VERSION "HNNBNNNYNNNNNNNNNNNNNNNNNNNNNNNNNNNNNNNNNN/4/%%%/4/'%**4NNN///"

NS_ :

BS_:

BU_: BAP_Tester BedienDisp_mi BedienDisp_vo_mi CDI ConMod_CD DashCAM Gateway_Max ICC_IO_Node LSH OCU RDK_RS3 Sound_MIB_ab_Gen3 STH ZR_MIB_EINSTIEG_ab_Gen3 ZR_MIB_OPTION_ab_Gen3 ZR_MIB_TOP_ab_Gen3

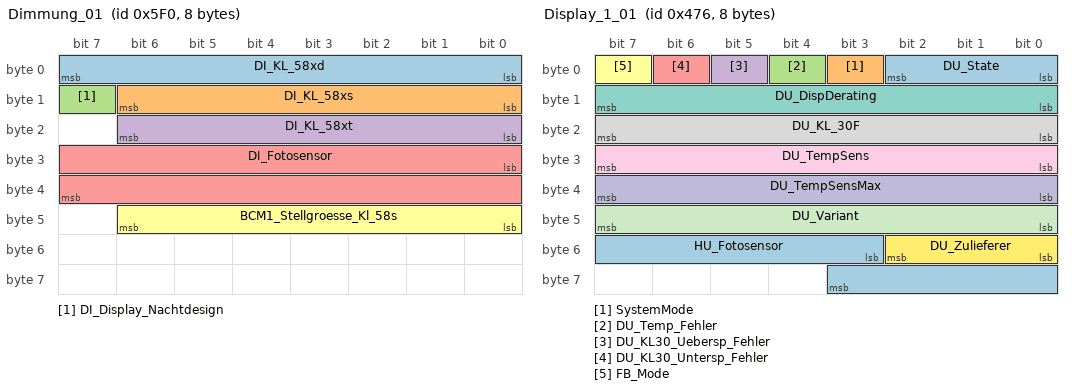
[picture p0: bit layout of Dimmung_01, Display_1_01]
BO_ 1520 Dimmung_01: 8 Gateway_Max
 SG_ DI_KL_58xd : 0|8@1+ (1,0) [0|253] ""  BedienDisp_mi,BedienDisp_vo_mi,CDI,ICC_IO_Node,OCU,ZR_MIB_EINSTIEG_ab_Gen3,ZR_MIB_OPTION_ab_Gen3,ZR_MIB_TOP_ab_Gen3
 SG_ DI_KL_58xs : 8|7@1+ (1,0) [0|100] "Unit_PerCent"  BedienDisp_vo_mi,CDI,ICC_IO_Node,OCU,ZR_MIB_EINSTIEG_ab_Gen3,ZR_MIB_OPTION_ab_Gen3,ZR_MIB_TOP_ab_Gen3
 SG_ DI_Display_Nachtdesign : 15|1@1+ (1.0,0.0) [0.0|1] ""  BedienDisp_vo_mi,CDI,ICC_IO_Node,ZR_MIB_EINSTIEG_ab_Gen3,ZR_MIB_OPTION_ab_Gen3,ZR_MIB_TOP_ab_Gen3
 SG_ DI_KL_58xt : 16|7@1+ (1,0) [0|100] "Unit_PerCent"  BedienDisp_mi,BedienDisp_vo_mi,CDI,ICC_IO_Node,OCU,ZR_MIB_EINSTIEG_ab_Gen3,ZR_MIB_OPTION_ab_Gen3,ZR_MIB_TOP_ab_Gen3
 SG_ DI_Fotosensor : 24|16@1+ (1,0) [0|65535] ""  ICC_IO_Node,OCU,ZR_MIB_EINSTIEG_ab_Gen3,ZR_MIB_OPTION_ab_Gen3,ZR_MIB_TOP_ab_Gen3
 SG_ BCM1_Stellgroesse_Kl_58s : 40|7@1+ (1,0) [0|100] ""  ICC_IO_Node,ZR_MIB_EINSTIEG_ab_Gen3,ZR_MIB_OPTION_ab_Gen3,ZR_MIB_TOP_ab_Gen3

BO_ 1142 Display_1_01: 8 ICC_IO_Node
 SG_ DU_State : 0|3@1+ (1.0,0.0) [0.0|7] ""  Gateway_Max
 SG_ SystemMode : 3|1@1+ (1.0,0.0) [0.0|1] ""  Vector__XXX
 SG_ DU_Temp_Fehler : 4|1@1+ (1.0,0.0) [0.0|1] ""  Gateway_Max
 SG_ DU_KL30_Uebersp_Fehler : 5|1@1+ (1.0,0.0) [0.0|1] ""  Gateway_Max
 SG_ DU_KL30_Untersp_Fehler : 6|1@1+ (1.0,0.0) [0.0|1] ""  Gateway_Max
 SG_ FB_Mode : 7|1@1+ (1.0,0.0) [0.0|1] ""  Vector__XXX
 SG_ DU_DispDerating : 8|8@1+ (1,0) [0|100] "Unit_PerCent"  Gateway_Max
 SG_ DU_KL_30F : 16|8@1+ (0.1,0) [0.0|25.3] "Unit_Volt"  Vector__XXX
 SG_ DU_TempSens : 24|8@1+ (1,-55) [-55|127] "Unit_DegreCelsi"  Gateway_Max
 SG_ DU_TempSensMax : 32|8@1+ (1,-55) [-55|127] "Unit_DegreCelsi"  Vector__XXX
 SG_ DU_Variant : 40|8@1+ (1,0) [0|253] ""  Vector__XXX
 SG_ DU_Zulieferer : 48|3@1+ (1,0) [0|7] ""  Vector__XXX
 SG_ HU_Fotosensor : 51|9@1+ (0.25,0) [0.00|100.00] "Unit_PerCent"  Vector__XXX

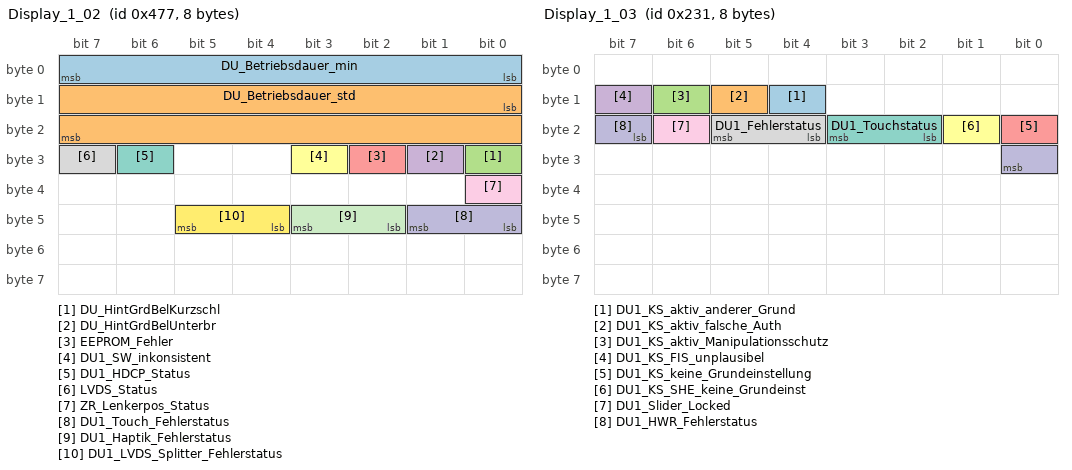
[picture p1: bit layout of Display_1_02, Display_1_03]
BO_ 1143 Display_1_02: 8 ICC_IO_Node
 SG_ DU_Betriebsdauer_min : 0|8@1+ (1,0) [0|59] "Unit_Minut"  Vector__XXX
 SG_ DU_Betriebsdauer_std : 8|16@1+ (1,0) [0|65533] "Unit_Hours"  Vector__XXX
 SG_ DU_HintGrdBelKurzschl : 24|1@1+ (1.0,0.0) [0.0|1] ""  Gateway_Max
 SG_ DU_HintGrdBelUnterbr : 25|1@1+ (1.0,0.0) [0.0|1] ""  Gateway_Max
 SG_ EEPROM_Fehler : 26|1@1+ (1.0,0.0) [0.0|1] ""  Vector__XXX
 SG_ DU1_SW_inkonsistent : 27|1@1+ (1.0,0.0) [0.0|1] ""  Gateway_Max
 SG_ DU1_HDCP_Status : 30|1@1+ (1.0,0.0) [0.0|1] ""  Vector__XXX
 SG_ LVDS_Status : 31|1@1+ (1.0,0.0) [0.0|1] ""  Gateway_Max
 SG_ ZR_Lenkerpos_Status : 32|1@1+ (1.0,0.0) [0.0|1] ""  Vector__XXX
 SG_ DU1_Touch_Fehlerstatus : 40|2@1+ (1.0,0.0) [0.0|3] ""  Gateway_Max
 SG_ DU1_Haptik_Fehlerstatus : 42|2@1+ (1.0,0.0) [0.0|3] ""  Gateway_Max
 SG_ DU1_LVDS_Splitter_Fehlerstatus : 44|2@1+ (1.0,0.0) [0.0|3] ""  Vector__XXX

BO_ 561 Display_1_03: 8 ICC_IO_Node
 SG_ DU1_KS_aktiv_anderer_Grund : 12|1@1+ (1.0,0.0) [0.0|1] ""  Vector__XXX
 SG_ DU1_KS_aktiv_falsche_Auth : 13|1@1+ (1.0,0.0) [0.0|1] ""  Vector__XXX
 SG_ DU1_KS_aktiv_Manipulationsschutz : 14|1@1+ (1.0,0.0) [0.0|1] ""  Vector__XXX
 SG_ DU1_KS_FIS_unplausibel : 15|1@1+ (1.0,0.0) [0.0|1] ""  Vector__XXX
 SG_ DU1_KS_keine_Grundeinstellung : 16|1@1+ (1.0,0.0) [0.0|1] ""  Vector__XXX
 SG_ DU1_KS_SHE_keine_Grundeinst : 17|1@1+ (1.0,0.0) [0.0|1] ""  Vector__XXX
 SG_ DU1_Touchstatus : 18|2@1+ (1.0,0.0) [0.0|3] ""  Vector__XXX
 SG_ DU1_Fehlerstatus : 20|2@1+ (1.0,0.0) [0.0|3] ""  Gateway_Max
 SG_ DU1_Slider_Locked : 22|1@1+ (1.0,0.0) [0.0|1] ""  Vector__XXX
 SG_ DU1_HWR_Fehlerstatus : 23|2@1+ (1.0,0.0) [0.0|3] ""  Vector__XXX

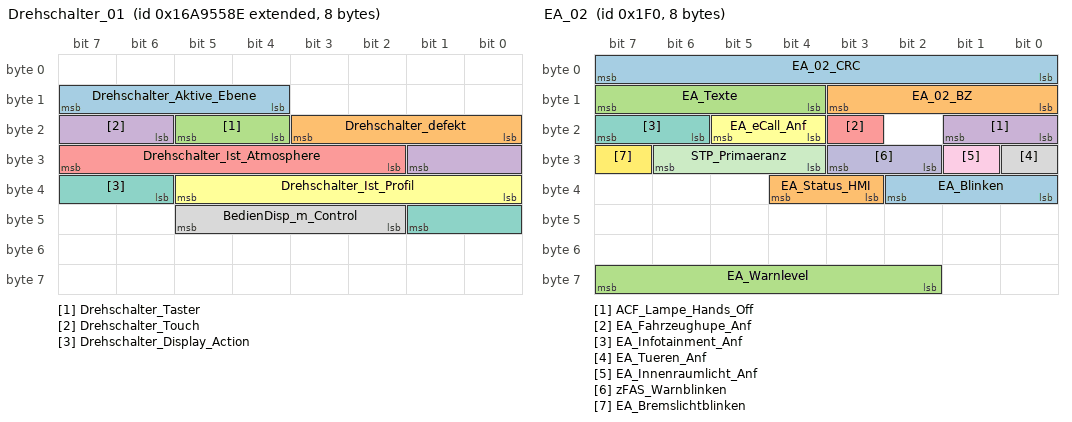
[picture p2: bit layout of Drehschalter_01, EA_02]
BO_ 2527679886 Drehschalter_01: 8 BedienDisp_mi
 SG_ Drehschalter_Aktive_Ebene : 12|4@1+ (1.0,0.0) [0.0|15] ""  Gateway_Max,ZR_MIB_OPTION_ab_Gen3
 SG_ Drehschalter_defekt : 16|4@1+ (1.0,0.0) [0.0|15] ""  Gateway_Max,ZR_MIB_OPTION_ab_Gen3
 SG_ Drehschalter_Taster : 20|2@1+ (1.0,0.0) [0.0|3] ""  Gateway_Max,ZR_MIB_OPTION_ab_Gen3
 SG_ Drehschalter_Touch : 22|4@1+ (1.0,0.0) [0.0|15] ""  Gateway_Max,ZR_MIB_OPTION_ab_Gen3
 SG_ Drehschalter_Ist_Atmosphere : 26|6@1+ (1.0,0.0) [0.0|63] ""  Gateway_Max,ZR_MIB_OPTION_ab_Gen3
 SG_ Drehschalter_Ist_Profil : 32|6@1+ (1.0,0.0) [0.0|63] ""  Gateway_Max
 SG_ Drehschalter_Display_Action : 38|4@1+ (1.0,0.0) [0.0|15] ""  Gateway_Max,ZR_MIB_OPTION_ab_Gen3
 SG_ BedienDisp_m_Control : 42|4@1+ (1.0,0.0) [0.0|15] ""  Gateway_Max,ZR_MIB_OPTION_ab_Gen3

BO_ 496 EA_02: 8 Gateway_Max
 SG_ EA_02_CRC : 0|8@1+ (1,0) [0|255] ""  Vector__XXX
 SG_ EA_02_BZ : 8|4@1+ (1,0) [0|15] ""  Vector__XXX
 SG_ EA_Texte : 12|4@1+ (1.0,0.0) [0.0|15] ""  Vector__XXX
 SG_ ACF_Lampe_Hands_Off : 16|2@1+ (1.0,0.0) [0.0|3] ""  Vector__XXX
 SG_ EA_Fahrzeughupe_Anf : 19|1@1+ (1.0,0.0) [0.0|1] ""  Vector__XXX
 SG_ EA_eCall_Anf : 20|2@1+ (1.0,0.0) [0.0|3] ""  ConMod_CD
 SG_ EA_Infotainment_Anf : 22|2@1+ (1.0,0.0) [0.0|3] ""  Vector__XXX
 SG_ EA_Tueren_Anf : 24|1@1+ (1.0,0.0) [0.0|1] ""  Vector__XXX
 SG_ EA_Innenraumlicht_Anf : 25|1@1+ (1.0,0.0) [0.0|1] ""  Vector__XXX
 SG_ zFAS_Warnblinken : 26|2@1+ (1.0,0.0) [0.0|3] ""  Vector__XXX
 SG_ STP_Primaeranz : 28|3@1+ (1.0,0.0) [0.0|7] ""  Vector__XXX
 SG_ EA_Bremslichtblinken : 31|1@1+ (1.0,0.0) [0.0|1] ""  Vector__XXX
 SG_ EA_Blinken : 32|3@1+ (1.0,0.0) [0.0|7] ""  Vector__XXX
 SG_ EA_Status_HMI : 35|2@1+ (1.0,0.0) [0.0|3] ""  Vector__XXX
 SG_ EA_Warnlevel : 58|6@1+ (1.0,0.0) [0.0|63] ""  Vector__XXX

BO_ 2583717656 eCall_AuthTime_Req: 8 ConMod_CD
 SG_ eCall_AuthTime_Req_Data : 0|64@1+ (1.0,0.0) [0.0|18446744073709551615] ""  Gateway_Max

BO_ 2583848728 eCall_AuthTime_Resp: 8 Gateway_Max
 SG_ eCall_AuthTime_Resp_Data : 0|64@1+ (1.0,0.0) [0.0|18446744073709551615] ""  ConMod_CD,OCU

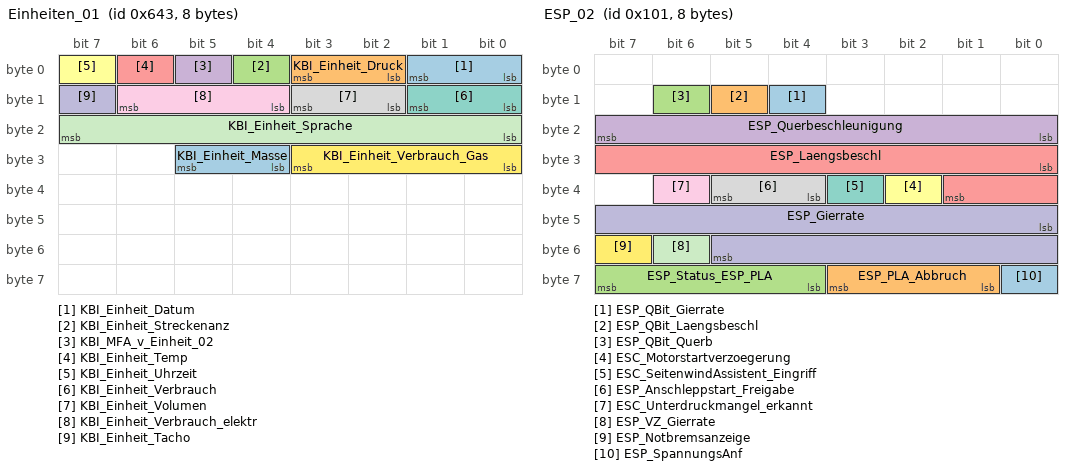
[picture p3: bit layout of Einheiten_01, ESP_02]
BO_ 1603 Einheiten_01: 8 Gateway_Max
 SG_ KBI_Einheit_Datum : 0|2@1+ (1.0,0.0) [0.0|3] ""  ZR_MIB_TOP_ab_Gen3
 SG_ KBI_Einheit_Druck : 2|2@1+ (1.0,0.0) [0.0|3] ""  RDK_RS3,ZR_MIB_TOP_ab_Gen3
 SG_ KBI_Einheit_Streckenanz : 4|1@1+ (1.0,0.0) [0.0|1] ""  ZR_MIB_TOP_ab_Gen3
 SG_ KBI_MFA_v_Einheit_02 : 5|1@1+ (1.0,0.0) [0.0|1] ""  ZR_MIB_TOP_ab_Gen3
 SG_ KBI_Einheit_Temp : 6|1@1+ (1.0,0.0) [0.0|1] ""  RDK_RS3,ZR_MIB_TOP_ab_Gen3
 SG_ KBI_Einheit_Uhrzeit : 7|1@1+ (1.0,0.0) [0.0|1] ""  ZR_MIB_TOP_ab_Gen3
 SG_ KBI_Einheit_Verbrauch : 8|2@1+ (1.0,0.0) [0.0|3] ""  OCU,ZR_MIB_TOP_ab_Gen3
 SG_ KBI_Einheit_Volumen : 10|2@1+ (1.0,0.0) [0.0|3] ""  ZR_MIB_TOP_ab_Gen3
 SG_ KBI_Einheit_Verbrauch_elektr : 12|3@1+ (1.0,0.0) [0.0|7] ""  Vector__XXX
 SG_ KBI_Einheit_Tacho : 15|1@1+ (1.0,0.0) [0.0|1] ""  Vector__XXX
 SG_ KBI_Einheit_Sprache : 16|8@1+ (1,0) [0|255] ""  BedienDisp_mi,BedienDisp_vo_mi,ConMod_CD,OCU,ZR_MIB_EINSTIEG_ab_Gen3,ZR_MIB_TOP_ab_Gen3
 SG_ KBI_Einheit_Verbrauch_Gas : 24|4@1+ (1.0,0.0) [0.0|15] ""  Vector__XXX
 SG_ KBI_Einheit_Masse : 28|2@1+ (1.0,0.0) [0.0|3] ""  ZR_MIB_TOP_ab_Gen3

BO_ 257 ESP_02: 8 Gateway_Max
 SG_ ESP_QBit_Gierrate : 12|1@1+ (1.0,0.0) [0.0|1] ""  OCU,ZR_MIB_EINSTIEG_ab_Gen3,ZR_MIB_OPTION_ab_Gen3,ZR_MIB_TOP_ab_Gen3
 SG_ ESP_QBit_Laengsbeschl : 13|1@1+ (1.0,0.0) [0.0|1] ""  DashCAM,OCU,ZR_MIB_EINSTIEG_ab_Gen3,ZR_MIB_OPTION_ab_Gen3,ZR_MIB_TOP_ab_Gen3
 SG_ ESP_QBit_Querb : 14|1@1+ (1.0,0.0) [0.0|1] ""  DashCAM,OCU,ZR_MIB_EINSTIEG_ab_Gen3,ZR_MIB_OPTION_ab_Gen3,ZR_MIB_TOP_ab_Gen3
 SG_ ESP_Querbeschleunigung : 16|8@1+ (0.01,-1.27) [-1.27|1.27] "Unit_ForceOfGravi"  OCU,ZR_MIB_EINSTIEG_ab_Gen3,ZR_MIB_OPTION_ab_Gen3,ZR_MIB_TOP_ab_Gen3
 SG_ ESP_Laengsbeschl : 24|10@1+ (0.03125,-16) [-16.00000|15.90625] "Unit_MeterPerSeconSquar"  DashCAM,OCU,ZR_MIB_EINSTIEG_ab_Gen3,ZR_MIB_OPTION_ab_Gen3,ZR_MIB_TOP_ab_Gen3
 SG_ ESC_Motorstartverzoegerung : 34|1@1+ (1.0,0.0) [0.0|1] ""  ZR_MIB_EINSTIEG_ab_Gen3
 SG_ ESC_SeitenwindAssistent_Eingriff : 35|1@1+ (1.0,0.0) [0.0|1] ""  Vector__XXX
 SG_ ESP_Anschleppstart_Freigabe : 36|2@1+ (1.0,0.0) [0.0|3] ""  ZR_MIB_EINSTIEG_ab_Gen3
 SG_ ESC_Unterdruckmangel_erkannt : 38|1@1+ (1.0,0.0) [0.0|1] ""  Vector__XXX
 SG_ ESP_Gierrate : 40|14@1+ (0.01,0) [0.00|163.82] "Unit_DegreOfArcPerSecon"  OCU,ZR_MIB_EINSTIEG_ab_Gen3,ZR_MIB_OPTION_ab_Gen3,ZR_MIB_TOP_ab_Gen3
 SG_ ESP_VZ_Gierrate : 54|1@1+ (1.0,0.0) [0.0|1] ""  OCU,ZR_MIB_EINSTIEG_ab_Gen3,ZR_MIB_OPTION_ab_Gen3,ZR_MIB_TOP_ab_Gen3
 SG_ ESP_Notbremsanzeige : 55|1@1+ (1.0,0.0) [0.0|1] ""  OCU,ZR_MIB_EINSTIEG_ab_Gen3
 SG_ ESP_SpannungsAnf : 56|1@1+ (1.0,0.0) [0.0|1] ""  Vector__XXX
 SG_ ESP_PLA_Abbruch : 57|3@1+ (1.0,0.0) [0.0|7] ""  Vector__XXX
 SG_ ESP_Status_ESP_PLA : 60|4@1+ (1.0,0.0) [0.0|15] ""  Vector__XXX

BO_ 262 ESP_05: 8 Gateway_Max
 SG_ ESP_QBit_Bremsdruck : 12|1@1+ (1.0,0.0) [0.0|1] ""  DashCAM,OCU
 SG_ ESP_QBit_Fahrer_bremst : 13|1@1+ (1.0,0.0) [0.0|1] ""  DashCAM,OCU
 SG_ ESP_Schwelle_Unterdruck : 14|2@1+ (1.0,0.0) [0.0|3] ""  Vector__XXX
 SG_ ESP_Bremsdruck : 16|10@1+ (0.3,-30) [-30.0|276.6] "Unit_Bar"  DashCAM,OCU,ZR_MIB_EINSTIEG_ab_Gen3,ZR_MIB_OPTION_ab_Gen3,ZR_MIB_TOP_ab_Gen3
 SG_ ESP_Fahrer_bremst : 26|1@1+ (1.0,0.0) [0.0|1] ""  DashCAM,OCU
 SG_ ESP_Verz_TSK_aktiv : 27|1@1+ (1.0,0.0) [0.0|1] ""  Vector__XXX
 SG_ ESP_Lenkeingriff_ADS : 28|1@1+ (1.0,0.0) [0.0|1] ""  Vector__XXX
 SG_ ESP_Konsistenz_TSK : 29|1@1+ (1.0,0.0) [0.0|1] ""  Vector__XXX
 SG_ ESP_Bremsruck_AWV2 : 30|1@1+ (1.0,0.0) [0.0|1] ""  Vector__XXX
 SG_ ESP_Konsistenz_AWV2 : 31|1@1+ (1.0,0.0) [0.0|1] ""  Vector__XXX
 SG_ ECD_Fehler : 32|1@1+ (1.0,0.0) [0.0|1] ""  Vector__XXX
 SG_ ECD_nicht_verfuegbar : 33|1@1+ (1.0,0.0) [0.0|1] ""  Vector__XXX
 SG_ ESP_Status_Bremsentemp : 34|1@1+ (1.0,0.0) [0.0|1] ""  OCU
 SG_ ESP_Autohold_Standby : 35|1@1+ (1.0,0.0) [0.0|1] ""  Vector__XXX
 SG_ ESP_HDC_Standby : 36|1@1+ (1.0,0.0) [0.0|1] ""  OCU,ZR_MIB_OPTION_ab_Gen3
 SG_ ESP_HBA_aktiv : 37|1@1+ (1.0,0.0) [0.0|1] ""  Vector__XXX
 SG_ ESP_Prefill_ausgeloest : 38|1@1+ (1.0,0.0) [0.0|1] ""  Vector__XXX
 SG_ ESP_Rueckwaertsfahrt_erkannt : 39|1@1+ (1.0,0.0) [0.0|1] ""  Vector__XXX
 SG_ ESP_Status_Anfahrhilfe : 40|1@1+ (1.0,0.0) [0.0|1] ""  Vector__XXX
 SG_ ESP_HDC_aktiv : 41|1@1+ (1.0,0.0) [0.0|1] ""  ZR_MIB_OPTION_ab_Gen3
 SG_ ESP_StartStopp_Info : 42|2@1+ (1.0,0.0) [0.0|3] ""  Vector__XXX
 SG_ ESP_Eingr_HL : 44|1@1+ (1.0,0.0) [0.0|1] ""  Vector__XXX
 SG_ ESP_Eingr_HR : 45|1@1+ (1.0,0.0) [0.0|1] ""  Vector__XXX
 SG_ ESP_Eingr_VL : 46|1@1+ (1.0,0.0) [0.0|1] ""  Vector__XXX
 SG_ ESP_Eingr_VR : 47|1@1+ (1.0,0.0) [0.0|1] ""  Vector__XXX
 SG_ ESP_BKV_Unterdruck : 48|8@1+ (4,0) [4|1012] "Unit_MilliBar"  Vector__XXX
 SG_ ESP_Autohold_aktiv : 56|1@1+ (1.0,0.0) [0.0|1] ""  Vector__XXX
 SG_ ESP_FStatus_Anfahrhilfe : 57|1@1+ (1.0,0.0) [0.0|1] ""  Vector__XXX
 SG_ ESP_Verz_EPB_aktiv : 58|1@1+ (1.0,0.0) [0.0|1] ""  Vector__XXX
 SG_ ECD_Bremslicht : 59|1@1+ (1.0,0.0) [0.0|1] ""  OCU
 SG_ ESP_Verzoeg_EPB_verf : 60|1@1+ (1.0,0.0) [0.0|1] ""  Vector__XXX
 SG_ ESP_Status_Bremsdruck : 61|1@1+ (1.0,0.0) [0.0|1] ""  OCU
 SG_ ESP_Anforderung_EPB : 62|2@1+ (1.0,0.0) [0.0|3] ""  Vector__XXX

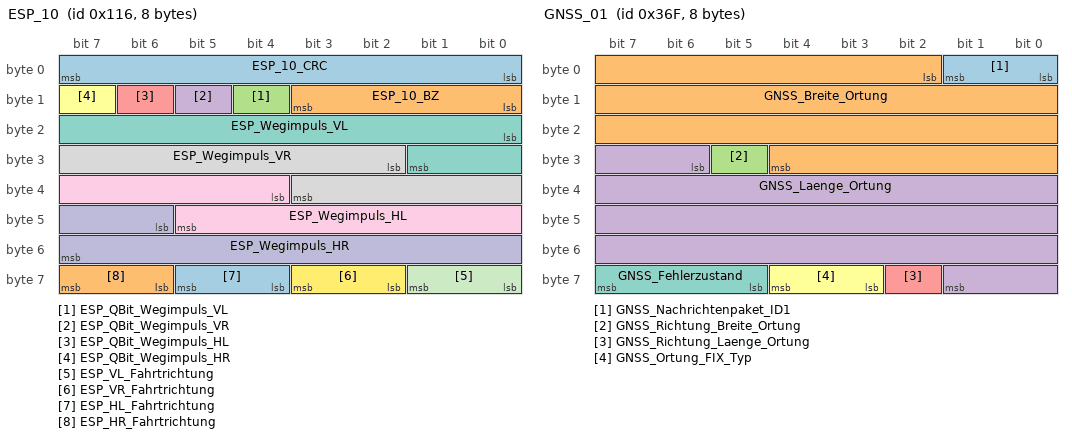
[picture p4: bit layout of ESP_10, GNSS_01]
BO_ 278 ESP_10: 8 Gateway_Max
 SG_ ESP_10_CRC : 0|8@1+ (1,0) [0|255] ""  Vector__XXX
 SG_ ESP_10_BZ : 8|4@1+ (1,0) [0|15] ""  ZR_MIB_EINSTIEG_ab_Gen3,ZR_MIB_OPTION_ab_Gen3
 SG_ ESP_QBit_Wegimpuls_VL : 12|1@1+ (1.0,0.0) [0.0|1] ""  OCU,ZR_MIB_EINSTIEG_ab_Gen3,ZR_MIB_OPTION_ab_Gen3,ZR_MIB_TOP_ab_Gen3
 SG_ ESP_QBit_Wegimpuls_VR : 13|1@1+ (1.0,0.0) [0.0|1] ""  OCU,ZR_MIB_EINSTIEG_ab_Gen3,ZR_MIB_OPTION_ab_Gen3,ZR_MIB_TOP_ab_Gen3
 SG_ ESP_QBit_Wegimpuls_HL : 14|1@1+ (1.0,0.0) [0.0|1] ""  OCU,ZR_MIB_EINSTIEG_ab_Gen3,ZR_MIB_OPTION_ab_Gen3,ZR_MIB_TOP_ab_Gen3
 SG_ ESP_QBit_Wegimpuls_HR : 15|1@1+ (1.0,0.0) [0.0|1] ""  OCU,ZR_MIB_EINSTIEG_ab_Gen3,ZR_MIB_OPTION_ab_Gen3,ZR_MIB_TOP_ab_Gen3
 SG_ ESP_Wegimpuls_VL : 16|10@1+ (1,0) [0|1000] ""  OCU,ZR_MIB_EINSTIEG_ab_Gen3,ZR_MIB_OPTION_ab_Gen3,ZR_MIB_TOP_ab_Gen3
 SG_ ESP_Wegimpuls_VR : 26|10@1+ (1,0) [0|1000] ""  OCU,ZR_MIB_EINSTIEG_ab_Gen3,ZR_MIB_OPTION_ab_Gen3,ZR_MIB_TOP_ab_Gen3
 SG_ ESP_Wegimpuls_HL : 36|10@1+ (1,0) [0|1000] ""  OCU,ZR_MIB_EINSTIEG_ab_Gen3,ZR_MIB_OPTION_ab_Gen3,ZR_MIB_TOP_ab_Gen3
 SG_ ESP_Wegimpuls_HR : 46|10@1+ (1,0) [0|1000] ""  OCU,ZR_MIB_EINSTIEG_ab_Gen3,ZR_MIB_OPTION_ab_Gen3,ZR_MIB_TOP_ab_Gen3
 SG_ ESP_VL_Fahrtrichtung : 56|2@1+ (1.0,0.0) [0.0|3] ""  OCU,ZR_MIB_EINSTIEG_ab_Gen3,ZR_MIB_OPTION_ab_Gen3,ZR_MIB_TOP_ab_Gen3
 SG_ ESP_VR_Fahrtrichtung : 58|2@1+ (1.0,0.0) [0.0|3] ""  OCU,ZR_MIB_EINSTIEG_ab_Gen3,ZR_MIB_OPTION_ab_Gen3,ZR_MIB_TOP_ab_Gen3
 SG_ ESP_HL_Fahrtrichtung : 60|2@1+ (1.0,0.0) [0.0|3] ""  OCU,ZR_MIB_EINSTIEG_ab_Gen3,ZR_MIB_OPTION_ab_Gen3,ZR_MIB_TOP_ab_Gen3
 SG_ ESP_HR_Fahrtrichtung : 62|2@1+ (1.0,0.0) [0.0|3] ""  OCU,RDK_RS3,ZR_MIB_EINSTIEG_ab_Gen3,ZR_MIB_OPTION_ab_Gen3,ZR_MIB_TOP_ab_Gen3

BO_ 1629 ESP_20: 8 Gateway_Max
 SG_ ESP_20_CRC : 0|8@1+ (1,0) [0|255] ""  Vector__XXX
 SG_ ESP_20_BZ : 8|4@1+ (1,0) [0|15] ""  Vector__XXX
 SG_ BR_Systemart : 12|2@1+ (1.0,0.0) [0.0|3] ""  ZR_MIB_EINSTIEG_ab_Gen3
 SG_ ESP_SpannungsAnf_02 : 14|2@1+ (1.0,0.0) [0.0|3] ""  Vector__XXX
 SG_ ESP_Zaehnezahl : 16|8@1+ (1,0) [0|255] ""  OCU,ZR_MIB_EINSTIEG_ab_Gen3,ZR_MIB_OPTION_ab_Gen3,ZR_MIB_TOP_ab_Gen3
 SG_ ESP_Charisma_FahrPr : 24|4@1+ (1.0,0.0) [0.0|15] ""  OCU
 SG_ ESP_Charisma_Status : 28|2@1+ (1.0,0.0) [0.0|3] ""  Vector__XXX
 SG_ ESP_Wiederstart_Anz_01 : 30|1@1+ (1.0,0.0) [0.0|1] ""  Vector__XXX
 SG_ ESP_Wiederstart_Anz_02 : 31|1@1+ (1.0,0.0) [0.0|1] ""  Vector__XXX
 SG_ ESP_Wiederstart_Anz_03 : 32|1@1+ (1.0,0.0) [0.0|1] ""  Vector__XXX
 SG_ ESP_Wiederstart_Anz_04 : 33|1@1+ (1.0,0.0) [0.0|1] ""  Vector__XXX
 SG_ ESP_Stoppverbot_Anz_01 : 34|1@1+ (1.0,0.0) [0.0|1] ""  Vector__XXX
 SG_ ESP_Stoppverbot_Anz_02 : 35|1@1+ (1.0,0.0) [0.0|1] ""  Vector__XXX
 SG_ ESP_Stoppverbot_Anz_03 : 36|1@1+ (1.0,0.0) [0.0|1] ""  Vector__XXX
 SG_ ESP_Stoppverbot_Anz_04 : 37|1@1+ (1.0,0.0) [0.0|1] ""  Vector__XXX
 SG_ ESP_Stoppverbot_Anz_05 : 38|1@1+ (1.0,0.0) [0.0|1] ""  Vector__XXX
 SG_ ESP_Stoppverbot_Anz_06 : 39|1@1+ (1.0,0.0) [0.0|1] ""  Vector__XXX
 SG_ ESP_Stoppverbot_Anz_07 : 40|1@1+ (1.0,0.0) [0.0|1] ""  Vector__XXX
 SG_ ESP_Stoppverbot_Anz_Std : 41|1@1+ (1.0,0.0) [0.0|1] ""  Vector__XXX
 SG_ ESP_Dachrelingsensor : 42|2@1+ (1.0,0.0) [0.0|3] ""  Vector__XXX
 SG_ ESP_Stoppverbot_Anz_08 : 44|1@1+ (1.0,0.0) [0.0|1] ""  Vector__XXX
 SG_ HDC_Charisma_FahrPr : 45|4@1+ (1.0,0.0) [0.0|15] ""  Vector__XXX
 SG_ HDC_Charisma_Status : 49|2@1+ (1.0,0.0) [0.0|3] ""  Vector__XXX
 SG_ BR_QBit_Reifenumfang : 51|1@1+ (1.0,0.0) [0.0|1] ""  OCU,ZR_MIB_EINSTIEG_ab_Gen3,ZR_MIB_TOP_ab_Gen3
 SG_ BR_Reifenumfang : 52|12@1+ (1,0) [0|4095] "Unit_MilliMeter"  OCU,ZR_MIB_EINSTIEG_ab_Gen3,ZR_MIB_TOP_ab_Gen3

BO_ 253 ESP_21: 8 Gateway_Max
 SG_ ESP_21_CRC : 0|8@1+ (1,0) [0|255] ""  LSH,STH
 SG_ ESP_21_BZ : 8|4@1+ (1,0) [0|15] ""  LSH,STH
 SG_ BR_Eingriffsmoment : 12|10@1+ (1,-509) [-509|509] ""  OCU
 SG_ ESP_PLA_Bremseingriff : 22|1@1+ (1.0,0.0) [0.0|1] ""  Vector__XXX
 SG_ ESP_Diagnose : 23|1@1+ (1.0,0.0) [0.0|1] ""  Vector__XXX
 SG_ ESC_Reku_Freigabe : 24|1@1+ (1.0,0.0) [0.0|1] ""  OCU
 SG_ ESC_v_Signal_Qualifier_High_Low : 25|3@1+ (1.0,0.0) [0.0|7] ""  OCU
 SG_ ESP_Vorsteuerung : 28|1@1+ (1.0,0.0) [0.0|1] ""  Vector__XXX
 SG_ ESP_AWV3_Brems_aktiv : 29|1@1+ (1.0,0.0) [0.0|1] ""  Vector__XXX
 SG_ OBD_Schlechtweg : 30|1@1+ (1.0,0.0) [0.0|1] ""  Vector__XXX
 SG_ OBD_QBit_Schlechtweg : 31|1@1+ (1.0,0.0) [0.0|1] ""  Vector__XXX
 SG_ ESP_v_Signal : 32|16@1+ (0.01,0) [0.00|655.32] "Unit_KiloMeterPerHour"  BedienDisp_mi,BedienDisp_vo_mi,ICC_IO_Node,LSH,OCU,RDK_RS3,STH,ZR_MIB_EINSTIEG_ab_Gen3,ZR_MIB_OPTION_ab_Gen3,ZR_MIB_TOP_ab_Gen3
 SG_ ASR_Tastung_passiv : 48|1@1+ (1.0,0.0) [0.0|1] ""  OCU
 SG_ ESP_Tastung_passiv : 49|1@1+ (1.0,0.0) [0.0|1] ""  OCU
 SG_ ESP_Systemstatus : 50|1@1+ (1.0,0.0) [0.0|1] ""  OCU
 SG_ ASR_Schalteingriff : 51|2@1+ (1.0,0.0) [0.0|3] ""  Vector__XXX
 SG_ ESP_Haltebestaetigung : 53|1@1+ (1.0,0.0) [0.0|1] ""  Vector__XXX
 SG_ ESP_MKB_Abbruch_Geschw : 54|1@1+ (1.0,0.0) [0.0|1] ""  OCU
 SG_ ESP_QBit_v_Signal : 55|1@1+ (1.0,0.0) [0.0|1] ""  ICC_IO_Node,LSH,OCU,RDK_RS3,STH,ZR_MIB_EINSTIEG_ab_Gen3,ZR_MIB_OPTION_ab_Gen3
 SG_ ABS_Bremsung : 56|1@1+ (1.0,0.0) [0.0|1] ""  OCU
 SG_ ASR_Anf : 57|1@1+ (1.0,0.0) [0.0|1] ""  OCU
 SG_ MSR_Anf : 58|1@1+ (1.0,0.0) [0.0|1] ""  Vector__XXX
 SG_ EBV_Eingriff : 59|1@1+ (1.0,0.0) [0.0|1] ""  OCU
 SG_ EDS_Eingriff : 60|1@1+ (1.0,0.0) [0.0|1] ""  OCU
 SG_ ESP_Eingriff : 61|1@1+ (1.0,0.0) [0.0|1] ""  DashCAM,OCU,ZR_MIB_EINSTIEG_ab_Gen3,ZR_MIB_OPTION_ab_Gen3
 SG_ ESP_ASP : 62|1@1+ (1.0,0.0) [0.0|1] ""  Vector__XXX
 SG_ ESP_Anhaltevorgang_ACC_aktiv : 63|1@1+ (1.0,0.0) [0.0|1] ""  Vector__XXX

BO_ 795 ESP_24: 8 Gateway_Max
 SG_ ESP_24_CRC : 0|8@1+ (1,0) [0|255] ""  OCU
 SG_ ESP_24_BZ : 8|4@1+ (1,0) [0|15] ""  OCU
 SG_ ESP_Lampe : 12|1@1+ (1.0,0.0) [0.0|1] ""  ZR_MIB_EINSTIEG_ab_Gen3,ZR_MIB_TOP_ab_Gen3
 SG_ ABS_Lampe : 13|1@1+ (1.0,0.0) [0.0|1] ""  OCU
 SG_ BK_Lampe_02 : 14|2@1+ (1.0,0.0) [0.0|3] ""  Vector__XXX
 SG_ TC_Lampe : 16|1@1+ (1.0,0.0) [0.0|1] ""  Vector__XXX
 SG_ ESP_m_Raddrehz : 17|15@1+ (0.002,0) [0.000|65.278] "Unit_Hertz"  OCU,ZR_MIB_EINSTIEG_ab_Gen3
 SG_ ESP_Textanzeigen_03 : 32|5@1+ (1.0,0.0) [0.0|31] ""  OCU,ZR_MIB_EINSTIEG_ab_Gen3
 SG_ ESP_Meldungen : 37|3@1+ (1.0,0.0) [0.0|7] ""  Vector__XXX
 SG_ ESP_Wegimp_VA : 40|11@1+ (1,0) [0|2047] ""  OCU,ZR_MIB_EINSTIEG_ab_Gen3,ZR_MIB_OPTION_ab_Gen3,ZR_MIB_TOP_ab_Gen3
 SG_ ESP_Fehlerstatus_Wegimp : 51|1@1+ (1.0,0.0) [0.0|1] ""  OCU,ZR_MIB_EINSTIEG_ab_Gen3,ZR_MIB_OPTION_ab_Gen3,ZR_MIB_TOP_ab_Gen3
 SG_ ESP_Wegimp_Ueberlauf : 52|1@1+ (1.0,0.0) [0.0|1] ""  OCU,ZR_MIB_EINSTIEG_ab_Gen3,ZR_MIB_OPTION_ab_Gen3,ZR_MIB_TOP_ab_Gen3
 SG_ ESP_QBit_Wegimp_VA : 53|1@1+ (1.0,0.0) [0.0|1] ""  OCU,ZR_MIB_EINSTIEG_ab_Gen3,ZR_MIB_OPTION_ab_Gen3,ZR_MIB_TOP_ab_Gen3
 SG_ ESP_HDC_FktLampe : 54|1@1+ (1.0,0.0) [0.0|1] ""  Vector__XXX
 SG_ ESP_Off_Lampe : 55|1@1+ (1.0,0.0) [0.0|1] ""  Vector__XXX
 SG_ ESP_HDC_Regelgeschw : 56|7@1+ (0.32,0) [0.32|39.68] "Unit_KiloMeterPerHour"  ZR_MIB_TOP_ab_Gen3
 SG_ ESP_BKV_Warnung : 63|1@1+ (1.0,0.0) [0.0|1] ""  Vector__XXX

BO_ 2589283617 ESP_30: 8 Gateway_Max
 SG_ ESP_30_CRC : 0|8@1+ (1,0) [0|255] ""  Vector__XXX
 SG_ ESP_30_BZ : 8|4@1+ (1,0) [0|15] ""  Vector__XXX
 SG_ EDS_Charisma_FahrPr : 12|4@1+ (1.0,0.0) [0.0|15] ""  Vector__XXX
 SG_ EDS_Charisma_Status : 16|2@1+ (1.0,0.0) [0.0|3] ""  Vector__XXX
 SG_ HHC_Charisma_Status : 18|2@1+ (1.0,0.0) [0.0|3] ""  Vector__XXX
 SG_ HHC_Charisma_FahrPr : 20|4@1+ (1.0,0.0) [0.0|15] ""  Vector__XXX
 SG_ RLE_Anzeigen : 24|3@1+ (1.0,0.0) [0.0|7] ""  Vector__XXX
 SG_ ESC_Lernfreigabe_Abrollumfang : 27|1@1+ (1.0,0.0) [0.0|1] ""  Vector__XXX
 SG_ ESC_Texte_eBKV_Betaetigung : 28|4@1+ (1.0,0.0) [0.0|15] ""  Vector__XXX
 SG_ ESC_MBK_Meldungen : 32|2@1+ (1.0,0.0) [0.0|3] ""  Vector__XXX
 SG_ ESC_Anf_KL : 34|5@1+ (3.22580645,0) [0E-8|99.99999995] "Unit_PerCent"  Vector__XXX
 SG_ ESC_Anf_KV : 39|1@1+ (1.0,0.0) [0.0|1] ""  Vector__XXX
 SG_ ESC_FBA_Meldungen : 40|2@1+ (1.0,0.0) [0.0|3] ""  Vector__XXX
 SG_ DBK_Fahrerwarnung : 42|2@1+ (1.0,0.0) [0.0|3] ""  Vector__XXX
 SG_ ESP_Status_Bremsentemp_Anz : 44|3@1+ (1.0,0.0) [0.0|7] ""  ZR_MIB_TOP_ab_Gen3
 SG_ ESP_Off_Anf_KBI : 47|1@1+ (1.0,0.0) [0.0|1] ""  Vector__XXX
 SG_ FBC_Fahrerwarnung : 48|2@1+ (1.0,0.0) [0.0|3] ""  Vector__XXX

BO_ 2589283684 FoD_01: 8 Gateway_Max
 SG_ GRA_FoD_Status : 58|2@1+ (1.0,0.0) [0.0|3] ""  Vector__XXX
 SG_ FoD_Transmission_Info : 60|2@1+ (1.0,0.0) [0.0|3] ""  Vector__XXX

BO_ 2549875571 FoD_ZR_Req: 8 Gateway_Max
 SG_ FoD_ZR_Req_Data : 0|64@1+ (1.0,0.0) [0.0|18446744073709551615] ""  ICC_IO_Node,ZR_MIB_EINSTIEG_ab_Gen3,ZR_MIB_OPTION_ab_Gen3,ZR_MIB_TOP_ab_Gen3

BO_ 2550006643 FoD_ZR_Resp: 8 ICC_IO_Node
 SG_ FoD_ZR_Resp_Data : 0|64@1+ (1.0,0.0) [0.0|18446744073709551615] ""  Gateway_Max

BO_ 986 Gateway_71: 8 Gateway_Max
 SG_ ESP_05_alt : 0|1@1+ (1.0,0.0) [0.0|1] ""  Vector__XXX
 SG_ EPB_01_alt : 1|1@1+ (1.0,0.0) [0.0|1] ""  OCU,ZR_MIB_EINSTIEG_ab_Gen3,ZR_MIB_OPTION_ab_Gen3,ZR_MIB_TOP_ab_Gen3
 SG_ ESP_21_alt : 2|1@1+ (1.0,0.0) [0.0|1] ""  ZR_MIB_TOP_ab_Gen3
 SG_ LWI_01_alt : 3|1@1+ (1.0,0.0) [0.0|1] ""  ZR_MIB_EINSTIEG_ab_Gen3,ZR_MIB_OPTION_ab_Gen3,ZR_MIB_TOP_ab_Gen3
 SG_ Parkhilfe_01_alt : 4|1@1+ (1.0,0.0) [0.0|1] ""  Vector__XXX
 SG_ Kamera_Status_alt : 5|1@1+ (1.0,0.0) [0.0|1] ""  OCU
 SG_ ESP_HDC_Standby : 6|1@1+ (1.0,0.0) [0.0|1] ""  Vector__XXX
 SG_ ECD_Bremslicht : 8|1@1+ (1.0,0.0) [0.0|1] ""  Vector__XXX
 SG_ EPB_Status : 9|2@1+ (1.0,0.0) [0.0|3] ""  OCU,ZR_MIB_EINSTIEG_ab_Gen3,ZR_MIB_OPTION_ab_Gen3,ZR_MIB_TOP_ab_Gen3
 SG_ EPB_QBit_Pedalweg_Kuppl : 11|1@1+ (1.0,0.0) [0.0|1] ""  OCU
 SG_ ESP_QBit_v_Signal : 12|1@1+ (1.0,0.0) [0.0|1] ""  ZR_MIB_TOP_ab_Gen3
 SG_ ABS_Bremsung : 13|1@1+ (1.0,0.0) [0.0|1] ""  Vector__XXX
 SG_ ESP_Eingriff : 14|1@1+ (1.0,0.0) [0.0|1] ""  Vector__XXX
 SG_ Kamera_FSH_aktiv : 15|1@1+ (1.0,0.0) [0.0|1] ""  OCU
 SG_ EPB_Pedalweg_Kuppl : 16|8@1+ (0.4,0) [8.0|92.0] "Unit_PerCent"  OCU
 SG_ ESP_v_Signal : 24|16@1+ (0.01,0) [0.00|655.32] "Unit_KiloMeterPerHour"  ZR_MIB_TOP_ab_Gen3
 SG_ LWI_QBit_Lenkradwinkel : 40|1@1+ (1.0,0.0) [0.0|1] ""  ZR_MIB_EINSTIEG_ab_Gen3,ZR_MIB_OPTION_ab_Gen3,ZR_MIB_TOP_ab_Gen3
 SG_ LWI_Sensorstatus : 41|1@1+ (1.0,0.0) [0.0|1] ""  ZR_MIB_EINSTIEG_ab_Gen3,ZR_MIB_OPTION_ab_Gen3,ZR_MIB_TOP_ab_Gen3
 SG_ LWI_VZ_Lenkradwinkel : 42|1@1+ (1.0,0.0) [0.0|1] ""  ZR_MIB_EINSTIEG_ab_Gen3,ZR_MIB_OPTION_ab_Gen3,ZR_MIB_TOP_ab_Gen3
 SG_ LWI_Lenkradwinkel : 43|13@1+ (0.1,0) [0.0|800.0] "Unit_DegreOfArc"  ZR_MIB_EINSTIEG_ab_Gen3,ZR_MIB_OPTION_ab_Gen3,ZR_MIB_TOP_ab_Gen3
 SG_ PH_Anf_Audioabsenkung : 56|1@1+ (1.0,0.0) [0.0|1] ""  Vector__XXX
 SG_ PH_Systemzustand : 57|3@1+ (1.0,0.0) [0.0|7] ""  Vector__XXX
 SG_ PH_Taster : 60|2@1+ (1.0,0.0) [0.0|3] ""  Vector__XXX
 SG_ ESP_MKB_Abbruch_Geschw : 62|1@1+ (1.0,0.0) [0.0|1] ""  Vector__XXX
 SG_ PLA_Anf_Aufschaltung_RVC : 63|1@1+ (1.0,0.0) [0.0|1] ""  Vector__XXX

BO_ 988 Gateway_73: 8 Gateway_Max
 SG_ Motor_12_alt : 0|1@1+ (1.0,0.0) [0.0|1] ""  ICC_IO_Node,LSH,OCU,STH,ZR_MIB_EINSTIEG_ab_Gen3,ZR_MIB_OPTION_ab_Gen3,ZR_MIB_TOP_ab_Gen3
 SG_ ESP_07_alt : 1|1@1+ (1.0,0.0) [0.0|1] ""  OCU,ZR_MIB_EINSTIEG_ab_Gen3,ZR_MIB_OPTION_ab_Gen3
 SG_ Getriebe_11_alt : 2|1@1+ (1.0,0.0) [0.0|1] ""  ZR_MIB_TOP_ab_Gen3
 SG_ Getriebe_13_alt : 3|1@1+ (1.0,0.0) [0.0|1] ""  OCU
 SG_ Getriebe_17_alt : 4|1@1+ (1.0,0.0) [0.0|1] ""  OCU
 SG_ TSK_06_alt : 5|1@1+ (1.0,0.0) [0.0|1] ""  OCU
 SG_ Getriebe_14_alt : 6|1@1+ (1.0,0.0) [0.0|1] ""  OCU
 SG_ ESP_50_alt : 7|1@1+ (1.0,0.0) [0.0|1] ""  OCU
 SG_ MO_QBit_Drehzahl_01 : 8|1@1+ (1.0,0.0) [0.0|1] ""  OCU,ZR_MIB_TOP_ab_Gen3
 SG_ MKE_Texte : 9|2@1+ (1.0,0.0) [0.0|3] ""  Vector__XXX
 SG_ MKE_Stufe : 11|3@1+ (1.0,0.0) [0.0|7] ""  Vector__XXX
 SG_ TSK_Hauptschalter_GRA_ACC : 14|2@1+ (1.0,0.0) [0.0|3] ""  OCU
 SG_ MO_Drehzahl_01 : 16|16@1+ (0.25,0) [0.00|16383.00] "Unit_MinutInver"  ICC_IO_Node,LSH,OCU,STH,ZR_MIB_EINSTIEG_ab_Gen3,ZR_MIB_OPTION_ab_Gen3,ZR_MIB_TOP_ab_Gen3
 SG_ TSK_Status : 32|3@1+ (1.0,0.0) [0.0|7] ""  OCU
 SG_ EPB_Schalterposition : 35|2@1+ (1.0,0.0) [0.0|3] ""  OCU
 SG_ GE_LaunchControl : 37|1@1+ (1.0,0.0) [0.0|1] ""  OCU
 SG_ GE_Fahrstufe : 40|4@1+ (1.0,0.0) [0.0|15] ""  CDI,ZR_MIB_TOP_ab_Gen3
 SG_ GE_Ursache_Fahrstufe_N : 44|1@1+ (1.0,0.0) [0.0|1] ""  Vector__XXX
 SG_ GE_Notlauf : 45|1@1+ (1.0,0.0) [0.0|1] ""  OCU
 SG_ ESP_Rollenmodus_Deaktivieren : 46|1@1+ (1.0,0.0) [0.0|1] ""  OCU,ZR_MIB_EINSTIEG_ab_Gen3,ZR_MIB_OPTION_ab_Gen3,ZR_MIB_TOP_ab_Gen3
 SG_ GE_Freilauf_Status : 47|3@1+ (1.0,0.0) [0.0|7] ""  OCU
 SG_ GE_Sperr_Info_WFS : 50|1@1+ (1.0,0.0) [0.0|1] ""  OCU
 SG_ TSK_Limiter_ausgewaehlt : 51|1@1+ (1.0,0.0) [0.0|1] ""  OCU
 SG_ GE_Veto_Rollfaehigkeit : 52|1@1+ (1.0,0.0) [0.0|1] ""  OCU
 SG_ EPB_Status_02 : 53|3@1+ (1.0,0.0) [0.0|7] ""  OCU
 SG_ ACC_Status_ACC : 56|3@1+ (1.0,0.0) [0.0|7] ""  OCU
 SG_ ACC_18_alt : 59|1@1+ (1.0,0.0) [0.0|1] ""  OCU
 SG_ Bel_DiETa_Mode2 : 60|2@1+ (1.0,0.0) [0.0|3] ""  Vector__XXX

BO_ 1002 Gateway_77: 8 Gateway_Max
 SG_ ESP_05_alt : 0|1@1+ (1.0,0.0) [0.0|1] ""  Vector__XXX
 SG_ Getriebe_14_alt : 1|1@1+ (1.0,0.0) [0.0|1] ""  OCU,ZR_MIB_EINSTIEG_ab_Gen3,ZR_MIB_OPTION_ab_Gen3,ZR_MIB_TOP_ab_Gen3
 SG_ Motor_11_alt : 2|1@1+ (1.0,0.0) [0.0|1] ""  ZR_MIB_EINSTIEG_ab_Gen3,ZR_MIB_OPTION_ab_Gen3
 SG_ Motor_20_alt : 3|1@1+ (1.0,0.0) [0.0|1] ""  OCU,ZR_MIB_EINSTIEG_ab_Gen3,ZR_MIB_OPTION_ab_Gen3
 SG_ EBKV_03_alt : 4|1@1+ (1.0,0.0) [0.0|1] ""  OCU
 SG_ AWV_03_alt : 5|1@1+ (1.0,0.0) [0.0|1] ""  ConMod_CD,OCU
 SG_ AWV_Verz_Freigabe : 6|1@1+ (1.0,0.0) [0.0|1] ""  OCU
 SG_ AWV_Verz_Anf : 7|10@1+ (0.024,-20.016) [-20.016|4.512] "Unit_MeterPerSeconSquar"  OCU
 SG_ Bel_DiETa_Mode : 17|2@1+ (1.0,0.0) [0.0|3] ""  Vector__XXX
 SG_ PaCo_DiETa_LED : 19|2@1+ (1.0,0.0) [0.0|3] ""  OCU
 SG_ RTM_Warnstatus : 21|2@1+ (1.0,0.0) [0.0|3] ""  Vector__XXX
 SG_ EBKV_Fahrer_bremst : 23|1@1+ (1.0,0.0) [0.0|1] ""  OCU
 SG_ AWV_Zielobjekttyp : 24|4@1+ (1.0,0.0) [0.0|15] ""  ConMod_CD,OCU
 SG_ ESP_Bremsdruck : 28|10@1+ (0.3,-30) [-30.0|276.6] "Unit_Bar"  Vector__XXX
 SG_ MO_Mom_Ist_Summe : 38|10@1+ (1,-509) [-509|509] ""  Vector__XXX
 SG_ MO_Fahrpedalrohwert_01 : 48|8@1+ (0.4,0) [0.0|101.6] "Unit_PerCent"  Vector__XXX
 SG_ GE_Sumpftemperatur : 56|8@1+ (1,-58) [-58|196] "Unit_DegreCelsi"  OCU,ZR_MIB_EINSTIEG_ab_Gen3,ZR_MIB_OPTION_ab_Gen3,ZR_MIB_TOP_ab_Gen3

BO_ 1004 Gateway_79: 8 Gateway_Max
 SG_ HDSG_01_alt : 0|1@1+ (1.0,0.0) [0.0|1] ""  Vector__XXX
 SG_ ACC_02_alt : 1|1@1+ (1.0,0.0) [0.0|1] ""  Vector__XXX
 SG_ BCM_01_alt : 2|1@1+ (1.0,0.0) [0.0|1] ""  Vector__XXX
 SG_ Klima_11_alt : 3|1@1+ (1.0,0.0) [0.0|1] ""  Vector__XXX
 SG_ Motor_17_alt : 4|1@1+ (1.0,0.0) [0.0|1] ""  Vector__XXX
 SG_ LDW_02_alt : 5|1@1+ (1.0,0.0) [0.0|1] ""  Vector__XXX
 SG_ EM1_01_alt : 6|1@1+ (1.0,0.0) [0.0|1] ""  Vector__XXX
 SG_ EM2_01_alt : 7|1@1+ (1.0,0.0) [0.0|1] ""  Vector__XXX
 SG_ LIN_2_alt : 8|1@1+ (1.0,0.0) [0.0|1] ""  ICC_IO_Node,ZR_MIB_EINSTIEG_ab_Gen3,ZR_MIB_OPTION_ab_Gen3,ZR_MIB_TOP_ab_Gen3
 SG_ Getriebe_50_alt : 9|1@1+ (1.0,0.0) [0.0|1] ""  Vector__XXX
 SG_ GE_Status_Kraftschluss : 33|3@1+ (1.0,0.0) [0.0|7] ""  Vector__XXX
 SG_ MFL_Touch_Event : 36|4@1+ (1.0,0.0) [0.0|15] ""  ICC_IO_Node,ZR_MIB_EINSTIEG_ab_Gen3,ZR_MIB_OPTION_ab_Gen3,ZR_MIB_TOP_ab_Gen3
 SG_ MO_NGS_Position : 40|1@1+ (1.0,0.0) [0.0|1] ""  Vector__XXX
 SG_ MO_NGS_Status : 41|2@1+ (1.0,0.0) [0.0|3] ""  Vector__XXX
 SG_ HC_Uss_Anforderung : 43|1@1+ (1.0,0.0) [0.0|1] ""  Vector__XXX
 SG_ BCM_Waschwasser_Sensor : 44|1@1+ (1.0,0.0) [0.0|1] ""  Vector__XXX
 SG_ BCM_Offroad_Taste : 45|1@1+ (1.0,0.0) [0.0|1] ""  Vector__XXX
 SG_ EM1_Status_DrzEingriff : 46|2@1+ (1.0,0.0) [0.0|3] ""  Vector__XXX
 SG_ KL_Vorwarn_Komp_ein : 48|1@1+ (1.0,0.0) [0.0|1] ""  Vector__XXX
 SG_ HD_Endstellung_oben : 49|1@1+ (1.0,0.0) [0.0|1] ""  Vector__XXX
 SG_ HD_Endstellung_unten : 50|1@1+ (1.0,0.0) [0.0|1] ""  Vector__XXX
 SG_ EM2_Status_DrzEingriff : 51|2@1+ (1.0,0.0) [0.0|3] ""  Vector__XXX
 SG_ ACC_Status_Anzeige : 53|3@1+ (1.0,0.0) [0.0|7] ""  Vector__XXX
 SG_ HD_Position : 56|8@1+ (1,0) [0|100] "Unit_PerCent"  Vector__XXX

BO_ 879 GNSS_01: 8 OCU
 SG_ GNSS_Nachrichtenpaket_ID1 : 0|2@1+ (1,0) [0|3] "Unit_Bit"  Gateway_Max,ZR_MIB_EINSTIEG_ab_Gen3,ZR_MIB_TOP_ab_Gen3
 SG_ GNSS_Breite_Ortung : 2|27@1+ (0.000001,0) [0.000000|90.000000] "Unit_DegreOfArc"  Gateway_Max,ZR_MIB_EINSTIEG_ab_Gen3,ZR_MIB_TOP_ab_Gen3
 SG_ GNSS_Richtung_Breite_Ortung : 29|1@1+ (1.0,0.0) [0.0|1] ""  Gateway_Max,ZR_MIB_EINSTIEG_ab_Gen3,ZR_MIB_TOP_ab_Gen3
 SG_ GNSS_Laenge_Ortung : 30|28@1+ (0.000001,0) [0.000000|180.000000] "Unit_DegreOfArc"  Gateway_Max,ZR_MIB_EINSTIEG_ab_Gen3,ZR_MIB_TOP_ab_Gen3
 SG_ GNSS_Richtung_Laenge_Ortung : 58|1@1+ (1.0,0.0) [0.0|1] ""  Gateway_Max,ZR_MIB_EINSTIEG_ab_Gen3,ZR_MIB_TOP_ab_Gen3
 SG_ GNSS_Ortung_FIX_Typ : 59|2@1+ (1.0,0.0) [0.0|3] ""  Gateway_Max,ZR_MIB_EINSTIEG_ab_Gen3,ZR_MIB_TOP_ab_Gen3
 SG_ GNSS_Fehlerzustand : 61|3@1+ (1.0,0.0) [0.0|7] ""  Gateway_Max,ZR_MIB_EINSTIEG_ab_Gen3,ZR_MIB_TOP_ab_Gen3

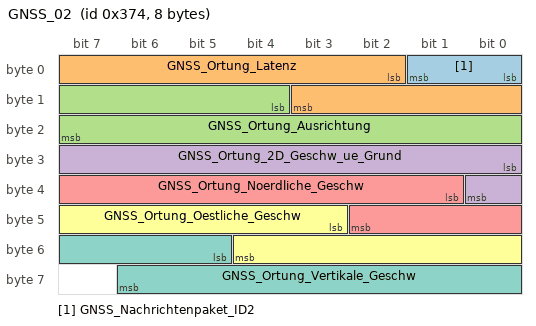
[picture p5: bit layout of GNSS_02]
BO_ 884 GNSS_02: 8 OCU
 SG_ GNSS_Nachrichtenpaket_ID2 : 0|2@1+ (1,0) [0|3] "Unit_Bit"  Gateway_Max,ZR_MIB_EINSTIEG_ab_Gen3,ZR_MIB_TOP_ab_Gen3
 SG_ GNSS_Ortung_Latenz : 2|10@1+ (1,0) [0|1021] "Unit_MilliSecon"  Gateway_Max,ZR_MIB_EINSTIEG_ab_Gen3,ZR_MIB_TOP_ab_Gen3
 SG_ GNSS_Ortung_Ausrichtung : 12|12@1+ (0.1,0) [0.0|359.9] "Unit_DegreOfArc"  Gateway_Max,ZR_MIB_EINSTIEG_ab_Gen3,ZR_MIB_TOP_ab_Gen3
 SG_ GNSS_Ortung_2D_Geschw_ue_Grund : 24|9@1+ (0.25,0) [0.00|125.00] "Unit_MeterPerSecon"  Gateway_Max,ZR_MIB_EINSTIEG_ab_Gen3,ZR_MIB_TOP_ab_Gen3
 SG_ GNSS_Ortung_Noerdliche_Geschw : 33|10@1+ (0.25,-125) [-125.00|125.00] "Unit_MeterPerSecon"  Gateway_Max,ZR_MIB_EINSTIEG_ab_Gen3,ZR_MIB_TOP_ab_Gen3
 SG_ GNSS_Ortung_Oestliche_Geschw : 43|10@1+ (0.25,-125) [-125.00|125.00] "Unit_MeterPerSecon"  Gateway_Max,ZR_MIB_EINSTIEG_ab_Gen3,ZR_MIB_TOP_ab_Gen3
 SG_ GNSS_Ortung_Vertikale_Geschw : 53|10@1+ (0.25,-125) [-125.00|125.00] "Unit_MeterPerSecon"  Gateway_Max,ZR_MIB_EINSTIEG_ab_Gen3,ZR_MIB_TOP_ab_Gen3

BO_TX_BU_ 1142 :ICC_IO_Node,ZR_MIB_EINSTIEG_ab_Gen3,ZR_MIB_OPTION_ab_Gen3,ZR_MIB_TOP_ab_Gen3;
BO_TX_BU_ 1143 :ICC_IO_Node,ZR_MIB_EINSTIEG_ab_Gen3,ZR_MIB_OPTION_ab_Gen3,ZR_MIB_TOP_ab_Gen3;
BO_TX_BU_ 561 :ICC_IO_Node,ZR_MIB_EINSTIEG_ab_Gen3,ZR_MIB_OPTION_ab_Gen3,ZR_MIB_TOP_ab_Gen3;
BO_TX_BU_ 2583717656 :ConMod_CD,OCU;
BO_TX_BU_ 2550006643 :ICC_IO_Node,ZR_MIB_EINSTIEG_ab_Gen3,ZR_MIB_OPTION_ab_Gen3,ZR_MIB_TOP_ab_Gen3;
CM_ BO_ 1520 "ab MQB nach abgestimmten FLH Dimmung";
CM_ BO_ 1603 "ab MQB mit 8 Byte";
CM_ BO_ 1629 "neu im MQB";
CM_ BO_ 253 "Neue Momente im MQB
Struktur ab MQB mit CRC8 entstanden aus ESP_01";
CM_ BO_ 795 "neu für MQB wg. Absicherung
Entstanden aus ESP_04";
CM_ BO_ 986 "Fahrwerk, Extended -> Komfort, Infotainment";
CM_ BO_ 988 "Antrieb, Fahrwerk -> Extended, Infotainment, Komfort";
CM_ BO_ 1002 "ACAN, FCAN --> ICAN";
CM_ BO_ 1004 "Extended, Komfort  -> Fahrwerk";
CM_ BO_ 879 "Nachricht 1 für Ortung:
Position und Fixtyp.";
CM_ BO_ 884 "Nachricht 2 für Ortung:
Latenz, Geschwindigkeit und Richtung.";

CM_ SG_ 1520 BCM1_Stellgroesse_Kl_58s "Rohwert Dimmpoti";
CM_ SG_ 1520 DI_Display_Nachtdesign "Für Displays sind oft  automatische Umschaltungen von Tag-/Nachtdesign vorgesehen.
Es gibt jedoch Zustände, an denen auch tagsüber das Abblendlicht eingeschaltet ist.
z.B. Dauerfahrlicht, Geschwindigkeitsabhängiges 'Licht-An-Bei-Autobahn', 'Regenlicht',";
CM_ SG_ 1520 DI_Fotosensor "Helligkeitswert Fotosensor
Für die Dimmung relevanter Wert zur Sensierung der Umgebungshelligkeit
Im Detail beschrieben im 'Funktionslastenheft Dimmung MQB'.";
CM_ SG_ 1520 DI_KL_58xd "Klemme 58xd Display- und Funktionsbeleuchtung
Mit der Klemme 58xd wird die Helligkeit der Display- und der Funktionsbeleuchtungen der Schalter gesteuert.
Im Detail beschrieben im 'Funktionslastenheft Dimmung MQB'.";
CM_ SG_ 1520 DI_KL_58xs "Suchbeleuchtung Schalter
EIN-AUS-Schaltalgorithmus der allgemeinen Schaltersuchbeleuchtung. 
Im Detail beschrieben im 'Funktionslastenheft Dimmung MQB'.
";
CM_ SG_ 1520 DI_KL_58xt "Timergesteuerte Suchbeleuchtung
Der EIN-AUS-Schaltalgorithmus für die vor- und nachlaufende Schaltersuchbeleuchtungen beim Ein- & Aussteigen; z.B.: Start/Stop-Taster.
Im Detail beschrieben im 'Funktionslastenheft Dimmung MQB'.";

CM_ SG_ 1142 DU_DispDerating "Begrenzung der Verlustleistung in Abhaengigkeit der Temperatur";
CM_ SG_ 1142 DU_KL30_Uebersp_Fehler "Display Unit Erkannter Überspannungsfehler";
CM_ SG_ 1142 DU_KL30_Untersp_Fehler "Display Unit Erkannter Unterspannungsfehler";
CM_ SG_ 1142 DU_KL_30F "Gemessene Versorgungsspannung des Displays.
";
CM_ SG_ 1142 DU_State "Power state des Displays.";
CM_ SG_ 1142 DU_Temp_Fehler "Die Display Unit hat einen Temperaturfehler erkannt.";
CM_ SG_ 1142 DU_TempSens "Display Unit aktueller Temperaturwert";
CM_ SG_ 1142 DU_TempSensMax "Gespeicherte maximale Sensortemperatur . Wert bleibt über Ruhestrom erhalten.";
CM_ SG_ 1142 DU_Variant "Variante der Display Unit
siehe MIB_ABT_EEPROM-AdjustDeviceNr_V01E_20100715_woj.xls";
CM_ SG_ 1142 DU_Zulieferer "Zulieferer des Displays.
Je nach eingesetztem Display müssen für das HMI unterschiedliche Grafiken verwendet werden damit die angezeigten Bilder immer identisch aussehen.";
CM_ SG_ 1142 FB_Mode "Steuergerät ist im Fernbedienmodus";
CM_ SG_ 1142 HU_Fotosensor "Messwert Fotosensor der Headunit (PCM bzw. CDR) 
logarithmisch verzerrt (siehe Funktionsbeschreibung Nachtdesign - entsprechend Audi-Spec)
PCM/CDR_Signal";

CM_ SG_ 1143 DU1_Haptik_Fehlerstatus "Haptik_Fehlerstatus = 0 kein Fehler erkannt
Haptik_Fehlerstatus = 1 SW Fehler erkannt
Haptik_Fehlerstatus = 2 HW Fehler erkannt";
CM_ SG_ 1143 DU1_HDCP_Status "Aktueller HDCP Status";
CM_ SG_ 1143 DU1_LVDS_Splitter_Fehlerstatus "LVDS_Splitter_Fehlerstatus = 0 kein Fehler erkannt
LVDS_Splitter_Fehlerstatus = 1 SW Fehler erkannt
LVDS_Splitter_Fehlerstatus = 2 HW Fehler erkannt";
CM_ SG_ 1143 DU1_SW_inkonsistent "SW_inkonsistent= 1 SW Status ist inkonsistent - Fehler
SW_inkonsistent = 0 kien Fehler - SW ist konsistent";
CM_ SG_ 1143 DU1_Touch_Fehlerstatus "Touch_Fehlerstatus = 0 kein Fehler erkannt
Touch_Fehlerstatus = 1 SW Fehler erkannt
Touch_Fehlerstatus = 2 HW Fehler erkannt";
CM_ SG_ 1143 DU_Betriebsdauer_min "Display Betriebsdauer Minutenanteil";
CM_ SG_ 1143 DU_Betriebsdauer_std "Display Betriebsdauer Stundenanteil";
CM_ SG_ 1143 DU_HintGrdBelKurzschl "Hintergrundbeleuchtung hat einen Kurzschluß.";
CM_ SG_ 1143 DU_HintGrdBelUnterbr "Ueber Strommessungen, mindestens ein LED Strang unterbrochen.";
CM_ SG_ 1143 EEPROM_Fehler "EEPROM Defekt erkannt.";
CM_ SG_ 1143 LVDS_Status "LVDS_Lock= 1 Statussignal in der DU Ein valides Videosignal zum Anzeigen liegt an 
LVDS_Unlocked = 0 kein Videosignal liegt an ";
CM_ SG_ 1143 ZR_Lenkerpos_Status "Im ABT gespeicherte Lenkradposition. Die Lenkradposition wird wie im Signal ZR_Lenkerposition gesendet nach einer Qualifizierungszeit von voraussichtlich 10 Botschaften übernommen.";

CM_ SG_ 561 DU1_Fehlerstatus "Indicates the error status of the ABT.";
CM_ SG_ 561 DU1_HWR_Fehlerstatus "HWR_Fehlerstatus = 0 kein Fehler erkannt
HWR_Fehlerstatus = 1 SW Fehler erkannt
HWR_Fehlerstatus = 2 HW Fehler erkannt";
CM_ SG_ 561 DU1_KS_aktiv_anderer_Grund "DTC Display Unit Komponentenschutz - Aktiv (anderer Grund)";
CM_ SG_ 561 DU1_KS_aktiv_falsche_Auth "DTC Display Unit Komponentenschutz - Aktiv (Falschauthentifikation)";
CM_ SG_ 561 DU1_KS_aktiv_Manipulationsschutz "DTC Display Unit Komponentenschutz - Aktiv (Manipulationsschutz)";
CM_ SG_ 561 DU1_KS_FIS_unplausibel "DTC Display Unit Komponentenschutz - FAZIT-Identifikation unplausibel";
CM_ SG_ 561 DU1_KS_keine_Grundeinstellung "DTC Display Unit Komponentenschutz - keine oder falsche Grundeinstellung";
CM_ SG_ 561 DU1_KS_SHE_keine_Grundeinst "DTC Display Unit Komponentenschutz - SHE-Schlüssel keine oder falsche Grundeinstellung";
CM_ SG_ 561 DU1_Slider_Locked "Gives Status from ABT slider if slider is locked or unlocked. Signal mapped according to the hard wiring between ABT and DiETa.";
CM_ SG_ 561 DU1_Touchstatus "Status if display unit (DU) is touched or not.";

CM_ SG_ 2527679886 BedienDisp_m_Control "Describes the function (values) when turning the  ring on the rotary knob..

Rotary_Up - knob is turn right side
Rotary_Down - knob is turn left side 
Mute - Mute request to function master";
CM_ SG_ 2527679886 Drehschalter_Aktive_Ebene "FES 2.0 gibt die angezeigte Ebene an";
CM_ SG_ 2527679886 Drehschalter_defekt "Status vom FES 2.0";
CM_ SG_ 2527679886 Drehschalter_Display_Action "Signale von dem Touchbedienfelde des FES 2.0.";
CM_ SG_ 2527679886 Drehschalter_Ist_Atmosphere "Gibt das momentan dargestellte Profil für Atmosphere an";
CM_ SG_ 2527679886 Drehschalter_Ist_Profil "Gibt das momentan dargestellte Profil an";
CM_ SG_ 2527679886 Drehschalter_Taster "Betätigungszustand  Drehschalter FES2.0";
CM_ SG_ 2527679886 Drehschalter_Touch "Touchsignale des FES 2.0";

CM_ SG_ 496 ACF_Lampe_Hands_Off "Anzeige, ob der Fahrer die Hände am Lenkrad hat.";
CM_ SG_ 496 EA_02_BZ "Botschaftszähler";
CM_ SG_ 496 EA_02_CRC "Für MLB:
'Berechnung siehe Lastenheft 'Kommunikationsabsicherung für Flexray und CAN''

Ab MQB und MLBevo:
'Berechnung siehe Lastenheft 'End-to-End Kommunikationsabsicherung'

Endwerte siehe Begleitdokument 'S-PDU Kennungsfolge'";
CM_ SG_ 496 EA_Blinken "Emergency Assist Anforderung Blinker";
CM_ SG_ 496 EA_Bremslichtblinken "Die Funktion Emergency Alert fordert ein Blinken der Bremsleuchten an.";
CM_ SG_ 496 EA_eCall_Anf "Emergency Assist Anforderung eCall";
CM_ SG_ 496 EA_Fahrzeughupe_Anf "Emergency Assist Anforderung Fahrzeughupe";
CM_ SG_ 496 EA_Infotainment_Anf "Emergency Assist Anforderung Absenkung Infotainment-Funktionen";
CM_ SG_ 496 EA_Innenraumlicht_Anf "Anforderung Innenraumbeleuchtung durch den Emergency Assist";
CM_ SG_ 496 EA_Status_HMI "Anzeige Emergency Assist-Statusleuchte im Fahrerinformationsdisplay";
CM_ SG_ 496 EA_Texte "Anzeige der EA Texte";
CM_ SG_ 496 EA_Tueren_Anf "Emergency Assist Anforderung Türen entriegeln";
CM_ SG_ 496 EA_Warnlevel "Kritikalität der Funktion Emergency Assist";
CM_ SG_ 496 STP_Primaeranz "Primäranzeige des Staupiloten";
CM_ SG_ 496 zFAS_Warnblinken "Anforderung Warnblinken durch zFAS Funktionen.";

CM_ SG_ 2583717656 eCall_AuthTime_Req_Data "AuthTime - Authentische Zeit
ISO-TP Datenkanal - NA2FID
Request Knoten 0x67 eCall (OCU)

OCU an Funktion Authentische Zeit (Request)";

CM_ SG_ 2583848728 eCall_AuthTime_Resp_Data "AuthTime - Authentische Zeit
ISO-TP Datenkanal - NA2FID
Response Funktion 0x18 AuthTime

Funktion Authentische Zeit an OCU (Response)";

CM_ SG_ 1603 KBI_Einheit_Datum "Anzeigevariante des Datums";
CM_ SG_ 1603 KBI_Einheit_Druck "Einheit des Druckes";
CM_ SG_ 1603 KBI_Einheit_Masse "Einheit der Masse (Verwendung z.B. ASTA)";
CM_ SG_ 1603 KBI_Einheit_Sprache "Siehe BAP-Datenfestlegung UnitMaster";
CM_ SG_ 1603 KBI_Einheit_Streckenanz "Einheit der Streckenanzeige";
CM_ SG_ 1603 KBI_Einheit_Tacho "Information, ob es sich um Meilen- oder Kmh-Kombi handelt, Einheit des Tachos entspricht dem Zifferblatt, Grösse ist nicht veränderlich";
CM_ SG_ 1603 KBI_Einheit_Temp "Einheit der Temperatur";
CM_ SG_ 1603 KBI_Einheit_Uhrzeit "Anzeigevariante der Uhrzeit";
CM_ SG_ 1603 KBI_Einheit_Verbrauch "Einheit der Verbrauchs";
CM_ SG_ 1603 KBI_Einheit_Verbrauch_elektr "Einheit elektrischer Verbrauch";
CM_ SG_ 1603 KBI_Einheit_Verbrauch_Gas "Unterscheidung zwischen M3/h und kg/h für Komfortverbrauchsberechnung.";
CM_ SG_ 1603 KBI_Einheit_Volumen "Einheit des Volumens";
CM_ SG_ 1603 KBI_MFA_v_Einheit_02 "Einheit der Geschwindigkeit, die vom Fahrer im Car-Menü gewählt wurde. Veränderliche Grösse, im Gegensatz zur Einheit des Tachokranzes.

Redundant in der Einheiten_01 Botschaft definiert, um Konsistenz zur BAP-Festlegung zu haben.";

CM_ SG_ 257 ESC_Motorstartverzoegerung "Mit dem Signal 'Motorstartverzögerung' wird den aktiven Teilnehmern ermöglicht, einen Motorstart durch die Start-Stop-Funktion zu verzögern.";
CM_ SG_ 257 ESC_SeitenwindAssistent_Eingriff "Mit diesem Statusbit wird eine aktive Regelung durch den Seitenwindassistenten signalisiert.";
CM_ SG_ 257 ESC_Unterdruckmangel_erkannt "ESC hat einen Unterdruckmangel im Bremskraftverstärker festgestellt";
CM_ SG_ 257 ESP_Anschleppstart_Freigabe "Bilden einer Schleppstartfreigabe aus Fahrdynamiksicht. Schleppstartabbruch bei kritischer Fahrzeugstabilität";
CM_ SG_ 257 ESP_Gierrate "Winkelgeschwindigkeit um die z-Achse, ESP_VZ_Gierrate & ESP_QBit_Gierrate beachten !!!

MLB: gemessener Wert
tatsächliche Auflösung Bosch ESP: 0,27 Grad/s

Ab AU64x Auflösung wie die tatsächliche Skalierung 0,01. Im AU64x und AU57x wird bei ESP-Absch";
CM_ SG_ 257 ESP_Laengsbeschl "Beschleunigungswert in x-Achse

MLB: Im AU64x und AU57x erfolgt die Bereitstellung der Sensorwerte durch SARA-SG! Im AU64x und AU57x wird bei ESP-Abschaltung durch modellgestützte Überwachung das Signal weiterhin ausgegeben.

MQB: reines ABS schickt 0";
CM_ SG_ 257 ESP_Notbremsanzeige "ABS/ASR oder ESP hat Notbremssituation erkannt.
Weiterführende Informationen im Lastenheft spezifiziert und in der entsprechenden Fachabteilung zu erfragen.

";
CM_ SG_ 257 ESP_PLA_Abbruch "Wenn der Bremseingriff abgebrochen wurde, wird in diesem Signal der Grund des Abbruchs dargestellt.
Dies ist nur gültig, wenn der Status ESP_Status_ESP_PLA = '0xA' ist.";
CM_ SG_ 257 ESP_QBit_Gierrate "QBit der Gierrate. Gesetzt bei Ersatzwert, Init oder Fehler. 
";
CM_ SG_ 257 ESP_QBit_Laengsbeschl "QBit der Längsbeschleunigung. Gesetzt bei Ersatzwert, Init oder Fehler. 
";
CM_ SG_ 257 ESP_QBit_Querb "QBit der Querbeschleunigung. Gesetzt bei Ersatzwert, Init oder Fehler. ";
CM_ SG_ 257 ESP_Querbeschleunigung "Beschleunigungswert in y-Achse

MLB: Gemessener Wert
0xFF = Fehler (wie bereits im Wertebereich spezifizert)
Bei ESP-Abschaltung durch modellgestützte Überwachung wird das Signal weiterhin ausgegeben.
Im AU64x und AU57x erfolgt die Bereitstellung der";
CM_ SG_ 257 ESP_SpannungsAnf "Die Rekuperation kann mit der Anforderung einer höheren Spannung eingeschränkt werden.";
CM_ SG_ 257 ESP_Status_ESP_PLA "Zustand der Statusmaschine der Bremse für die korrespondierende Statusmaschine in dem PLA-SG";
CM_ SG_ 257 ESP_VZ_Gierrate "Vorzeichen der Gierrate";

CM_ SG_ 262 ECD_Bremslicht "Bremslichtansteuerung durch ECD-Funktion";
CM_ SG_ 262 ECD_Fehler "ESP kann die Verzögerungsregelung/Bremsenregelung aufgrund eines internen Fehlers nicht ausführen, mit Fehlereintrag im ESP.
";
CM_ SG_ 262 ECD_nicht_verfuegbar "ESP kann die Verzögerungsregelung/Bremsenregelung temporär nicht ausführen (z.B. Netzwerkmanagement-Betriebe - KL15 Aus; v<18km/h; ESP in Diagnose, ...), ohne Fehlereintrag im ESP.

";
CM_ SG_ 262 ESP_Anforderung_EPB "ESP fordert von der EPB Öffnen bzw. Schliessen an. Notwendig wegen Autohold-Funktion.";
CM_ SG_ 262 ESP_Autohold_aktiv "Rückmeldung an EPB, dass Autohold aktiv ist.";
CM_ SG_ 262 ESP_Autohold_Standby "Rückmeldung an EPB, dass der Fahrer die Funktion Autohold mindestens einmal angefordert hat. Im Fall eines ESP-Ausfalles oder einer Übernahmeaufforderung erfolgt die EPB-Zuschaltung nur nach Setzen dieses Bits. Bit wird gesetzt nach Betätigung des Autohol";
CM_ SG_ 262 ESP_BKV_Unterdruck "Der maximale Wert wird auf 1012 mbar begrenzt.
Dieses Signal wird im AU64x nicht unterstützt.

Hinweis: Auch bei nicht verbautem BKV-Unterdrucksensor könnte während der Initialisierung der Initialisierungswert gesendet werden.";
CM_ SG_ 262 ESP_Bremsdruck "Rohwert des Bremsdrucks
Für Fahrzeuge mit elektrischem Bremskraftverstärker gilt: Aus dem Signal ESP_Bremsdruck lässt sich kein Fahrerbremswunsch ableiten. Das Signal bildet lediglich den hydraulischen Anteil der Fahrzeugverzögerung ab. Der Rohwert des S";
CM_ SG_ 262 ESP_Bremsruck_AWV2 "Das Signal dient als Rückmeldung zum ACC, dass ein angeforderter AWV2-Bremsruck durchgeführt wird. Die positive Rückmeldung löst u.a. eine entsprechende Fahrerinformation im Kombiinstrument aus";
CM_ SG_ 262 ESP_Eingr_HL "wird von QSP und Neigungsanzeige verwendet

Flag wird vom ESP gesetzt, sobald aufgrund eines ESP-Eingriffs am Rad aktiv Druck aufgebaut wird.
Frühestens mit öffnen des Ventils und spätestens bei einem Bremsmoment von 100Nm. Flag bleibt solange gesetzt ";
CM_ SG_ 262 ESP_Eingr_HR "wird von QSP und Neigungsanzeige verwendet

Flag wird vom ESP gesetzt, sobald aufgrund eines ESP-Eingriffs am Rad aktiv Druck aufgebaut wird.
Frühestens mit öffnen des Ventils und spätestens bei einem Bremsmoment von 100Nm. Flag bleibt solange gesetzt ";
CM_ SG_ 262 ESP_Eingr_VL "wird von QSP und Neigungsanzeige verwendet

Flag wird vom ESP gesetzt, sobald aufgrund eines ESP-Eingriffs am Rad aktiv Druck aufgebaut wird.
Frühestens mit öffnen des Ventils und spätestens bei einem Bremsmoment von 100Nm. Flag bleibt solange gesetzt ";
CM_ SG_ 262 ESP_Eingr_VR "wird von QSP und Neigungsanzeige verwendet

Flag wird vom ESP gesetzt, sobald aufgrund eines ESP-Eingriffs am Rad aktiv Druck aufgebaut wird.
Frühestens mit öffnen des Ventils und spätestens bei einem Bremsmoment von 100Nm. Flag bleibt solange gesetzt ";
CM_ SG_ 262 ESP_Fahrer_bremst "Bit wird gesetzt beim Überschreiten der Bremsdruckschwelle

Weiterführende Informationen im Lastenheft spezifiziert und in der entsprechenden Fachabteilung zu erfragen.
";
CM_ SG_ 262 ESP_FStatus_Anfahrhilfe "Bei gesetztem Bit steht die Funktion Berganfahrassistent (Hillhold) nicht zur Verfügung";
CM_ SG_ 262 ESP_HBA_aktiv "Verwendung/Bedienung ab D4
Signal gibt an, ob der hydraulische Bremsassistent im Regler aktiviert wurde

Im MQB wird das Signal nicht unterstützt!

";
CM_ SG_ 262 ESP_HDC_aktiv "MQB und AU57x Allroad: Mit diesem Statusbit wird eine gerade aktive Regelung des Bergabfahrassistenten (Hill Descent Control) signalisiert.";
CM_ SG_ 262 ESP_HDC_Standby "Verwendung/Bedienung im MQB und AU57x Allroad:
Flag wird vom ESP gesetzt, wenn über den HDC-Taster die HDC-Funktion eingeschalten wurde";
CM_ SG_ 262 ESP_Konsistenz_AWV2 "Rückmeldung zum Sender einer AWV-Anforderung (ACC-Steuergerät) bezüglich Prüfung der Checksumme, des Botschaftszählers, des langen Timeout und DLC.
";
CM_ SG_ 262 ESP_Konsistenz_TSK "Rückmeldung zum Sender einer Verzögerungsanforderung (Triebstrangskoordinator) bezüglich Prüfung der Checksumme, des Botschaftszählers, des langen Timeout und DLC. Wird auch gesetzt bei Verzögerungsanforderung größer einer applizierbaren Schwelle.
";
CM_ SG_ 262 ESP_Lenkeingriff_ADS "Im Falle eines fahrzeugstabilisierenden Lenkeingriffs des ADS-Systems soll ACC/GRA deaktiviert werden.

Im MQB wird dieses Signal nicht unterstützt!";
CM_ SG_ 262 ESP_Prefill_ausgeloest "MLB: Verwendung/Bedienung ab D4
zeigt, ob die Funktion Prefill (aufgrund Fahrpedalgradient) ausgelöst wird; zeigt keinen Funktionszustand bezüglich Fehlerstilllegung

MQB: Wird gesetzt bei jeder Art von aktivem Prefill";
CM_ SG_ 262 ESP_QBit_Bremsdruck "QBit des Bremsdrucks. Gesetzt bei Ersatzwert, Init oder Fehler.";
CM_ SG_ 262 ESP_QBit_Fahrer_bremst "Gültigkeit der Bremsdruckschwelleninformation des Signals ESP_Fahrer_bremst vom ESP SG
0x1 = Druckschwelleninformation kann noch nicht oder aufgrund eines Fehlers nicht ausgegeben werden
";
CM_ SG_ 262 ESP_Rueckwaertsfahrt_erkannt "nur bei AU57x und AU416 sowie Audi B8PA
Info, ob Rückwärtsfahrt über internen Algorithmus sicher erkannt

Im MQB wird das Signal nicht unterstützt!";
CM_ SG_ 262 ESP_Schwelle_Unterdruck "Verwendung im MQB für HBV-Projekte oder wenn für St/St ein Unterdrucksensor verbaut ist";
CM_ SG_ 262 ESP_StartStopp_Info "Stopp-Freigabe und Start-Anforderung an den Start-Stopp-Koordinator";
CM_ SG_ 262 ESP_Status_Anfahrhilfe "Funktionsstatus des Berganfahrassistenten
MQB: Auswertung im Getriebe zwecks Standabkopplung";
CM_ SG_ 262 ESP_Status_Bremsdruck "MLB: Bei gesetztem Bit liegt p > ca. 2 bar an, hervorgerufen durch Fahrer, ASR, FZR, ECD, Bremsregler ... bei Abfall des Bits ist p < X bar, bei aktivem ECD-Eingriff Ende des Eingriffs 

Weiterführende Informationen im Lastenheft spezifiziert und in der";
CM_ SG_ 262 ESP_Status_Bremsentemp "ECD-Bremsscheibentemperaturmodell. Rückmeldung für Sender einer ECD Verzögerungsanforderung, ohne Fehlereintrag im ESP";
CM_ SG_ 262 ESP_Verz_EPB_aktiv "Bei gesetztem Bit wird die Verzögerungsanforderung von EPB umgesetzt.";
CM_ SG_ 262 ESP_Verz_TSK_aktiv "Rückmeldeinformation an den Triebsstrangkoordinator/ACC, dass die ECD-Verzögerungsanforderung aktuell umgesetzt wird";
CM_ SG_ 262 ESP_Verzoeg_EPB_verf "Bei gesetztem Bit ist der Verzögerungsregeler für EPB verfügbar.";

CM_ SG_ 278 ESP_10_BZ "Botschaftszähler

Wird im Projekt D4 und D4Hybrid nicht verwendet!  Wird im D4 PA verwendet
Botschaft asynchron geroutet. Zählerwert kann springen.";
CM_ SG_ 278 ESP_10_CRC "Für MLB:
'Berechnung siehe Lastenheft 'Kommunikationsabsicherung für FlexRay und CAN''

Ab MQB und MLBevo:
'Berechnung siehe Lastenheft 'End-to-End Kommunikationsabsicherung''

Endwerte siehe Begleitdokument 'S-PDU Kennungsfolgen'

Wird im Projekt";
CM_ SG_ 278 ESP_HL_Fahrtrichtung "Drehrichtung Rad HL

Weiterführende Informationen im Lastenheft spezifiziert und in der entsprechenden Fachabteilung zu erfragen.

Wird im Projekt D4 und D4Hybrid nicht verwendet!  Wird im D4 PA verwendet";
CM_ SG_ 278 ESP_HR_Fahrtrichtung "Drehrichtung Rad HR

Weiterführende Informationen im Lastenheft spezifiziert und in der entsprechenden Fachabteilung zu erfragen.

Wird im Projekt D4 und D4Hybrid nicht verwendet!  Wird im D4 PA verwendet";
CM_ SG_ 278 ESP_QBit_Wegimpuls_HL "Qualifizierungsbit Wegimpulszähler HL

Wird im Projekt D4 und D4Hybrid nicht verwendet!  Wird im D4 PA verwendet";
CM_ SG_ 278 ESP_QBit_Wegimpuls_HR "Qualifizierungsbit Wegimpulszähler HR

Wird im Projekt D4 und D4Hybrid nicht verwendet!  Wird im D4 PA verwendet";
CM_ SG_ 278 ESP_QBit_Wegimpuls_VL "Qualifizierungsbit Wegimpulszähler VL

Wird im Projekt D4 und D4Hybrid nicht verwendet!  Wird im D4 PA verwendet";
CM_ SG_ 278 ESP_QBit_Wegimpuls_VR "Qualifizierungsbit Wegimpulszähler VR

Wird im Projekt D4 und D4Hybrid nicht verwendet!  Wird im D4 PA verwendet";
CM_ SG_ 278 ESP_VL_Fahrtrichtung "Drehrichtung Rad VL

Weiterführende Informationen im Lastenheft spezifiziert und in der entsprechenden Fachabteilung zu erfragen.

Wird im Projekt D4 und D4Hybrid nicht verwendet!  Wird im D4 PA verwendet";
CM_ SG_ 278 ESP_VR_Fahrtrichtung "Drehrichtung Rad VR

Weiterführende Informationen im Lastenheft spezifiziert und in der entsprechenden Fachabteilung zu erfragen.

Wird im Projekt D4 und D4Hybrid nicht verwendet!  Wird im D4 PA verwendet";
CM_ SG_ 278 ESP_Wegimpuls_HL "Wegimpulszähler HL.
Anzahl der Wegimpulse Hinterrad links (steigende und fallende Flanke)
Zähler läuft grundsätzlich vorwärts, auch bei Rückwärtsfahrt.
Nach SG-Reset ist immer, ohne Ausnahme, 1mal der Init Wert 1021 zu senden.

Wird im Projekt D4 und";
CM_ SG_ 278 ESP_Wegimpuls_HR "Wegimpulszähler HR.
Anzahl der Wegimpulse Hinterrad rechts (steigende und fallende Flanke)
Zähler läuft grundsätzlich vorwärts, auch bei Rückwärtsfahrt.
Nach SG-Reset ist immer, ohne Ausnahme, 1mal der Init Wert 1021 zu senden.

Wird im Projekt D4 un";
CM_ SG_ 278 ESP_Wegimpuls_VL "Wegimpulszähler VL.
Anzahl der Wegimpulse Vorderrad links (steigende und fallende Flanke)
Zähler läuft grundsätzlich vorwärts, auch bei Rückwärtsfahrt.
Nach SG-Reset ist immer, ohne Ausnahme, 1mal der Init Wert 1021 zu senden.

Wird im Projekt D4 und";
CM_ SG_ 278 ESP_Wegimpuls_VR "Wegimpulszähler VR.
Anzahl der Wegimpulse Vorderrad rechts (steigende und fallende Flanke)
Zähler läuft grundsätzlich vorwärts, auch bei Rückwärtsfahrt.
Nach SG-Reset ist immer, ohne Ausnahme, 1mal der Init Wert 1021 zu senden.

Wird im Projekt D4 un";

CM_ SG_ 1629 BR_QBit_Reifenumfang "Gesetzt bei Ersatzwert, Init oder Fehler.";
CM_ SG_ 1629 BR_Reifenumfang "Mittlerer Radumfang gerechnet in Millimeter.
Von der Bremse plausibilisierter Wert (Kopie von KBI_Reifenumfang wenn dieser plausibel) oder Ersatzwert aus Bremse wenn KBI_Reifenumfang unplausibel. Bitte das QBit beachten!

Im MEB wird das Signal KBI_Rei";
CM_ SG_ 1629 BR_Systemart "Identifikation des verbauten Bremssystems

Dient dem Kombi zur Plausibilisierung";
CM_ SG_ 1629 ESP_20_CRC "Für MLB:
'Berechnung siehe Lastenheft 'Kommunikationsabsicherung für FlexRay und CAN''

Ab MQB und MLBevo:
'Berechnung siehe Lastenheft 'End-to-End Kommunikationsabsicherung''

Endwerte siehe Begleitdokument 'S-PDU Kennungsfolgen'";
CM_ SG_ 1629 ESP_Charisma_FahrPr "MLBevo: Aktuelles Fahrprogramm des Charisma-Teilnehmers (siehe Systemlastenheft Drive Select)
MQB: Istwert der Kennlinie (siehe Systemlastenheft MQB FPA)";
CM_ SG_ 1629 ESP_Charisma_Status "Systemstatus des Charismateilnehmers

Wert 0x3 ist nur für Fahrzeuge ab MQB relevant";
CM_ SG_ 1629 ESP_Dachrelingsensor "Erkennung auf Verbau des Dachrelingsensors und Dachquerträger.";
CM_ SG_ 1629 ESP_SpannungsAnf_02 "Forderung des ESP-SG's zur Spannungsanhebung.";
CM_ SG_ 1629 ESP_Stoppverbot_Anz_01 "Dieses Signal gibt die detaillierte Begründung für ein Stoppverbot vom Bremsensteuergerät an.";
CM_ SG_ 1629 ESP_Stoppverbot_Anz_02 "Dieses Signal gibt die detaillierte Begründung für ein Stoppverbot vom Bremsensteuergerät an.";
CM_ SG_ 1629 ESP_Stoppverbot_Anz_03 "Dieses Signal gibt die detaillierte Begründung für ein Stoppverbot vom Bremsensteuergerät an.";
CM_ SG_ 1629 ESP_Stoppverbot_Anz_04 "Dieses Signal gibt die detaillierte Begründung für ein Stoppverbot vom Bremsensteuergerät an.";
CM_ SG_ 1629 ESP_Stoppverbot_Anz_05 "Dieses Signal gibt die detaillierte Begründung für ein Stoppverbot vom Bremsensteuergerät an.";
CM_ SG_ 1629 ESP_Stoppverbot_Anz_06 "Dieses Signal gibt die detaillierte Begründung für ein Stoppverbot vom Bremsensteuergerät an.";
CM_ SG_ 1629 ESP_Stoppverbot_Anz_07 "Dieses Signal gibt die detaillierte Begründung für ein Stoppverbot vom Bremsensteuergerät an.";
CM_ SG_ 1629 ESP_Stoppverbot_Anz_08 "Dieses Signal gibt die detaillierte Begründung für ein Stoppverbot vom Bremsensteuergerät an.";
CM_ SG_ 1629 ESP_Stoppverbot_Anz_Std "Dieses Signal gibt die detaillierte Begründung für ein Stoppverbot vom Bremsensteuergerät an.";
CM_ SG_ 1629 ESP_Wiederstart_Anz_01 "Dieses Signal gibt die detaillierte Begründung für einen Wiederstart vom Bremsensteuergerät an. ";
CM_ SG_ 1629 ESP_Wiederstart_Anz_02 "Dieses Signal gibt die detaillierte Begründung für einen Wiederstart vom Bremsensteuergerät an. ";
CM_ SG_ 1629 ESP_Wiederstart_Anz_03 "Dieses Signal gibt die detaillierte Begründung für einen Wiederstart vom Bremsensteuergerät an. ";
CM_ SG_ 1629 ESP_Wiederstart_Anz_04 "Dieses Signal gibt die detaillierte Begründung für einen Wiederstart vom Bremsensteuergerät an.";
CM_ SG_ 1629 ESP_Zaehnezahl "Konstanter Wert der Zähnezahl des verwendeten Impulsrades wird ausgegeben, jeder Empfänger der Wegimpulse muss die Zähnezahl einlesen, um eine volle Umdrehung des Rades zu erkennen. 

Weiterführende Informationen im Lastenheft spezifiziert und in der en";
CM_ SG_ 1629 HDC_Charisma_FahrPr "MLBevo: Aktuelles Fahrprogramm des Charisma-Teilnehmers (siehe Systemlastenheft Drive Select)
MQB: Istwert der Kennlinie (siehe Systemlastenheft MQB FPA)";
CM_ SG_ 1629 HDC_Charisma_Status "Systemstatus des Charismateilnehmers

Wert 0x3 ist nur für Fahrzeuge ab MQB relevant";

CM_ SG_ 253 ABS_Bremsung "Antiblockiersystem, Bit zeigt auch Druckabbau an (z.B. ESP hat zuviel Druck aufgebaut oder ungebremste Regelung auf Bahnübergang)
Weiterführende Informationen im Lastenheft spezifiziert und in der entsprechenden Fachabteilung zu erfragen.";
CM_ SG_ 253 ASR_Anf "MLB: Die Momentenanforderung 'ASR_MSR_Moment_schnell' und 'ASR_Moment_langsam' sind auszuführen
MQB: Die Momentenanforderung 'BR_Eingriffsmoment' ist auszuführen";
CM_ SG_ 253 ASR_Schalteingriff "Wunsch an das Getriebe während einer ASR Regelung

MLB: Es wird nur 0x0 und 0x1 genutzt

";
CM_ SG_ 253 ASR_Tastung_passiv "ASR deaktiviert oder Schwellen geändert (projektabhängig)
Weiterführende Informationen im Lastenheft spezifiziert und in der entsprechenden Fachabteilung zu erfragen.
";
CM_ SG_ 253 BR_Eingriffsmoment "Einheitenloser Wert! Faktor in MO_Faktor_Momente_02 in Motor_Code_01 beachten!
Schnelle reduzierende (ASR) oder erhöhende (MSR) Momentanforderung an den Motor.";
CM_ SG_ 253 EBV_Eingriff "Elektronische Bremskraftverteilung, aktueller Eingriff (Druckhalten, Druckabbau)

Im MLB: kein ABS / ESP-Eingriff ???";
CM_ SG_ 253 EDS_Eingriff "Elektronische Differentialsperre";
CM_ SG_ 253 ESC_Reku_Freigabe "Mit diesem Bit wird die Rekuperation im Motorsteuergerät erlaubt. Bei Ausfall ESC wird Rekuperation nicht freigegeben.

MQB/MQB2020: Wird nur von einem blendfähigen ESC unterstützt, wie es in mHEV und pHEV Fahrzeugen eingesetzt wird.";
CM_ SG_ 253 ESC_v_Signal_Qualifier_High_Low "Das Qualifizerungssignal ESC_v_Signal_Qualifier_High_Low gibt eine Information über die Güte der vom Bremsregelsystem ausgegebenen Geschwindigkeitsinformation 'mittlere Geschwindigkeit', wobei Vertrauensbereiche für das ausgegebene Geschwindigkeitssignal ";
CM_ SG_ 253 ESP_21_CRC "Für MLB:
'Berechnung siehe Lastenheft 'Kommunikationsabsicherung für FlexRay und CAN''

Ab MQB und MLBevo:
'Berechnung siehe Lastenheft 'End-to-End Kommunikationsabsicherung''

Endwerte siehe Begleitdokument 'S-PDU Kennungsfolgen'";
CM_ SG_ 253 ESP_Anhaltevorgang_ACC_aktiv "Zeigt an, ob ACC-Anhaltevorgang aktiv";
CM_ SG_ 253 ESP_ASP "MLB: Anhaenger-Stabilisierungs-Programm
MQB: Gespannstabilisierung";
CM_ SG_ 253 ESP_AWV3_Brems_aktiv "Teil-, Ziel- oder Notbremsung wird im ESP für AWV3 umgesetzt (das MSG nutzt diese Info für den Abwurf der GRA-Regelung).";
CM_ SG_ 253 ESP_Diagnose "MLB: Nach Diagnoseende wird ein SW-Reset ausgelöst welcher einen Kommunikatiosausfall für max. 150ms verursacht. Dies ist bei SG mit verschärfter Timeoutüberwachung (nicht nach Konzern-LH) zu beachten.

MQB: Weiterführende Informationen im Lastenheft sp";
CM_ SG_ 253 ESP_Eingriff "Eingriff des Fahrdynamikreglers";
CM_ SG_ 253 ESP_Haltebestaetigung "Rückmeldung vom ESP-SG, dass das Fahrzeug aufgrund einer externen Bremsanforderung (z. B. ACC, PLA, ANB, o. ä.) abgebremst wurde und im Stillstand gehalten wird.";
CM_ SG_ 253 ESP_MKB_Abbruch_Geschw "Im Falle einer Multikollisionsbremsung teilt das ESP den Abbruch der MKB aufgrund der unteren Geschwindigkeitsschwelle mit.";
CM_ SG_ 253 ESP_PLA_Bremseingriff "Signalisierung des aktiven Bremseingriffes des ESP aufgrund einer Bremsanforderung vom PLA.";
CM_ SG_ 253 ESP_QBit_v_Signal "Geschwindigkeit wird vom ABS/ASR oder ESP aus Ersatzwerten errechnet, wenn Bit gesetzt ist. Güte des Signals ist verändert.";
CM_ SG_ 253 ESP_Systemstatus "Fehler steht für Stillegung ESP mit Fehlereintrag.

MLB: Flag wird bei Unterspannung im Stand bis einmalig 6km/h (AU48x) oder 10 km/h (AU641, AU57x) überschritten nicht gesetzt (Ausblendung Startvorgang)
Im AU64x, AU57x gilt ESP D4 Funktionsanforderung";
CM_ SG_ 253 ESP_Tastung_passiv "ESP deaktiviert oder Schwellen geändert (projektabhängig)
Weiterführende Informationen im Lastenheft spezifiziert und in der entsprechenden Fachabteilung zu erfragen.";
CM_ SG_ 253 ESP_v_Signal "Geschwindigkeitssignal vom ABS/ASR oder ESP. Mittelwert der angetriebenen Räder.
Bei MSR oder ABS Eingriffen wird die ABS-Referenzgeschwindigkeit für >= 200ms eingespiegelt (Zeit wird mit Aktiv-Flanke der Funktionsbits getriggert)

MQB: Bei Frontantrie";
CM_ SG_ 253 ESP_Vorsteuerung "zur Unterscheidung zwischen ESP-Vorsteuermaßnahmen und ESP-Regeleingriffen";
CM_ SG_ 253 MSR_Anf "MLB: Die Momentenanforderung 'ASR_MSR_Moment_schnell' ist auszuführen.
MQB: Die Momentenanforderung 'BR_Eingriffsmoment' ist auszuführen";
CM_ SG_ 253 OBD_Schlechtweg "Für Ausblendung der Zündaussetzererkennung im Motorsteuergerät (Otto). Bit wird gesetzt, wenn Rad-Drehbeschleunigung im ESP > Grenzwert ist. Vorteil gegenüber Radgeschwindigkeiten, dass ESP alle 2 ms dynamisch die Rad-Drehbeschleunigung errechnet und dem ";

CM_ SG_ 795 ABS_Lampe "Sicherheitswarnlampe

Weiterführende Informationen im Lastenheft spezifiziert und in der entsprechenden Fachabteilung zu erfragen.";
CM_ SG_ 795 BK_Lampe_02 "Typ1_ein_statisch signalisiert EBV-Ausfall
MQB: wird auch bei HBV-Ausfall verwendet.

Typ1_ein_statisch: wird bei AUDI für Aktivierung der roten BKL ohne Text und Akustik verwendet (z.B. Lampenaufprüfung).
Typ2_ein_statisch: signalisiert elektrischen ";
CM_ SG_ 795 ESP_24_CRC "Für MLB:
'Berechnung siehe Lastenheft 'Kommunikationsabsicherung für FlexRay und CAN''

Ab MQB und MLBevo:
'Berechnung siehe Lastenheft 'End-to-End Kommunikationsabsicherung''

Endwerte siehe Begleitdokument 'S-PDU Kennungsfolgen'";
CM_ SG_ 795 ESP_BKV_Warnung "ESP sendet im Hinweis- /Störungsfall an das Kombi Informationen zum Anzeigen (Text + Akustik)

Im MQB wird dieses Signal nicht unterstützt!
";
CM_ SG_ 795 ESP_Fehlerstatus_Wegimp "Weiterführende Informationen im Lastenheft spezifiziert und in der entsprechenden Fachabteilung zu erfragen.

MLB: Fehler wird gesetzt, wenn beide ESP-Drehzahlfühler an der Vorderachse defekt sind.

MQB: Fehler wird gesetzt, wenn beide Raddrehzahlfühl";
CM_ SG_ 795 ESP_HDC_FktLampe "Funktionslampe Bergabfahrassistent.
(Sender blinkt mit dem Bit 3,3Hz)";
CM_ SG_ 795 ESP_HDC_Regelgeschw "Verwendung/Bedienung nur im AU57x Allroad:
HDC-Geschwindigkeit
Dient der Anzeige der HDC-Geschwindigkeit und eines Bergabfahrsymbols im Kombi.
HDC-Standby wird gesetzt sobald der Fahrer den HDC-Taster aktiviert hat.
Bei HDC-Off oder während der Initia";
CM_ SG_ 795 ESP_Lampe "Zustand der Fahrdynamikregelungslampe (MLB: ASR und/oder ESP, MQB: nur ESP)

Weiterführende Informationen im Lastenheft spezifiziert und in der entsprechenden Fachabteilung zu erfragen.";
CM_ SG_ 795 ESP_m_Raddrehz "Radumdrehungen pro Sekunde sind Eingangsgröße für die Geschwindigkeitsberechnung im Kombi. Aus dieser Raddrehzahl und dem Radumfang wird die Fahrzeuggeschwindigkeit errechnet.

MLB: Exklusiver Empfänger ist das Kombiinstrument!
MQB: Bei Frontantrieb un";
CM_ SG_ 795 ESP_Meldungen "ESP sendet im Hinweis- /Störungsfall an das Kombi Informationen zum Anzeigen

Weiterführende Informationen im Lastenheft spezifiziert und in der entsprechenden Fachabteilung zu erfragen.
Ergänzender Hinweis:
1 = Autohold_Hinweis_1 (Anfahrassistent: nu";
CM_ SG_ 795 ESP_Off_Lampe "Bit zur Ansteuerung der separaten ESP-off-Lampe im Kombi (Gesetzesforderung USA)

MLB:
Verwendung/Bedienung ab D4";
CM_ SG_ 795 ESP_QBit_Wegimp_VA "Gesetzt bei Ersatzwert, Init oder Fehler.";
CM_ SG_ 795 ESP_Textanzeigen_03 "Textanzeigen der Fahrdynamikregelung im Kombiinstrument

Weiterführende Informationen im Lastenheft spezifiziert und in der entsprechenden Fachabteilung zu erfragen.

Der Signalwert 24 wird nur im BY736 verwendet.";
CM_ SG_ 795 ESP_Wegimp_Ueberlauf "Der Wegimpulszähler ist pro Zündungslauf mindestens einmal übergelaufen

Weiterführende Informationen im Lastenheft spezifiziert und in der entsprechenden Fachabteilung zu erfragen.";
CM_ SG_ 795 ESP_Wegimp_VA "Weiterführende Informationen im Lastenheft spezifiziert und in der entsprechenden Fachabteilung zu erfragen.

MLB: Die Wegimpulse Vorderachse sind die gemittelten Werte (reine mathematische Operation: Addition und Division durch zwei, keine Filterung) d";
CM_ SG_ 795 TC_Lampe "M-ABS Lampe (separate Lampe für M-ABS-Systeme Markt Brasilien)

Weiterführende Informationen im Lastenheft spezifiziert und in der entsprechenden Fachabteilung zu erfragen.";

CM_ SG_ 2589283617 DBK_Fahrerwarnung "Warnt den Fahrer bei erkannter Dampfblase in der Bremsflüssigkeit und fordert ihn zum Anhalten sowie Werkstattbesuch auf (2 Bit):
0: kein Anfordern (Initwert)
1: Warnereignis 1 - fordert Warnlampe, Warnmeldung (Aufforderung Anhalten) und Warnton sowie F";
CM_ SG_ 2589283617 EDS_Charisma_FahrPr "Aktuelles Fahrprogramm des Charisma-Teilnehmers Elektronische Differentialsperre EDS";
CM_ SG_ 2589283617 EDS_Charisma_Status "Systemstatus des Charismateilnehmers Elektronische Differentialsperre EDS";
CM_ SG_ 2589283617 ESC_Anf_KL "Nachricht an Motor- bzw. Antriebssteuergerät zur Festlegung der Motorluefterdrehzahl
Angabe in Prozent der Maximaldrehzahl";
CM_ SG_ 2589283617 ESC_Anf_KV "Nachricht an Motor bzw. Antriebssteuergerät zum Öffnen der Kühlerjalousie.";
CM_ SG_ 2589283617 ESC_FBA_Meldungen "Hinweis an den Fahrer über das Kombi, bei dauerhafter Bergabfahrt einen Gang einzulegen um die Motorbremse zu nutzen.
Unterscheidung zwischen: 
Handschalterfahrzeugen (FBA_Warnung_aktiv_MT)
Automatikfahrzeugen (FBA_Warnung_aktiv_AT)";
CM_ SG_ 2589283617 ESC_Lernfreigabe_Abrollumfang "Meldet einen Fahrdynamikzustand, der es zulässt, dass der Abrollumfang der Räder genauer errechnet werden darf.
Die Verwendung des Signals ist ausschließlich für die MQB-Plattform zugelassen.";
CM_ SG_ 2589283617 ESC_MBK_Meldungen "Das Signal steuert die Schaltempfehlung im Kombi, die bei Bergabfahrt den Fahrer darauf hinweist in eine geeignete Fahrstufe zu schalten um eine Rekuperation zu ermöglichen.";
CM_ SG_ 2589283617 ESC_Texte_eBKV_Betaetigung "Anweisungen an den Fahrer für die Betätigung der Bremse über den eBKV unter Verwendung der Schaltwippen am Lenkrad.";
CM_ SG_ 2589283617 ESP_30_BZ "4bit Botschaftszähler, wird mit jeder Sendebotschaft inkrementiert";
CM_ SG_ 2589283617 ESP_30_CRC "Für MLB:
Berechnung siehe Lastenheft 'Kommunikationsabsicherung für FlexRay und CAN'
Ab MQB und MLBevo:
Berechnung siehe Lastenheft 'End-to-End Kommunikationsabsicherung'

Endwerte siehe Begleitdokument 'S-PDU Kennungsfolgen'";
CM_ SG_ 2589283617 ESP_Off_Anf_KBI "Anzeige ESP Off Bestätigungsaufforderung";
CM_ SG_ 2589283617 ESP_Status_Bremsentemp_Anz "Anzeigesignal für Bremsentemperatur";
CM_ SG_ 2589283617 FBC_Fahrerwarnung "Warnt den Fahrer bei aktiver FBC-Funktion vor heißer Bremsanlage aufgrund Fading und fordert ihn zum 'langsam weiterfahren' auf.";
CM_ SG_ 2589283617 HHC_Charisma_FahrPr "Aktuelles Fahrprogramm des Charisma-Teilnehmers Berganfahrassistent HHC";
CM_ SG_ 2589283617 HHC_Charisma_Status "Systemstatus des Charismateilnehmers Berganfahrassistent HHC";
CM_ SG_ 2589283617 RLE_Anzeigen "Anzeigen für die Radlöseerkennung";

CM_ SG_ 2589283684 FoD_Transmission_Info "Mit dem Signal zeigt der FoD-Master allen FoD-Slaves den Beginn und das Ende eines Freischaltuebertragungszykluses (FS-ID-Zyklus) an.";
CM_ SG_ 2589283684 GRA_FoD_Status "Verortung des FOD-Slaves für die Funktion GRA erfolgt im Gateway. Signal übermittelt den FOD-Status an das MSG.";

CM_ SG_ 2549875571 FoD_ZR_Req_Data "FoD - Function On Demand
ISO-TP Datenkanal - FID2NA
Request Funktion 0x03 FoD-Master

FoD-Master an Zentralrechner";

CM_ SG_ 2550006643 FoD_ZR_Resp_Data "FoD - Function On Demand
ISO-TP Datenkanal - FID2NA
Response Knoten 0x73 Zentralrechner

Zentralrechner an FoD Master";

CM_ SG_ 986 ABS_Bremsung "Antiblockiersystem, Bit zeigt auch Druckabbau an (z.B. ESP hat zuviel Druck aufgebaut oder ungebremste Regelung auf Bahnübergang)
Weiterführende Informationen im Lastenheft spezifiziert und in der entsprechenden Fachabteilung zu erfragen.";
CM_ SG_ 986 ECD_Bremslicht "Bremslichtansteuerung durch ECD-Funktion";
CM_ SG_ 986 EPB_Pedalweg_Kuppl "Signal entspricht Tastverhältnis des PWM. Gesamtweg Kupplungspedal 10% bis 90%, damit zu erwartende Werte 25 bis 225. 25 bei Kupplungspedal nicht getreten, 225 bei Kupplungspedal voll durchgetreten.
2% Toleranz wird im Wertebereich ermöglicht (8%-92%).
";
CM_ SG_ 986 EPB_Status "Gibt den Zustand der EPB-Aktuatoren an.

Nur VW526/PAG E2: Wert 0x3 bedeutet 'unbekannt'

";
CM_ SG_ 986 ESP_Eingriff "Eingriff des Fahrdynamikreglers";
CM_ SG_ 986 ESP_HDC_Standby "Verwendung/Bedienung im MQB und AU57x Allroad:
Flag wird vom ESP gesetzt, wenn über den HDC-Taster die HDC-Funktion eingeschalten wurde";
CM_ SG_ 986 ESP_MKB_Abbruch_Geschw "Im Falle einer Multikollisionsbremsung teilt das ESP den Abbruch der MKB aufgrund der unteren Geschwindigkeitsschwelle mit.";
CM_ SG_ 986 ESP_QBit_v_Signal "Geschwindigkeit wird vom ABS/ASR oder ESP aus Ersatzwerten errechnet, wenn Bit gesetzt ist. Güte des Signals ist verändert.";
CM_ SG_ 986 ESP_v_Signal "Geschwindigkeitssignal vom ABS/ASR oder ESP. Mittelwert der angetriebenen Räder.
Bei MSR oder ABS Eingriffen wird die ABS-Referenzgeschwindigkeit für >= 200ms eingespiegelt (Zeit wird mit Aktiv-Flanke der Funktionsbits getriggert)

MQB: Bei Frontantrie";
CM_ SG_ 986 Kamera_FSH_aktiv "Bei aktivierter (lokaler) Frontscheibenheizung wird die Scheibentemperaturmessung des Klimafeuchtesensors beeinflusst. Über das Signal wird dem Klima-SG mitgeteilt, dass die lokale Scheibenheizung aktiviert ist, um entsprechende Korrekturwerte bei der Sch";
CM_ SG_ 986 LWI_Lenkradwinkel "Wertebereich = +/- 800 Grad
Auflösung = 0,1 Grad
ACHTUNG: spezifizierte Interne Auflösung des Sensors beträgt aber nur Schrittweite 0,5 Grad!

Hinweis:
MLB: Zusätzlich gestellte Winkel bei Dynamiklenkung beachten !
MQB: Nicht konstante Lenkübersetzu";
CM_ SG_ 986 LWI_QBit_Lenkradwinkel "Das QBit wird auch bei nicht abgeglichenem Lenkradwinkelsensor gesetzt";
CM_ SG_ 986 LWI_VZ_Lenkradwinkel "Vorzeichen Lenkradwinkel gemäss DIN70000; 
Nullstellung = +0";
CM_ SG_ 986 PH_Anf_Audioabsenkung "Es gibt zwei unterschiedliche Nachlauftimer für dieses Bit:
1. normale Funktion
2. Demotonausgabe";
CM_ SG_ 986 PH_Systemzustand "Aktivierungsursache wird für die Dauer der Aktivierung gemeldet.
Im Fehlerfall bei atkviem System wechselt das Signal auf '7'
(siehe auch 'Abschaltursache')";
CM_ SG_ 986 PH_Taster "Taster Status (für RVC/TopView)";
CM_ SG_ 986 PLA_Anf_Aufschaltung_RVC "Anforderung der Aufschaltung RVC durch PLA";

CM_ SG_ 988 ACC_18_alt "Veraltet-Bit";
CM_ SG_ 988 ACC_Status_ACC "'ACC OFF' bedeutet ACC-Hauptschalter ist 'Gerastet Aus

'ACC Reversibler Fehler' bedeutet, daß das ACC aktuell einen 
reversiblen Fehler im ACC-SG selbst oder in einem zum 
ACC-System gehörenden SG erkennt.

'ACC irreversibler Fehler' bedeutet, daß ";
CM_ SG_ 988 Bel_DiETa_Mode2 "Statusanzeige FPA-Mode2 in den Direkteinstiegstasten (GTE-Taster im VW380 PHEV)";
CM_ SG_ 988 EPB_Schalterposition "Spiegelt die Schalterstellung wieder.

0x3 = Schalterfehler ";
CM_ SG_ 988 EPB_Status_02 "Erweiterung der Zustände um ein genaueres Bild des aktuellen Zustandes zu erhalten für weitergehende Funktionen ( Stillstandsmanager)
";
CM_ SG_ 988 ESP_50_alt "Veraltet-Bit";
CM_ SG_ 988 ESP_Rollenmodus_Deaktivieren "Zwang zum Abbruch des Rollenmodus mit anschließender ESP-Vollfunktion.
MQB: Zwang zum Abbruch des Rollenmodus in allen Funktionsteilnehmern (Empfänger) mit anschließender ESP-Vollfunktion (Sender).
Signal wird vom ESP dauerhaft mit gültigen Werten bedat";
CM_ SG_ 988 GE_Fahrstufe "Fahrprogramm des Getriebes

Hinweis: Zwischenstellung '0x0' darf nur für Zustandswechsel P/R, R/N, N/D ausgegeben werden, nicht für D/S oder D/Tippgasse wegen Abschaltkriterium GRA/ACC";
CM_ SG_ 988 GE_Freilauf_Status "Freilauf-Status-Signal vom Frailauf-Master an aktive Freilauf-Teilnehmer. In diesem Signal zeigt der Freilauf-Master an, welchen aktuellen Status die Freilauf-Betriebsstrategie hat.";
CM_ SG_ 988 GE_LaunchControl "Während einer LaunchControl-Anfahrt sendet das Getriebesteuergerät das Bit LaunchControl aktiv.
Die Bremse wertet dieses Bit aus, um während einer solchen Anfahrt die Regelgrenzen der Schlupfregelung zu erweitern.
Im Motor Nutzung zur Verbesserung des A";
CM_ SG_ 988 GE_Notlauf "AL/DL: Signalisiert wenn sich das Getriebe (bei DL ein Teilgetriebe) im Notlauf befindet.
VL: Wird gesetzt wenn kein Kraftschluss möglich ist.";
CM_ SG_ 988 GE_Sperr_Info_WFS "WFS-Sperrinformation";
CM_ SG_ 988 GE_Ursache_Fahrstufe_N "Zeigt an, warum Fahrstufe N angenommen wurde. So kann z.B. die Rollsicherung im Verlassenskonzept aktiv bleiben, wenn das Schalten nach N ohne Fahrerwunsch erfolgte (z.B. Fehlerreaktion).

ACHTUNG: Das Signal darf nur ausgewertet werden, wenn GE_Fahrstu";
CM_ SG_ 988 GE_Veto_Rollfaehigkeit "Der Schaltbetätigungsmaster kann mit diesem Signal die Rollfähigkeit bei Zündung aus ('N-Haltephase'/'Waschstraßenfunktion') situationsabhängig verhindern, z.B. bei einem Defekt der P-Taste.";
CM_ SG_ 988 MKE_Stufe "Das Signal bildet die Müdigkeitsstufe im Kombi ab:
0 - deaktiviert
1 - nicht_verfügbar
2 - Stufe_1
3 - Stufe_2
4 - Stufe_3
5 - Stufe_4
6 - reserviert
7 - reserviert";
CM_ SG_ 988 MKE_Texte "Systemhinweis und Sicherheitshinweis für Anzeige im Kombi";
CM_ SG_ 988 MO_Drehzahl_01 "Im Fehlerfall wird die Motordrehzahl über die Nockenwellendrehzahl als Ersatzgrösse ausgegeben

Bei Parallelhybrid: Getriebeeingangsdrehzahl (=E-Maschinen Drehzahl)

Hinweis: 
Ehemaliger Fehlerwert 0xFFFF wird senderseitig nicht unterstützt. 
Diesen";
CM_ SG_ 988 MO_QBit_Drehzahl_01 "AUDI D4: Zykluszeit: 10ms (siehe Zykluszeit schnell/Cycletime Fast)

Achtung:
Reduktion der Zykluszeit Motor_03 auf 10ms geplant.
Projektabhängig soll künftig mit 10ms gesendet werden.
Empfänger die in weiteren Konzern-Projekten eingesetzt werden müs";
CM_ SG_ 988 TSK_06_alt "Veraltet-Bit für die BotschaftTSK_06_alt";
CM_ SG_ 988 TSK_Hauptschalter_GRA_ACC "Stellung des GRA/ACC Hauptschalters. Das Signal wird auch bei Fehlerabschaltungen von GRA/ACC weiterhin bedient und ermöglicht für ACC die Steuerung der ACC-Anzeige auch in Fehlerfällen.";
CM_ SG_ 988 TSK_Limiter_ausgewaehlt "ACC/GRA-Betrieb nur bei nicht ausgewähltem Limiter möglich";
CM_ SG_ 988 TSK_Status "Betriebszustand des TSK-Reglers";

CM_ SG_ 1002 AWV_03_alt "Veraltet-Bit für die Signale:

Botschaft Gateway_77:
AWV_Zielobjekt";
CM_ SG_ 1002 AWV_Verz_Anf "Verzögerungsanforderung der Funktionen Zielbremsung und Teilbremsung an das VZM";
CM_ SG_ 1002 AWV_Verz_Freigabe "Freigabe-Bit der AWV Verzögerung an das VZM";
CM_ SG_ 1002 AWV_Zielobjekttyp "Definiert den Zielobjekttyp an VZM";
CM_ SG_ 1002 Bel_DiETa_Mode "Statusanzeige FPA-Mode in den Direkteinstiegstasten";
CM_ SG_ 1002 EBKV_03_alt "Veraltet Bit";
CM_ SG_ 1002 EBKV_Fahrer_bremst "Fahrer will bremsen (Eintreterkennung).
Wird benötigt, um ACC oder GRA abzuschalten.";
CM_ SG_ 1002 ESP_Bremsdruck "Rohwert des Bremsdrucks
Für Fahrzeuge mit elektrischem Bremskraftverstärker gilt: Aus dem Signal ESP_Bremsdruck lässt sich kein Fahrerbremswunsch ableiten. Das Signal bildet lediglich den hydraulischen Anteil der Fahrzeugverzögerung ab. Der Rohwert des S";
CM_ SG_ 1002 GE_Sumpftemperatur "Getriebesumpftemperatur wird über den Temperatursensor auf der Getriebeplatine ermittelt. Die absolute Sumpftemperatur wird vom Motor empfangen, um entsprechende Kühlleistung für das Getriebe einzustellen.";
CM_ SG_ 1002 MO_Fahrpedalrohwert_01 "AUDI D4: Zykluszeit: 10ms (siehe Zykluszeit schnell/Cycletime Fast)

Stellung des Fahrpedales (Rohwert, ohne Überlagerung durch GRA-Eingriffe etc.)

Die Funktionen zur Berechung des Fahrpedalrohwerts laufen im 10ms Raster. Der Fahrpedalwert berechnet ";
CM_ SG_ 1002 MO_Mom_Ist_Summe "Einheitenloser Wert! Faktor in MO_Faktor_Momente_02 in Motor_Code_01 beachten!

Ist-Moment als Summe aus Verbrennungsmotor und E-Motor (bei Hybrid-Konzepten) incl. allen Eingriffen und Korrekturen

In Fahrzeugen mit einer Antriebsachse bzw. mit mechan";
CM_ SG_ 1002 PaCo_DiETa_LED "Ansteuerung der Funktionsbeleuchtung im Direkteinstiegstaster ('DiETa') durch den Parking Coordinator ('PaCo').

0 LED_Inactive: Die Funktionsbeleuchtung im DiETa_Parken muss leuchten
1 LED_Active: Die Funktionsbeleuchtung im DiETa_Parken darf nicht le";
CM_ SG_ 1002 RTM_Warnstatus "Signalisiert die RTM-Warnstufe.";

CM_ SG_ 1004 ACC_Status_Anzeige "Status nur zur Defintion von Anzeige im Kombi. Hinweis: Wird für die spez. VW-Anzeige (überlappende Anzeigebereiche) verwendet. Vom AUDI-ACC im Rahmen der Modulstrategie zu bedienen.";
CM_ SG_ 1004 BCM_Offroad_Taste "Betätigung der Offroad-Taste";
CM_ SG_ 1004 BCM_Waschwasser_Sensor "Signal der Sensorelektroden für die Waschwasserreserve aktuell, entstört, bewertet (OK/Mangel)";
CM_ SG_ 1004 EM1_Status_DrzEingriff "Status ASR-Eingriff über EM-Regelung";
CM_ SG_ 1004 EM2_Status_DrzEingriff "Status ASR-Eingriff über EM-Regelung";
CM_ SG_ 1004 GE_Status_Kraftschluss "Zeigt den Ist-Status des Kraftschlusses im Getriebe.
(Anmerkung: meist wird damit der Zustand des Anfahrelements beschrieben, d.h. bei DL/DQ die Kupplung;  bei AQ/AL der Wandler incl. Überbrückungskupplung)
0 = offen, kein Kraftschluss
1 = offen mit Kr";
CM_ SG_ 1004 Getriebe_50_alt "Veraltet-Bit";
CM_ SG_ 1004 HC_Uss_Anforderung "Ansteuerung der vorderen PLA (VLS, VRS) und APS Sensoren (VL, VR)
0 = Ultraschallsensoren Aus
1 = Ultraschallsensoren An";
CM_ SG_ 1004 HD_Endstellung_oben "obere Endstellung HD
";
CM_ SG_ 1004 HD_Endstellung_unten "untere Endstellung HD";
CM_ SG_ 1004 HD_Position "HD Position von 0 bis 100 %";
CM_ SG_ 1004 KL_Vorwarn_Komp_ein "Vorwarnung Kompressor ein; 140ms vorher; Information für Motor zum Aufbau Momentenreserve";
CM_ SG_ 1004 MFL_Touch_Event "Touch_Events für Informationen einer Funktionsauslösung auf dem MFL, welches dann für bspw. ein akustisches Signal zentral umgesetzt werden können.";
CM_ SG_ 1004 MO_NGS_Position "Messwert des Neutralgangsensors
(nur Handschalter)";
CM_ SG_ 1004 MO_NGS_Status "Status des Signals MO_NGS_Position. Das MSG prüft die Plausibilität nur hinsichtlich sicher geöffnetem Triebstrang.";

CM_ SG_ 879 GNSS_Breite_Ortung "Breitengrad des Ortungsergebnisses nach WGS84 als Kombination von mehreren GNSSen";
CM_ SG_ 879 GNSS_Fehlerzustand "Fehlerzustand von der GNSS-Funktion, daraufhin können keine GNSS-Daten geliefert werden";
CM_ SG_ 879 GNSS_Laenge_Ortung "Längengrad des Ortungsergebnisses nach WGS84 als Kombination von mehreren GNSSen";
CM_ SG_ 879 GNSS_Nachrichtenpaket_ID1 "+1 für jedes neue Paket. Zyklische ID-Vergabe (Zähler). Zur Identifizierung zusammenhängender Nachrichten, die die Daten derselben GNSS-Ortung enthalten und somit zum selben Zyklus gehören. D.h. Daten in den Nachrichten wurden zur selben Zeit erzeugt. Der";
CM_ SG_ 879 GNSS_Ortung_FIX_Typ "Art des 'GNSS-Fix' für die aktuelle Position auf Basis mehrerer GNSS Systeme.";
CM_ SG_ 879 GNSS_Richtung_Breite_Ortung "Richtung des Breitengrads des Ortungsergebnisses nach WGS84 als Kombination von mehreren GNSSen";
CM_ SG_ 879 GNSS_Richtung_Laenge_Ortung "Richtung des Längengrads des Ortungsergebnisses nach WGS84 als Kombination von mehreren GNSSen";

CM_ SG_ 884 GNSS_Nachrichtenpaket_ID2 "+1 für jedes neue Paket. Zyklische ID-Vergabe (Zähler). Zur Identifizierung zusammenhängender Nachrichten, die die Daten derselben GNSS-Ortung enthalten und somit zum selben Zyklus gehören. D.h. Daten in den Nachrichten wurden zur selben Zeit erzeugt. Der";
CM_ SG_ 884 GNSS_Ortung_2D_Geschw_ue_Grund "Geschwindigkeit in m pro Sekunde entsprechend dem GNSS-Empfänger";
CM_ SG_ 884 GNSS_Ortung_Ausrichtung "Ausrichtung (Kurswinkel) der GNSS-Messung";
CM_ SG_ 884 GNSS_Ortung_Latenz "Latenz zwischen GNSS-Messung und aktueller Verteilung über CAN-Bus.
Hinweis: Zur Stabilisierung der Latenz soll die GNSS-Zeit für die Bestimmung der CAN-Zyklendauer verwendet werden.";
CM_ SG_ 884 GNSS_Ortung_Noerdliche_Geschw "Geschwindigkeit in m pro Sekunde in Nordrichtung entsprechend dem GNSS-Empfänger";
CM_ SG_ 884 GNSS_Ortung_Oestliche_Geschw "Geschwindigkeit in m pro Sekunde in Ostrichtung entsprechend dem GNSS-Empfänger";
CM_ SG_ 884 GNSS_Ortung_Vertikale_Geschw "Geschwindigkeit  in m pro Sekunde in vertikaler Richtung (aufwärts) entsprechend dem GNSS-Empfänger";
BA_DEF_REL_ BU_SG_REL_  "GenSigTimeoutTime" INT 0 65535;
BA_DEF_ BO_  "DiagRequest" ENUM "No", "Yes";
BA_DEF_ BO_  "DiagResponse" ENUM "No", "Yes";
BA_DEF_ BO_  "DiagState" ENUM "No", "Yes";
BA_DEF_ BO_  "GenMsgChkConstant" HEX 0 4095;
BA_DEF_ BO_  "GenMsgCycleTime" INT 0 65535;
BA_DEF_ BO_  "GenMsgCycleTimeFast" INT 0 65535;
BA_DEF_ BO_  "GenMsgDelayTime" INT 0 100000;
BA_DEF_ BO_  "GenMsgILSupport" ENUM "No", "Yes";
BA_DEF_ BO_  "GenMsgNrOfRepetition" INT 0 100;
BA_DEF_ BO_  "GenMsgPDUConstants" STRING;
BA_DEF_ BO_  "GenMsgSendType" ENUM "Cyclic", "not_used", "not_used", "not_used", "not_used", "not_used", "not_used", "IfActive", "NoMsgSendType";
BA_DEF_ BO_  "GenMsgStartDelayTime" INT 0 100000;
BA_DEF_ BO_  "NmMessage" ENUM "No", "Yes";
BA_DEF_ BO_  "NmhMessage" ENUM "No", "Yes";
BA_DEF_ BO_  "MsgType" ENUM "Application", "NM ", "NMH", "TP2.0", "ISO-TP ", "BAP", "EID", "KS", "XCP_PRE_CONFIGURED", "XCP_RUNTIME_CONFIGURED";
BA_DEF_ BO_  "VAGTP20_API" HEX 0 255;
BA_DEF_ BO_  "VAGTP20_DynConnection" ENUM "No", "Yes";
BA_DEF_ BO_  "VAGTP20_DynSetup" ENUM "No", "Yes";
BA_DEF_ BO_  "VAGTP20_StatConnection" ENUM "No", "Yes";
BA_DEF_ SG_  "GenSigActiveRepetitions" INT -2147483648 2147483647;
BA_DEF_ SG_  "GenSigInactiveValue" INT -2147483648 2147483647;
BA_DEF_ SG_  "GenSigSendType" ENUM "Cyclic", "OnWrite", "OnWriteWithRepetition", "OnChange", "OnChangeWithRepetition", "IfActive", "IfActiveWithRepetition", "NoSigSendType", "OnChangeAndIfActive", "OnChangeAndIfActiveWithRepetition";
BA_DEF_ SG_  "GenSigStartValue" INT -2147483648 2147483647;
BA_DEF_ SG_  "NWM-WakeupAllowed" ENUM "No", "Yes";
BA_DEF_ SG_  "GenSigFuncType" ENUM "NoFunction", "MsgCounter", "CRC-8", "XOR", "XOR-2", "DatedBit", "SW-Kl15", "CHK", "Constant", "Protocol", "CRC-8-SAE_J1850", "CRC-32", "DataLength", "DataID", "MsgCounter16", "SOK-Signatur", "Cluster";
BA_DEF_ SG_  "GenSigSwitchedByIgnition" ENUM "No", "Yes";
BA_DEF_ SG_  "Fehlerwert" HEX 0 2147483647;
BA_DEF_ SG_  "GenSigMissingSourceValue" HEX 0 2147483647;
BA_DEF_DEF_REL_  "GenSigTimeoutTime" 0;
BA_DEF_DEF_  "DiagRequest" "No";
BA_DEF_DEF_  "DiagResponse" "No";
BA_DEF_DEF_  "DiagState" "No";
BA_DEF_DEF_  "GenMsgChkConstant" 0;
BA_DEF_DEF_  "GenMsgCycleTime" 0;
BA_DEF_DEF_  "GenMsgCycleTimeFast" 0;
BA_DEF_DEF_  "GenMsgDelayTime" 0;
BA_DEF_DEF_  "GenMsgILSupport" "No";
BA_DEF_DEF_  "GenMsgNrOfRepetition" 0;
BA_DEF_DEF_  "GenMsgPDUConstants" "";
BA_DEF_DEF_  "GenMsgSendType" "NoMsgSendType";
BA_DEF_DEF_  "GenMsgStartDelayTime" 0;
BA_DEF_DEF_  "NmMessage" "No";
BA_DEF_DEF_  "NmhMessage" "No";
BA_DEF_DEF_  "MsgType" "Application";
BA_DEF_DEF_  "VAGTP20_API" 0;
BA_DEF_DEF_  "VAGTP20_DynConnection" "No";
BA_DEF_DEF_  "VAGTP20_DynSetup" "No";
BA_DEF_DEF_  "VAGTP20_StatConnection" "No";
BA_DEF_DEF_  "GenSigActiveRepetitions" 0;
BA_DEF_DEF_  "GenSigInactiveValue" 0;
BA_DEF_DEF_  "GenSigSendType" "NoSigSendType";
BA_DEF_DEF_  "GenSigStartValue" 0;
BA_DEF_DEF_  "NWM-WakeupAllowed" "No";
BA_DEF_DEF_  "GenSigFuncType" "NoFunction";
BA_DEF_DEF_  "GenSigSwitchedByIgnition" "Yes";
BA_DEF_DEF_  "Fehlerwert" 0;
BA_DEF_DEF_  "GenSigMissingSourceValue" 0;
BA_ "GenMsgCycleTime" BO_ 1520 200;
BA_ "GenMsgDelayTime" BO_ 1520 50;
BA_ "GenMsgILSupport" BO_ 1520 1;
BA_ "GenMsgSendType" BO_ 1520 0;
BA_ "GenMsgCycleTime" BO_ 1142 1000;
BA_ "GenMsgDelayTime" BO_ 1142 40;
BA_ "GenMsgILSupport" BO_ 1142 1;
BA_ "GenMsgSendType" BO_ 1142 0;
BA_ "GenMsgCycleTime" BO_ 1143 1000;
BA_ "GenMsgDelayTime" BO_ 1143 40;
BA_ "GenMsgILSupport" BO_ 1143 1;
BA_ "GenMsgSendType" BO_ 1143 0;
BA_ "GenMsgCycleTime" BO_ 561 200;
BA_ "GenMsgDelayTime" BO_ 561 20;
BA_ "GenMsgILSupport" BO_ 561 1;
BA_ "GenMsgSendType" BO_ 561 0;
BA_ "GenMsgCycleTime" BO_ 2527679886 1000;
BA_ "GenMsgCycleTimeFast" BO_ 2527679886 30;
BA_ "GenMsgDelayTime" BO_ 2527679886 30;
BA_ "GenMsgILSupport" BO_ 2527679886 1;
BA_ "GenMsgNrOfRepetition" BO_ 2527679886 5;
BA_ "GenMsgSendType" BO_ 2527679886 0;
BA_ "GenMsgCycleTime" BO_ 496 500;
BA_ "GenMsgDelayTime" BO_ 496 20;
BA_ "GenMsgILSupport" BO_ 496 1;
BA_ "GenMsgPDUConstants" BO_ 496 "0x2f,0x3c,0x22,0x60,0x18,0xeb,0x63,0x76,0xc5,0x91,0x0f,0x27,0x34,0x04,0x7f,0x02";
BA_ "GenMsgSendType" BO_ 496 0;
BA_ "MsgType" BO_ 2583717656 4;
BA_ "MsgType" BO_ 2583848728 4;
BA_ "GenMsgCycleTime" BO_ 1603 1000;
BA_ "GenMsgDelayTime" BO_ 1603 100;
BA_ "GenMsgILSupport" BO_ 1603 1;
BA_ "GenMsgSendType" BO_ 1603 0;
BA_ "GenMsgChkConstant" BO_ 257 170;
BA_ "GenMsgCycleTime" BO_ 257 20;
BA_ "GenMsgILSupport" BO_ 257 1;
BA_ "GenMsgPDUConstants" BO_ 257 "0xaa,0xaa,0xaa,0xaa,0xaa,0xaa,0xaa,0xaa,0xaa,0xaa,0xaa,0xaa,0xaa,0xaa,0xaa,0xaa";
BA_ "GenMsgSendType" BO_ 257 0;
BA_ "GenMsgChkConstant" BO_ 262 7;
BA_ "GenMsgCycleTime" BO_ 262 20;
BA_ "GenMsgILSupport" BO_ 262 1;
BA_ "GenMsgPDUConstants" BO_ 262 "0x07,0x07,0x07,0x07,0x07,0x07,0x07,0x07,0x07,0x07,0x07,0x07,0x07,0x07,0x07,0x07";
BA_ "GenMsgSendType" BO_ 262 0;
BA_ "GenMsgChkConstant" BO_ 278 172;
BA_ "GenMsgCycleTime" BO_ 278 200;
BA_ "GenMsgILSupport" BO_ 278 1;
BA_ "GenMsgPDUConstants" BO_ 278 "0xac,0xac,0xac,0xac,0xac,0xac,0xac,0xac,0xac,0xac,0xac,0xac,0xac,0xac,0xac,0xac";
BA_ "GenMsgSendType" BO_ 278 0;
BA_ "GenMsgCycleTime" BO_ 1629 1000;
BA_ "GenMsgDelayTime" BO_ 1629 200;
BA_ "GenMsgILSupport" BO_ 1629 1;
BA_ "GenMsgPDUConstants" BO_ 1629 "0xac,0xb3,0xab,0xeb,0x7a,0xe1,0x3b,0xf7,0x73,0xba,0x7c,0x9e,0x06,0x5f,0x02,0xd9";
BA_ "GenMsgSendType" BO_ 1629 0;
BA_ "GenMsgCycleTime" BO_ 253 20;
BA_ "GenMsgILSupport" BO_ 253 1;
BA_ "GenMsgPDUConstants" BO_ 253 "0xb4,0xef,0xf8,0x49,0x1e,0xe5,0xc2,0xc0,0x97,0x19,0x3c,0xc9,0xf1,0x98,0xd6,0x61";
BA_ "GenMsgSendType" BO_ 253 0;
BA_ "GenMsgCycleTime" BO_ 795 50;
BA_ "GenMsgILSupport" BO_ 795 1;
BA_ "GenMsgPDUConstants" BO_ 795 "0x67,0x8a,0xae,0x22,0x4d,0xd0,0x51,0x80,0x5c,0xb9,0xce,0x1e,0xdf,0x02,0x2d,0xd4";
BA_ "GenMsgSendType" BO_ 795 0;
BA_ "GenMsgCycleTime" BO_ 2589283617 1000;
BA_ "GenMsgDelayTime" BO_ 2589283617 50;
BA_ "GenMsgILSupport" BO_ 2589283617 1;
BA_ "GenMsgPDUConstants" BO_ 2589283617 "0xad,0xbd,0x5e,0x44,0x5b,0x90,0xb4,0x8d,0x9a,0x74,0xba,0xfa,0x2b,0x91,0xe2,0x89";
BA_ "GenMsgSendType" BO_ 2589283617 0;
BA_ "GenMsgCycleTime" BO_ 2589283684 1000;
BA_ "GenMsgCycleTimeFast" BO_ 2589283684 100;
BA_ "GenMsgDelayTime" BO_ 2589283684 100;
BA_ "GenMsgILSupport" BO_ 2589283684 1;
BA_ "GenMsgNrOfRepetition" BO_ 2589283684 3;
BA_ "GenMsgSendType" BO_ 2589283684 0;
BA_ "MsgType" BO_ 2549875571 4;
BA_ "MsgType" BO_ 2550006643 4;
BA_ "GenMsgCycleTime" BO_ 986 100;
BA_ "GenMsgDelayTime" BO_ 986 10;
BA_ "GenMsgILSupport" BO_ 986 1;
BA_ "GenMsgSendType" BO_ 986 0;
BA_ "GenMsgCycleTime" BO_ 988 50;
BA_ "GenMsgDelayTime" BO_ 988 10;
BA_ "GenMsgILSupport" BO_ 988 1;
BA_ "GenMsgSendType" BO_ 988 0;
BA_ "GenMsgCycleTime" BO_ 1002 200;
BA_ "GenMsgDelayTime" BO_ 1002 20;
BA_ "GenMsgILSupport" BO_ 1002 1;
BA_ "GenMsgSendType" BO_ 1002 0;
BA_ "GenMsgCycleTime" BO_ 1004 200;
BA_ "GenMsgDelayTime" BO_ 1004 20;
BA_ "GenMsgILSupport" BO_ 1004 1;
BA_ "GenMsgSendType" BO_ 1004 0;
BA_ "GenMsgCycleTime" BO_ 879 1000;
BA_ "GenMsgILSupport" BO_ 879 1;
BA_ "GenMsgSendType" BO_ 879 0;
BA_ "GenMsgCycleTime" BO_ 884 1000;
BA_ "GenMsgILSupport" BO_ 884 1;
BA_ "GenMsgSendType" BO_ 884 0;
BA_ "GenSigSendType" SG_ 1520 BCM1_Stellgroesse_Kl_58s 3;
BA_ "GenSigStartValue" SG_ 1520 BCM1_Stellgroesse_Kl_58s 126;
BA_ "GenSigSwitchedByIgnition" SG_ 1520 BCM1_Stellgroesse_Kl_58s 0;
BA_ "Fehlerwert" SG_ 1520 BCM1_Stellgroesse_Kl_58s 127;
BA_ "GenSigSendType" SG_ 1520 DI_Display_Nachtdesign 3;
BA_ "GenSigSwitchedByIgnition" SG_ 1520 DI_Display_Nachtdesign 0;
BA_ "GenSigSendType" SG_ 1520 DI_Fotosensor 3;
BA_ "GenSigSwitchedByIgnition" SG_ 1520 DI_Fotosensor 0;
BA_ "GenSigSendType" SG_ 1520 DI_KL_58xd 3;
BA_ "GenSigStartValue" SG_ 1520 DI_KL_58xd 254;
BA_ "GenSigSwitchedByIgnition" SG_ 1520 DI_KL_58xd 0;
BA_ "Fehlerwert" SG_ 1520 DI_KL_58xd 255;
BA_ "GenSigSendType" SG_ 1520 DI_KL_58xs 3;
BA_ "GenSigStartValue" SG_ 1520 DI_KL_58xs 126;
BA_ "GenSigSwitchedByIgnition" SG_ 1520 DI_KL_58xs 0;
BA_ "Fehlerwert" SG_ 1520 DI_KL_58xs 127;
BA_ "GenSigSendType" SG_ 1520 DI_KL_58xt 3;
BA_ "GenSigStartValue" SG_ 1520 DI_KL_58xt 126;
BA_ "GenSigSwitchedByIgnition" SG_ 1520 DI_KL_58xt 0;
BA_ "Fehlerwert" SG_ 1520 DI_KL_58xt 127;
BA_ "GenSigSendType" SG_ 1142 DU_DispDerating 0;
BA_ "GenSigStartValue" SG_ 1142 DU_DispDerating 254;
BA_ "GenSigSwitchedByIgnition" SG_ 1142 DU_DispDerating 0;
BA_ "Fehlerwert" SG_ 1142 DU_DispDerating 255;
BA_ "GenSigSendType" SG_ 1142 DU_KL30_Uebersp_Fehler 3;
BA_ "GenSigSwitchedByIgnition" SG_ 1142 DU_KL30_Uebersp_Fehler 0;
BA_ "Fehlerwert" SG_ 1142 DU_KL30_Uebersp_Fehler 1;
BA_ "GenSigSendType" SG_ 1142 DU_KL30_Untersp_Fehler 3;
BA_ "GenSigSwitchedByIgnition" SG_ 1142 DU_KL30_Untersp_Fehler 0;
BA_ "Fehlerwert" SG_ 1142 DU_KL30_Untersp_Fehler 1;
BA_ "GenSigSendType" SG_ 1142 DU_KL_30F 0;
BA_ "GenSigStartValue" SG_ 1142 DU_KL_30F 254;
BA_ "GenSigSwitchedByIgnition" SG_ 1142 DU_KL_30F 0;
BA_ "Fehlerwert" SG_ 1142 DU_KL_30F 255;
BA_ "GenSigSendType" SG_ 1142 DU_State 3;
BA_ "GenSigSwitchedByIgnition" SG_ 1142 DU_State 0;
BA_ "GenSigSendType" SG_ 1142 DU_Temp_Fehler 3;
BA_ "GenSigSwitchedByIgnition" SG_ 1142 DU_Temp_Fehler 0;
BA_ "Fehlerwert" SG_ 1142 DU_Temp_Fehler 1;
BA_ "GenSigSendType" SG_ 1142 DU_TempSens 0;
BA_ "GenSigStartValue" SG_ 1142 DU_TempSens 254;
BA_ "GenSigSwitchedByIgnition" SG_ 1142 DU_TempSens 0;
BA_ "Fehlerwert" SG_ 1142 DU_TempSens 255;
BA_ "GenSigSendType" SG_ 1142 DU_TempSensMax 0;
BA_ "GenSigStartValue" SG_ 1142 DU_TempSensMax 254;
BA_ "GenSigSwitchedByIgnition" SG_ 1142 DU_TempSensMax 0;
BA_ "Fehlerwert" SG_ 1142 DU_TempSensMax 255;
BA_ "GenSigSendType" SG_ 1142 DU_Variant 0;
BA_ "GenSigStartValue" SG_ 1142 DU_Variant 254;
BA_ "GenSigSwitchedByIgnition" SG_ 1142 DU_Variant 0;
BA_ "GenSigSendType" SG_ 1142 DU_Zulieferer 0;
BA_ "GenSigSwitchedByIgnition" SG_ 1142 DU_Zulieferer 0;
BA_ "GenSigSendType" SG_ 1142 FB_Mode 3;
BA_ "GenSigSwitchedByIgnition" SG_ 1142 FB_Mode 0;
BA_ "GenSigSendType" SG_ 1142 HU_Fotosensor 0;
BA_ "GenSigStartValue" SG_ 1142 HU_Fotosensor 510;
BA_ "GenSigSwitchedByIgnition" SG_ 1142 HU_Fotosensor 0;
BA_ "Fehlerwert" SG_ 1142 HU_Fotosensor 511;
BA_ "GenSigSendType" SG_ 1142 SystemMode 3;
BA_ "GenSigSwitchedByIgnition" SG_ 1142 SystemMode 0;
BA_ "GenSigSendType" SG_ 1143 DU1_Haptik_Fehlerstatus 0;
BA_ "GenSigSwitchedByIgnition" SG_ 1143 DU1_Haptik_Fehlerstatus 0;
BA_ "GenSigSendType" SG_ 1143 DU1_HDCP_Status 3;
BA_ "GenSigSwitchedByIgnition" SG_ 1143 DU1_HDCP_Status 0;
BA_ "Fehlerwert" SG_ 1143 DU1_HDCP_Status 1;
BA_ "GenSigSendType" SG_ 1143 DU1_LVDS_Splitter_Fehlerstatus 0;
BA_ "GenSigSwitchedByIgnition" SG_ 1143 DU1_LVDS_Splitter_Fehlerstatus 0;
BA_ "GenSigSendType" SG_ 1143 DU1_SW_inkonsistent 0;
BA_ "GenSigSwitchedByIgnition" SG_ 1143 DU1_SW_inkonsistent 0;
BA_ "Fehlerwert" SG_ 1143 DU1_SW_inkonsistent 1;
BA_ "GenSigSendType" SG_ 1143 DU1_Touch_Fehlerstatus 0;
BA_ "GenSigSwitchedByIgnition" SG_ 1143 DU1_Touch_Fehlerstatus 0;
BA_ "GenSigSendType" SG_ 1143 DU_Betriebsdauer_min 0;
BA_ "GenSigStartValue" SG_ 1143 DU_Betriebsdauer_min 254;
BA_ "GenSigSwitchedByIgnition" SG_ 1143 DU_Betriebsdauer_min 0;
BA_ "Fehlerwert" SG_ 1143 DU_Betriebsdauer_min 255;
BA_ "GenSigSendType" SG_ 1143 DU_Betriebsdauer_std 0;
BA_ "GenSigStartValue" SG_ 1143 DU_Betriebsdauer_std 65534;
BA_ "GenSigSwitchedByIgnition" SG_ 1143 DU_Betriebsdauer_std 0;
BA_ "Fehlerwert" SG_ 1143 DU_Betriebsdauer_std 65535;
BA_ "GenSigSendType" SG_ 1143 DU_HintGrdBelKurzschl 3;
BA_ "GenSigSwitchedByIgnition" SG_ 1143 DU_HintGrdBelKurzschl 0;
BA_ "Fehlerwert" SG_ 1143 DU_HintGrdBelKurzschl 1;
BA_ "GenSigSendType" SG_ 1143 DU_HintGrdBelUnterbr 3;
BA_ "GenSigSwitchedByIgnition" SG_ 1143 DU_HintGrdBelUnterbr 0;
BA_ "Fehlerwert" SG_ 1143 DU_HintGrdBelUnterbr 1;
BA_ "GenSigSendType" SG_ 1143 EEPROM_Fehler 3;
BA_ "GenSigSwitchedByIgnition" SG_ 1143 EEPROM_Fehler 0;
BA_ "Fehlerwert" SG_ 1143 EEPROM_Fehler 1;
BA_ "GenSigSendType" SG_ 1143 LVDS_Status 3;
BA_ "GenSigSwitchedByIgnition" SG_ 1143 LVDS_Status 0;
BA_ "GenSigSendType" SG_ 1143 ZR_Lenkerpos_Status 0;
BA_ "GenSigSwitchedByIgnition" SG_ 1143 ZR_Lenkerpos_Status 0;
BA_ "GenSigSendType" SG_ 561 DU1_Fehlerstatus 3;
BA_ "GenSigSwitchedByIgnition" SG_ 561 DU1_Fehlerstatus 0;
BA_ "GenSigSendType" SG_ 561 DU1_HWR_Fehlerstatus 0;
BA_ "GenSigSwitchedByIgnition" SG_ 561 DU1_HWR_Fehlerstatus 0;
BA_ "GenSigSendType" SG_ 561 DU1_KS_aktiv_anderer_Grund 3;
BA_ "GenSigSwitchedByIgnition" SG_ 561 DU1_KS_aktiv_anderer_Grund 0;
BA_ "Fehlerwert" SG_ 561 DU1_KS_aktiv_anderer_Grund 1;
BA_ "GenSigSendType" SG_ 561 DU1_KS_aktiv_falsche_Auth 3;
BA_ "GenSigSwitchedByIgnition" SG_ 561 DU1_KS_aktiv_falsche_Auth 0;
BA_ "Fehlerwert" SG_ 561 DU1_KS_aktiv_falsche_Auth 1;
BA_ "GenSigSendType" SG_ 561 DU1_KS_aktiv_Manipulationsschutz 3;
BA_ "GenSigSwitchedByIgnition" SG_ 561 DU1_KS_aktiv_Manipulationsschutz 0;
BA_ "Fehlerwert" SG_ 561 DU1_KS_aktiv_Manipulationsschutz 1;
BA_ "GenSigSendType" SG_ 561 DU1_KS_FIS_unplausibel 3;
BA_ "GenSigSwitchedByIgnition" SG_ 561 DU1_KS_FIS_unplausibel 0;
BA_ "Fehlerwert" SG_ 561 DU1_KS_FIS_unplausibel 1;
BA_ "GenSigSendType" SG_ 561 DU1_KS_keine_Grundeinstellung 3;
BA_ "GenSigSwitchedByIgnition" SG_ 561 DU1_KS_keine_Grundeinstellung 0;
BA_ "Fehlerwert" SG_ 561 DU1_KS_keine_Grundeinstellung 1;
BA_ "GenSigSendType" SG_ 561 DU1_KS_SHE_keine_Grundeinst 3;
BA_ "GenSigSwitchedByIgnition" SG_ 561 DU1_KS_SHE_keine_Grundeinst 0;
BA_ "Fehlerwert" SG_ 561 DU1_KS_SHE_keine_Grundeinst 1;
BA_ "GenSigSendType" SG_ 561 DU1_Slider_Locked 3;
BA_ "GenSigSwitchedByIgnition" SG_ 561 DU1_Slider_Locked 0;
BA_ "GenSigSendType" SG_ 561 DU1_Touchstatus 3;
BA_ "GenSigSwitchedByIgnition" SG_ 561 DU1_Touchstatus 0;
BA_ "GenSigSendType" SG_ 2527679886 BedienDisp_m_Control 9;
BA_ "GenSigSwitchedByIgnition" SG_ 2527679886 BedienDisp_m_Control 0;
BA_ "Fehlerwert" SG_ 2527679886 BedienDisp_m_Control 15;
BA_ "GenSigSendType" SG_ 2527679886 Drehschalter_Aktive_Ebene 4;
BA_ "GenSigSwitchedByIgnition" SG_ 2527679886 Drehschalter_Aktive_Ebene 0;
BA_ "GenSigSendType" SG_ 2527679886 Drehschalter_defekt 4;
BA_ "GenSigSwitchedByIgnition" SG_ 2527679886 Drehschalter_defekt 0;
BA_ "GenSigSendType" SG_ 2527679886 Drehschalter_Display_Action 4;
BA_ "GenSigSwitchedByIgnition" SG_ 2527679886 Drehschalter_Display_Action 0;
BA_ "GenSigSendType" SG_ 2527679886 Drehschalter_Ist_Atmosphere 4;
BA_ "GenSigSwitchedByIgnition" SG_ 2527679886 Drehschalter_Ist_Atmosphere 0;
BA_ "GenSigSendType" SG_ 2527679886 Drehschalter_Ist_Profil 4;
BA_ "GenSigSwitchedByIgnition" SG_ 2527679886 Drehschalter_Ist_Profil 0;
BA_ "GenSigSendType" SG_ 2527679886 Drehschalter_Taster 4;
BA_ "GenSigSwitchedByIgnition" SG_ 2527679886 Drehschalter_Taster 0;
BA_ "GenSigSendType" SG_ 2527679886 Drehschalter_Touch 4;
BA_ "GenSigSwitchedByIgnition" SG_ 2527679886 Drehschalter_Touch 0;
BA_ "Fehlerwert" SG_ 2527679886 Drehschalter_Touch 15;
BA_ "GenSigSendType" SG_ 496 ACF_Lampe_Hands_Off 3;
BA_ "GenSigSendType" SG_ 496 EA_02_BZ 0;
BA_ "GenSigFuncType" SG_ 496 EA_02_BZ 1;
BA_ "GenSigSendType" SG_ 496 EA_02_CRC 0;
BA_ "GenSigFuncType" SG_ 496 EA_02_CRC 2;
BA_ "GenSigSendType" SG_ 496 EA_Blinken 3;
BA_ "GenSigSendType" SG_ 496 EA_Bremslichtblinken 3;
BA_ "GenSigSendType" SG_ 496 EA_eCall_Anf 3;
BA_ "GenSigSendType" SG_ 496 EA_Fahrzeughupe_Anf 3;
BA_ "GenSigSendType" SG_ 496 EA_Infotainment_Anf 3;
BA_ "GenSigSendType" SG_ 496 EA_Innenraumlicht_Anf 3;
BA_ "GenSigSendType" SG_ 496 EA_Status_HMI 3;
BA_ "GenSigSendType" SG_ 496 EA_Texte 3;
BA_ "GenSigSendType" SG_ 496 EA_Tueren_Anf 3;
BA_ "GenSigSendType" SG_ 496 EA_Warnlevel 3;
BA_ "GenSigSendType" SG_ 496 STP_Primaeranz 3;
BA_ "GenSigSendType" SG_ 496 zFAS_Warnblinken 3;
BA_ "GenSigSendType" SG_ 2583717656 eCall_AuthTime_Req_Data 3;
BA_ "GenSigFuncType" SG_ 2583717656 eCall_AuthTime_Req_Data 9;
BA_ "GenSigSwitchedByIgnition" SG_ 2583717656 eCall_AuthTime_Req_Data 0;
BA_ "GenSigSendType" SG_ 2583848728 eCall_AuthTime_Resp_Data 3;
BA_ "GenSigFuncType" SG_ 2583848728 eCall_AuthTime_Resp_Data 9;
BA_ "GenSigSwitchedByIgnition" SG_ 2583848728 eCall_AuthTime_Resp_Data 0;
BA_ "GenSigSendType" SG_ 1603 KBI_Einheit_Datum 3;
BA_ "GenSigSwitchedByIgnition" SG_ 1603 KBI_Einheit_Datum 0;
BA_ "GenSigSendType" SG_ 1603 KBI_Einheit_Druck 3;
BA_ "GenSigSwitchedByIgnition" SG_ 1603 KBI_Einheit_Druck 0;
BA_ "GenSigSendType" SG_ 1603 KBI_Einheit_Masse 3;
BA_ "GenSigSwitchedByIgnition" SG_ 1603 KBI_Einheit_Masse 0;
BA_ "GenSigSendType" SG_ 1603 KBI_Einheit_Sprache 3;
BA_ "GenSigSwitchedByIgnition" SG_ 1603 KBI_Einheit_Sprache 0;
BA_ "GenSigSendType" SG_ 1603 KBI_Einheit_Streckenanz 3;
BA_ "GenSigSwitchedByIgnition" SG_ 1603 KBI_Einheit_Streckenanz 0;
BA_ "GenSigSendType" SG_ 1603 KBI_Einheit_Tacho 3;
BA_ "GenSigSwitchedByIgnition" SG_ 1603 KBI_Einheit_Tacho 0;
BA_ "GenSigSendType" SG_ 1603 KBI_Einheit_Temp 3;
BA_ "GenSigSwitchedByIgnition" SG_ 1603 KBI_Einheit_Temp 0;
BA_ "GenSigSendType" SG_ 1603 KBI_Einheit_Uhrzeit 3;
BA_ "GenSigSwitchedByIgnition" SG_ 1603 KBI_Einheit_Uhrzeit 0;
BA_ "GenSigSendType" SG_ 1603 KBI_Einheit_Verbrauch 3;
BA_ "GenSigSwitchedByIgnition" SG_ 1603 KBI_Einheit_Verbrauch 0;
BA_ "GenSigSendType" SG_ 1603 KBI_Einheit_Verbrauch_elektr 3;
BA_ "GenSigSwitchedByIgnition" SG_ 1603 KBI_Einheit_Verbrauch_elektr 0;
BA_ "GenSigSendType" SG_ 1603 KBI_Einheit_Verbrauch_Gas 3;
BA_ "GenSigSwitchedByIgnition" SG_ 1603 KBI_Einheit_Verbrauch_Gas 0;
BA_ "GenSigSendType" SG_ 1603 KBI_Einheit_Volumen 3;
BA_ "GenSigSwitchedByIgnition" SG_ 1603 KBI_Einheit_Volumen 0;
BA_ "GenSigSendType" SG_ 1603 KBI_MFA_v_Einheit_02 3;
BA_ "GenSigSwitchedByIgnition" SG_ 1603 KBI_MFA_v_Einheit_02 0;
BA_ "GenSigSendType" SG_ 257 ESC_Motorstartverzoegerung 0;
BA_ "GenSigSwitchedByIgnition" SG_ 257 ESC_Motorstartverzoegerung 0;
BA_ "GenSigSendType" SG_ 257 ESC_SeitenwindAssistent_Eingriff 0;
BA_ "GenSigSwitchedByIgnition" SG_ 257 ESC_SeitenwindAssistent_Eingriff 0;
BA_ "GenSigSendType" SG_ 257 ESC_Unterdruckmangel_erkannt 0;
BA_ "GenSigSwitchedByIgnition" SG_ 257 ESC_Unterdruckmangel_erkannt 0;
BA_ "GenSigSendType" SG_ 257 ESP_Anschleppstart_Freigabe 0;
BA_ "GenSigSwitchedByIgnition" SG_ 257 ESP_Anschleppstart_Freigabe 0;
BA_ "GenSigSendType" SG_ 257 ESP_Gierrate 0;
BA_ "GenSigSwitchedByIgnition" SG_ 257 ESP_Gierrate 0;
BA_ "Fehlerwert" SG_ 257 ESP_Gierrate 16383;
BA_ "GenSigSendType" SG_ 257 ESP_Laengsbeschl 0;
BA_ "GenSigStartValue" SG_ 257 ESP_Laengsbeschl 512;
BA_ "GenSigSwitchedByIgnition" SG_ 257 ESP_Laengsbeschl 0;
BA_ "Fehlerwert" SG_ 257 ESP_Laengsbeschl 1023;
BA_ "GenSigSendType" SG_ 257 ESP_Notbremsanzeige 0;
BA_ "GenSigSwitchedByIgnition" SG_ 257 ESP_Notbremsanzeige 0;
BA_ "GenSigSendType" SG_ 257 ESP_PLA_Abbruch 0;
BA_ "GenSigSwitchedByIgnition" SG_ 257 ESP_PLA_Abbruch 0;
BA_ "GenSigSendType" SG_ 257 ESP_QBit_Gierrate 0;
BA_ "GenSigStartValue" SG_ 257 ESP_QBit_Gierrate 1;
BA_ "GenSigSwitchedByIgnition" SG_ 257 ESP_QBit_Gierrate 0;
BA_ "GenSigSendType" SG_ 257 ESP_QBit_Laengsbeschl 0;
BA_ "GenSigStartValue" SG_ 257 ESP_QBit_Laengsbeschl 1;
BA_ "GenSigSwitchedByIgnition" SG_ 257 ESP_QBit_Laengsbeschl 0;
BA_ "GenSigSendType" SG_ 257 ESP_QBit_Querb 0;
BA_ "GenSigStartValue" SG_ 257 ESP_QBit_Querb 1;
BA_ "GenSigSwitchedByIgnition" SG_ 257 ESP_QBit_Querb 0;
BA_ "GenSigSendType" SG_ 257 ESP_Querbeschleunigung 0;
BA_ "GenSigStartValue" SG_ 257 ESP_Querbeschleunigung 127;
BA_ "GenSigSwitchedByIgnition" SG_ 257 ESP_Querbeschleunigung 0;
BA_ "Fehlerwert" SG_ 257 ESP_Querbeschleunigung 255;
BA_ "GenSigSendType" SG_ 257 ESP_SpannungsAnf 0;
BA_ "GenSigSwitchedByIgnition" SG_ 257 ESP_SpannungsAnf 0;
BA_ "GenSigSendType" SG_ 257 ESP_Status_ESP_PLA 0;
BA_ "GenSigSwitchedByIgnition" SG_ 257 ESP_Status_ESP_PLA 0;
BA_ "GenSigSendType" SG_ 257 ESP_VZ_Gierrate 0;
BA_ "GenSigSwitchedByIgnition" SG_ 257 ESP_VZ_Gierrate 0;
BA_ "GenSigSendType" SG_ 262 ECD_Bremslicht 0;
BA_ "GenSigSwitchedByIgnition" SG_ 262 ECD_Bremslicht 0;
BA_ "GenSigSendType" SG_ 262 ECD_Fehler 0;
BA_ "GenSigSwitchedByIgnition" SG_ 262 ECD_Fehler 0;
BA_ "GenSigSendType" SG_ 262 ECD_nicht_verfuegbar 0;
BA_ "GenSigStartValue" SG_ 262 ECD_nicht_verfuegbar 1;
BA_ "GenSigSwitchedByIgnition" SG_ 262 ECD_nicht_verfuegbar 0;
BA_ "GenSigSendType" SG_ 262 ESP_Anforderung_EPB 0;
BA_ "GenSigSwitchedByIgnition" SG_ 262 ESP_Anforderung_EPB 0;
BA_ "GenSigSendType" SG_ 262 ESP_Autohold_aktiv 0;
BA_ "GenSigSwitchedByIgnition" SG_ 262 ESP_Autohold_aktiv 0;
BA_ "GenSigSendType" SG_ 262 ESP_Autohold_Standby 0;
BA_ "GenSigSwitchedByIgnition" SG_ 262 ESP_Autohold_Standby 0;
BA_ "GenSigSendType" SG_ 262 ESP_BKV_Unterdruck 0;
BA_ "GenSigStartValue" SG_ 262 ESP_BKV_Unterdruck 254;
BA_ "GenSigSwitchedByIgnition" SG_ 262 ESP_BKV_Unterdruck 0;
BA_ "Fehlerwert" SG_ 262 ESP_BKV_Unterdruck 255;
BA_ "GenSigSendType" SG_ 262 ESP_Bremsdruck 0;
BA_ "GenSigStartValue" SG_ 262 ESP_Bremsdruck 100;
BA_ "GenSigSwitchedByIgnition" SG_ 262 ESP_Bremsdruck 0;
BA_ "Fehlerwert" SG_ 262 ESP_Bremsdruck 1023;
BA_ "GenSigSendType" SG_ 262 ESP_Bremsruck_AWV2 0;
BA_ "GenSigSwitchedByIgnition" SG_ 262 ESP_Bremsruck_AWV2 0;
BA_ "GenSigSendType" SG_ 262 ESP_Eingr_HL 0;
BA_ "GenSigSwitchedByIgnition" SG_ 262 ESP_Eingr_HL 0;
BA_ "GenSigSendType" SG_ 262 ESP_Eingr_HR 0;
BA_ "GenSigSwitchedByIgnition" SG_ 262 ESP_Eingr_HR 0;
BA_ "GenSigSendType" SG_ 262 ESP_Eingr_VL 0;
BA_ "GenSigSwitchedByIgnition" SG_ 262 ESP_Eingr_VL 0;
BA_ "GenSigSendType" SG_ 262 ESP_Eingr_VR 0;
BA_ "GenSigSwitchedByIgnition" SG_ 262 ESP_Eingr_VR 0;
BA_ "GenSigSendType" SG_ 262 ESP_Fahrer_bremst 0;
BA_ "GenSigSwitchedByIgnition" SG_ 262 ESP_Fahrer_bremst 0;
BA_ "GenSigSendType" SG_ 262 ESP_FStatus_Anfahrhilfe 0;
BA_ "GenSigSwitchedByIgnition" SG_ 262 ESP_FStatus_Anfahrhilfe 0;
BA_ "Fehlerwert" SG_ 262 ESP_FStatus_Anfahrhilfe 1;
BA_ "GenSigSendType" SG_ 262 ESP_HBA_aktiv 0;
BA_ "GenSigSwitchedByIgnition" SG_ 262 ESP_HBA_aktiv 0;
BA_ "GenSigSendType" SG_ 262 ESP_HDC_aktiv 0;
BA_ "GenSigSwitchedByIgnition" SG_ 262 ESP_HDC_aktiv 0;
BA_ "GenSigSendType" SG_ 262 ESP_HDC_Standby 0;
BA_ "GenSigSwitchedByIgnition" SG_ 262 ESP_HDC_Standby 0;
BA_ "GenSigSendType" SG_ 262 ESP_Konsistenz_AWV2 0;
BA_ "GenSigSwitchedByIgnition" SG_ 262 ESP_Konsistenz_AWV2 0;
BA_ "GenSigSendType" SG_ 262 ESP_Konsistenz_TSK 0;
BA_ "GenSigSwitchedByIgnition" SG_ 262 ESP_Konsistenz_TSK 0;
BA_ "GenSigSendType" SG_ 262 ESP_Lenkeingriff_ADS 0;
BA_ "GenSigSwitchedByIgnition" SG_ 262 ESP_Lenkeingriff_ADS 0;
BA_ "GenSigSendType" SG_ 262 ESP_Prefill_ausgeloest 0;
BA_ "GenSigSwitchedByIgnition" SG_ 262 ESP_Prefill_ausgeloest 0;
BA_ "GenSigSendType" SG_ 262 ESP_QBit_Bremsdruck 0;
BA_ "GenSigStartValue" SG_ 262 ESP_QBit_Bremsdruck 1;
BA_ "GenSigSwitchedByIgnition" SG_ 262 ESP_QBit_Bremsdruck 0;
BA_ "GenSigSendType" SG_ 262 ESP_QBit_Fahrer_bremst 0;
BA_ "GenSigStartValue" SG_ 262 ESP_QBit_Fahrer_bremst 1;
BA_ "GenSigSwitchedByIgnition" SG_ 262 ESP_QBit_Fahrer_bremst 0;
BA_ "GenSigSendType" SG_ 262 ESP_Rueckwaertsfahrt_erkannt 0;
BA_ "GenSigSwitchedByIgnition" SG_ 262 ESP_Rueckwaertsfahrt_erkannt 0;
BA_ "GenSigSendType" SG_ 262 ESP_Schwelle_Unterdruck 0;
BA_ "GenSigSwitchedByIgnition" SG_ 262 ESP_Schwelle_Unterdruck 0;
BA_ "GenSigSendType" SG_ 262 ESP_StartStopp_Info 0;
BA_ "GenSigSwitchedByIgnition" SG_ 262 ESP_StartStopp_Info 0;
BA_ "GenSigSendType" SG_ 262 ESP_Status_Anfahrhilfe 0;
BA_ "GenSigSwitchedByIgnition" SG_ 262 ESP_Status_Anfahrhilfe 0;
BA_ "GenSigSendType" SG_ 262 ESP_Status_Bremsdruck 0;
BA_ "GenSigSwitchedByIgnition" SG_ 262 ESP_Status_Bremsdruck 0;
BA_ "GenSigSendType" SG_ 262 ESP_Status_Bremsentemp 0;
BA_ "GenSigSwitchedByIgnition" SG_ 262 ESP_Status_Bremsentemp 0;
BA_ "GenSigSendType" SG_ 262 ESP_Verz_EPB_aktiv 0;
BA_ "GenSigSwitchedByIgnition" SG_ 262 ESP_Verz_EPB_aktiv 0;
BA_ "GenSigSendType" SG_ 262 ESP_Verz_TSK_aktiv 0;
BA_ "GenSigSwitchedByIgnition" SG_ 262 ESP_Verz_TSK_aktiv 0;
BA_ "GenSigSendType" SG_ 262 ESP_Verzoeg_EPB_verf 0;
BA_ "GenSigSwitchedByIgnition" SG_ 262 ESP_Verzoeg_EPB_verf 0;
BA_ "GenSigSendType" SG_ 278 ESP_10_BZ 0;
BA_ "GenSigFuncType" SG_ 278 ESP_10_BZ 1;
BA_ "GenSigSwitchedByIgnition" SG_ 278 ESP_10_BZ 0;
BA_ "GenSigSendType" SG_ 278 ESP_10_CRC 0;
BA_ "GenSigFuncType" SG_ 278 ESP_10_CRC 2;
BA_ "GenSigSwitchedByIgnition" SG_ 278 ESP_10_CRC 0;
BA_ "GenSigSendType" SG_ 278 ESP_HL_Fahrtrichtung 0;
BA_ "GenSigStartValue" SG_ 278 ESP_HL_Fahrtrichtung 2;
BA_ "GenSigSwitchedByIgnition" SG_ 278 ESP_HL_Fahrtrichtung 0;
BA_ "GenSigSendType" SG_ 278 ESP_HR_Fahrtrichtung 0;
BA_ "GenSigStartValue" SG_ 278 ESP_HR_Fahrtrichtung 2;
BA_ "GenSigSwitchedByIgnition" SG_ 278 ESP_HR_Fahrtrichtung 0;
BA_ "GenSigSendType" SG_ 278 ESP_QBit_Wegimpuls_HL 0;
BA_ "GenSigStartValue" SG_ 278 ESP_QBit_Wegimpuls_HL 1;
BA_ "GenSigSwitchedByIgnition" SG_ 278 ESP_QBit_Wegimpuls_HL 0;
BA_ "GenSigSendType" SG_ 278 ESP_QBit_Wegimpuls_HR 0;
BA_ "GenSigStartValue" SG_ 278 ESP_QBit_Wegimpuls_HR 1;
BA_ "GenSigSwitchedByIgnition" SG_ 278 ESP_QBit_Wegimpuls_HR 0;
BA_ "GenSigSendType" SG_ 278 ESP_QBit_Wegimpuls_VL 0;
BA_ "GenSigStartValue" SG_ 278 ESP_QBit_Wegimpuls_VL 1;
BA_ "GenSigSwitchedByIgnition" SG_ 278 ESP_QBit_Wegimpuls_VL 0;
BA_ "GenSigSendType" SG_ 278 ESP_QBit_Wegimpuls_VR 0;
BA_ "GenSigStartValue" SG_ 278 ESP_QBit_Wegimpuls_VR 1;
BA_ "GenSigSwitchedByIgnition" SG_ 278 ESP_QBit_Wegimpuls_VR 0;
BA_ "GenSigSendType" SG_ 278 ESP_VL_Fahrtrichtung 0;
BA_ "GenSigStartValue" SG_ 278 ESP_VL_Fahrtrichtung 2;
BA_ "GenSigSwitchedByIgnition" SG_ 278 ESP_VL_Fahrtrichtung 0;
BA_ "GenSigSendType" SG_ 278 ESP_VR_Fahrtrichtung 0;
BA_ "GenSigStartValue" SG_ 278 ESP_VR_Fahrtrichtung 2;
BA_ "GenSigSwitchedByIgnition" SG_ 278 ESP_VR_Fahrtrichtung 0;
BA_ "GenSigSendType" SG_ 278 ESP_Wegimpuls_HL 0;
BA_ "GenSigStartValue" SG_ 278 ESP_Wegimpuls_HL 1021;
BA_ "GenSigSwitchedByIgnition" SG_ 278 ESP_Wegimpuls_HL 0;
BA_ "Fehlerwert" SG_ 278 ESP_Wegimpuls_HL 1023;
BA_ "GenSigSendType" SG_ 278 ESP_Wegimpuls_HR 0;
BA_ "GenSigStartValue" SG_ 278 ESP_Wegimpuls_HR 1021;
BA_ "GenSigSwitchedByIgnition" SG_ 278 ESP_Wegimpuls_HR 0;
BA_ "Fehlerwert" SG_ 278 ESP_Wegimpuls_HR 1023;
BA_ "GenSigSendType" SG_ 278 ESP_Wegimpuls_VL 0;
BA_ "GenSigStartValue" SG_ 278 ESP_Wegimpuls_VL 1021;
BA_ "GenSigSwitchedByIgnition" SG_ 278 ESP_Wegimpuls_VL 0;
BA_ "Fehlerwert" SG_ 278 ESP_Wegimpuls_VL 1023;
BA_ "GenSigSendType" SG_ 278 ESP_Wegimpuls_VR 0;
BA_ "GenSigStartValue" SG_ 278 ESP_Wegimpuls_VR 1021;
BA_ "GenSigSwitchedByIgnition" SG_ 278 ESP_Wegimpuls_VR 0;
BA_ "Fehlerwert" SG_ 278 ESP_Wegimpuls_VR 1023;
BA_ "GenSigSendType" SG_ 1629 BR_QBit_Reifenumfang 0;
BA_ "GenSigStartValue" SG_ 1629 BR_QBit_Reifenumfang 1;
BA_ "GenSigSwitchedByIgnition" SG_ 1629 BR_QBit_Reifenumfang 0;
BA_ "GenSigSendType" SG_ 1629 BR_Reifenumfang 0;
BA_ "GenSigSwitchedByIgnition" SG_ 1629 BR_Reifenumfang 0;
BA_ "GenSigSendType" SG_ 1629 BR_Systemart 0;
BA_ "GenSigFuncType" SG_ 1629 BR_Systemart 8;
BA_ "GenSigSwitchedByIgnition" SG_ 1629 BR_Systemart 0;
BA_ "GenSigSendType" SG_ 1629 ESP_20_BZ 0;
BA_ "GenSigFuncType" SG_ 1629 ESP_20_BZ 1;
BA_ "GenSigSwitchedByIgnition" SG_ 1629 ESP_20_BZ 0;
BA_ "GenSigSendType" SG_ 1629 ESP_20_CRC 0;
BA_ "GenSigFuncType" SG_ 1629 ESP_20_CRC 2;
BA_ "GenSigSwitchedByIgnition" SG_ 1629 ESP_20_CRC 0;
BA_ "GenSigSendType" SG_ 1629 ESP_Charisma_FahrPr 3;
BA_ "GenSigSwitchedByIgnition" SG_ 1629 ESP_Charisma_FahrPr 0;
BA_ "GenSigSendType" SG_ 1629 ESP_Charisma_Status 3;
BA_ "GenSigSwitchedByIgnition" SG_ 1629 ESP_Charisma_Status 0;
BA_ "GenSigSendType" SG_ 1629 ESP_Dachrelingsensor 0;
BA_ "GenSigSwitchedByIgnition" SG_ 1629 ESP_Dachrelingsensor 0;
BA_ "Fehlerwert" SG_ 1629 ESP_Dachrelingsensor 3;
BA_ "GenSigSendType" SG_ 1629 ESP_SpannungsAnf_02 3;
BA_ "GenSigSwitchedByIgnition" SG_ 1629 ESP_SpannungsAnf_02 0;
BA_ "GenSigSendType" SG_ 1629 ESP_Stoppverbot_Anz_01 3;
BA_ "GenSigSwitchedByIgnition" SG_ 1629 ESP_Stoppverbot_Anz_01 0;
BA_ "GenSigSendType" SG_ 1629 ESP_Stoppverbot_Anz_02 3;
BA_ "GenSigSwitchedByIgnition" SG_ 1629 ESP_Stoppverbot_Anz_02 0;
BA_ "GenSigSendType" SG_ 1629 ESP_Stoppverbot_Anz_03 3;
BA_ "GenSigSwitchedByIgnition" SG_ 1629 ESP_Stoppverbot_Anz_03 0;
BA_ "GenSigSendType" SG_ 1629 ESP_Stoppverbot_Anz_04 3;
BA_ "GenSigSwitchedByIgnition" SG_ 1629 ESP_Stoppverbot_Anz_04 0;
BA_ "GenSigSendType" SG_ 1629 ESP_Stoppverbot_Anz_05 3;
BA_ "GenSigSwitchedByIgnition" SG_ 1629 ESP_Stoppverbot_Anz_05 0;
BA_ "GenSigSendType" SG_ 1629 ESP_Stoppverbot_Anz_06 3;
BA_ "GenSigSwitchedByIgnition" SG_ 1629 ESP_Stoppverbot_Anz_06 0;
BA_ "GenSigSendType" SG_ 1629 ESP_Stoppverbot_Anz_07 3;
BA_ "GenSigSwitchedByIgnition" SG_ 1629 ESP_Stoppverbot_Anz_07 0;
BA_ "GenSigSendType" SG_ 1629 ESP_Stoppverbot_Anz_08 3;
BA_ "GenSigSwitchedByIgnition" SG_ 1629 ESP_Stoppverbot_Anz_08 0;
BA_ "GenSigSendType" SG_ 1629 ESP_Stoppverbot_Anz_Std 3;
BA_ "GenSigSwitchedByIgnition" SG_ 1629 ESP_Stoppverbot_Anz_Std 0;
BA_ "GenSigSendType" SG_ 1629 ESP_Wiederstart_Anz_01 3;
BA_ "GenSigSwitchedByIgnition" SG_ 1629 ESP_Wiederstart_Anz_01 0;
BA_ "GenSigSendType" SG_ 1629 ESP_Wiederstart_Anz_02 3;
BA_ "GenSigSwitchedByIgnition" SG_ 1629 ESP_Wiederstart_Anz_02 0;
BA_ "GenSigSendType" SG_ 1629 ESP_Wiederstart_Anz_03 3;
BA_ "GenSigSwitchedByIgnition" SG_ 1629 ESP_Wiederstart_Anz_03 0;
BA_ "GenSigSendType" SG_ 1629 ESP_Wiederstart_Anz_04 3;
BA_ "GenSigSwitchedByIgnition" SG_ 1629 ESP_Wiederstart_Anz_04 0;
BA_ "GenSigSendType" SG_ 1629 ESP_Zaehnezahl 0;
BA_ "GenSigFuncType" SG_ 1629 ESP_Zaehnezahl 8;
BA_ "GenSigSwitchedByIgnition" SG_ 1629 ESP_Zaehnezahl 0;
BA_ "GenSigSendType" SG_ 1629 HDC_Charisma_FahrPr 3;
BA_ "GenSigSwitchedByIgnition" SG_ 1629 HDC_Charisma_FahrPr 0;
BA_ "GenSigSendType" SG_ 1629 HDC_Charisma_Status 3;
BA_ "GenSigSwitchedByIgnition" SG_ 1629 HDC_Charisma_Status 0;
BA_ "GenSigSendType" SG_ 253 ABS_Bremsung 0;
BA_ "GenSigSwitchedByIgnition" SG_ 253 ABS_Bremsung 0;
BA_ "GenSigSendType" SG_ 253 ASR_Anf 0;
BA_ "GenSigSwitchedByIgnition" SG_ 253 ASR_Anf 0;
BA_ "GenSigSendType" SG_ 253 ASR_Schalteingriff 0;
BA_ "GenSigSwitchedByIgnition" SG_ 253 ASR_Schalteingriff 0;
BA_ "GenSigSendType" SG_ 253 ASR_Tastung_passiv 0;
BA_ "GenSigSwitchedByIgnition" SG_ 253 ASR_Tastung_passiv 0;
BA_ "GenSigSendType" SG_ 253 BR_Eingriffsmoment 0;
BA_ "GenSigStartValue" SG_ 253 BR_Eingriffsmoment 1022;
BA_ "GenSigSwitchedByIgnition" SG_ 253 BR_Eingriffsmoment 0;
BA_ "Fehlerwert" SG_ 253 BR_Eingriffsmoment 1023;
BA_ "GenSigSendType" SG_ 253 EBV_Eingriff 0;
BA_ "GenSigSwitchedByIgnition" SG_ 253 EBV_Eingriff 0;
BA_ "GenSigSendType" SG_ 253 EDS_Eingriff 0;
BA_ "GenSigSwitchedByIgnition" SG_ 253 EDS_Eingriff 0;
BA_ "GenSigSendType" SG_ 253 ESC_Reku_Freigabe 0;
BA_ "GenSigSwitchedByIgnition" SG_ 253 ESC_Reku_Freigabe 0;
BA_ "GenSigSendType" SG_ 253 ESC_v_Signal_Qualifier_High_Low 0;
BA_ "GenSigStartValue" SG_ 253 ESC_v_Signal_Qualifier_High_Low 6;
BA_ "GenSigSwitchedByIgnition" SG_ 253 ESC_v_Signal_Qualifier_High_Low 0;
BA_ "Fehlerwert" SG_ 253 ESC_v_Signal_Qualifier_High_Low 7;
BA_ "GenSigSendType" SG_ 253 ESP_21_BZ 0;
BA_ "GenSigFuncType" SG_ 253 ESP_21_BZ 1;
BA_ "GenSigSwitchedByIgnition" SG_ 253 ESP_21_BZ 0;
BA_ "GenSigSendType" SG_ 253 ESP_21_CRC 0;
BA_ "GenSigFuncType" SG_ 253 ESP_21_CRC 2;
BA_ "GenSigSwitchedByIgnition" SG_ 253 ESP_21_CRC 0;
BA_ "GenSigSendType" SG_ 253 ESP_Anhaltevorgang_ACC_aktiv 0;
BA_ "GenSigSwitchedByIgnition" SG_ 253 ESP_Anhaltevorgang_ACC_aktiv 0;
BA_ "GenSigSendType" SG_ 253 ESP_ASP 0;
BA_ "GenSigSwitchedByIgnition" SG_ 253 ESP_ASP 0;
BA_ "GenSigSendType" SG_ 253 ESP_AWV3_Brems_aktiv 0;
BA_ "GenSigSwitchedByIgnition" SG_ 253 ESP_AWV3_Brems_aktiv 0;
BA_ "GenSigSendType" SG_ 253 ESP_Diagnose 0;
BA_ "GenSigSwitchedByIgnition" SG_ 253 ESP_Diagnose 0;
BA_ "GenSigSendType" SG_ 253 ESP_Eingriff 0;
BA_ "GenSigSwitchedByIgnition" SG_ 253 ESP_Eingriff 0;
BA_ "GenSigSendType" SG_ 253 ESP_Haltebestaetigung 0;
BA_ "GenSigSwitchedByIgnition" SG_ 253 ESP_Haltebestaetigung 0;
BA_ "GenSigSendType" SG_ 253 ESP_MKB_Abbruch_Geschw 0;
BA_ "GenSigSwitchedByIgnition" SG_ 253 ESP_MKB_Abbruch_Geschw 0;
BA_ "GenSigSendType" SG_ 253 ESP_PLA_Bremseingriff 0;
BA_ "GenSigSwitchedByIgnition" SG_ 253 ESP_PLA_Bremseingriff 0;
BA_ "GenSigSendType" SG_ 253 ESP_QBit_v_Signal 0;
BA_ "GenSigStartValue" SG_ 253 ESP_QBit_v_Signal 1;
BA_ "GenSigSwitchedByIgnition" SG_ 253 ESP_QBit_v_Signal 0;
BA_ "GenSigSendType" SG_ 253 ESP_Systemstatus 0;
BA_ "GenSigSwitchedByIgnition" SG_ 253 ESP_Systemstatus 0;
BA_ "GenSigSendType" SG_ 253 ESP_Tastung_passiv 0;
BA_ "GenSigSwitchedByIgnition" SG_ 253 ESP_Tastung_passiv 0;
BA_ "GenSigSendType" SG_ 253 ESP_v_Signal 0;
BA_ "GenSigStartValue" SG_ 253 ESP_v_Signal 65534;
BA_ "GenSigSwitchedByIgnition" SG_ 253 ESP_v_Signal 0;
BA_ "Fehlerwert" SG_ 253 ESP_v_Signal 65535;
BA_ "GenSigMissingSourceValue" SG_ 253 ESP_v_Signal 65534;
BA_ "GenSigSendType" SG_ 253 ESP_Vorsteuerung 0;
BA_ "GenSigSwitchedByIgnition" SG_ 253 ESP_Vorsteuerung 0;
BA_ "GenSigSendType" SG_ 253 MSR_Anf 0;
BA_ "GenSigSwitchedByIgnition" SG_ 253 MSR_Anf 0;
BA_ "GenSigSendType" SG_ 253 OBD_QBit_Schlechtweg 0;
BA_ "GenSigStartValue" SG_ 253 OBD_QBit_Schlechtweg 1;
BA_ "GenSigSwitchedByIgnition" SG_ 253 OBD_QBit_Schlechtweg 0;
BA_ "GenSigSendType" SG_ 253 OBD_Schlechtweg 0;
BA_ "GenSigSwitchedByIgnition" SG_ 253 OBD_Schlechtweg 0;
BA_ "GenSigSendType" SG_ 795 ABS_Lampe 0;
BA_ "GenSigStartValue" SG_ 795 ABS_Lampe 1;
BA_ "GenSigSwitchedByIgnition" SG_ 795 ABS_Lampe 0;
BA_ "GenSigSendType" SG_ 795 BK_Lampe_02 0;
BA_ "GenSigStartValue" SG_ 795 BK_Lampe_02 1;
BA_ "GenSigSwitchedByIgnition" SG_ 795 BK_Lampe_02 0;
BA_ "GenSigSendType" SG_ 795 ESP_24_BZ 0;
BA_ "GenSigFuncType" SG_ 795 ESP_24_BZ 1;
BA_ "GenSigSwitchedByIgnition" SG_ 795 ESP_24_BZ 0;
BA_ "GenSigSendType" SG_ 795 ESP_24_CRC 0;
BA_ "GenSigFuncType" SG_ 795 ESP_24_CRC 2;
BA_ "GenSigSwitchedByIgnition" SG_ 795 ESP_24_CRC 0;
BA_ "GenSigSendType" SG_ 795 ESP_BKV_Warnung 0;
BA_ "GenSigSwitchedByIgnition" SG_ 795 ESP_BKV_Warnung 0;
BA_ "GenSigSendType" SG_ 795 ESP_Fehlerstatus_Wegimp 0;
BA_ "GenSigSwitchedByIgnition" SG_ 795 ESP_Fehlerstatus_Wegimp 0;
BA_ "GenSigSendType" SG_ 795 ESP_HDC_FktLampe 0;
BA_ "GenSigSwitchedByIgnition" SG_ 795 ESP_HDC_FktLampe 0;
BA_ "GenSigSendType" SG_ 795 ESP_HDC_Regelgeschw 0;
BA_ "GenSigStartValue" SG_ 795 ESP_HDC_Regelgeschw 126;
BA_ "GenSigSwitchedByIgnition" SG_ 795 ESP_HDC_Regelgeschw 0;
BA_ "Fehlerwert" SG_ 795 ESP_HDC_Regelgeschw 127;
BA_ "GenSigSendType" SG_ 795 ESP_Lampe 0;
BA_ "GenSigSwitchedByIgnition" SG_ 795 ESP_Lampe 0;
BA_ "GenSigSendType" SG_ 795 ESP_m_Raddrehz 0;
BA_ "GenSigStartValue" SG_ 795 ESP_m_Raddrehz 32766;
BA_ "GenSigSwitchedByIgnition" SG_ 795 ESP_m_Raddrehz 0;
BA_ "Fehlerwert" SG_ 795 ESP_m_Raddrehz 32767;
BA_ "GenSigSendType" SG_ 795 ESP_Meldungen 0;
BA_ "GenSigSwitchedByIgnition" SG_ 795 ESP_Meldungen 0;
BA_ "GenSigSendType" SG_ 795 ESP_Off_Lampe 0;
BA_ "GenSigSwitchedByIgnition" SG_ 795 ESP_Off_Lampe 0;
BA_ "GenSigSendType" SG_ 795 ESP_QBit_Wegimp_VA 0;
BA_ "GenSigStartValue" SG_ 795 ESP_QBit_Wegimp_VA 1;
BA_ "GenSigSwitchedByIgnition" SG_ 795 ESP_QBit_Wegimp_VA 0;
BA_ "GenSigSendType" SG_ 795 ESP_Textanzeigen_03 0;
BA_ "GenSigSwitchedByIgnition" SG_ 795 ESP_Textanzeigen_03 0;
BA_ "GenSigSendType" SG_ 795 ESP_Wegimp_Ueberlauf 0;
BA_ "GenSigSwitchedByIgnition" SG_ 795 ESP_Wegimp_Ueberlauf 0;
BA_ "GenSigSendType" SG_ 795 ESP_Wegimp_VA 0;
BA_ "GenSigSwitchedByIgnition" SG_ 795 ESP_Wegimp_VA 0;
BA_ "GenSigSendType" SG_ 795 TC_Lampe 0;
BA_ "GenSigSwitchedByIgnition" SG_ 795 TC_Lampe 0;
BA_ "GenSigSendType" SG_ 2589283617 DBK_Fahrerwarnung 0;
BA_ "GenSigSwitchedByIgnition" SG_ 2589283617 DBK_Fahrerwarnung 0;
BA_ "GenSigSendType" SG_ 2589283617 EDS_Charisma_FahrPr 3;
BA_ "GenSigSwitchedByIgnition" SG_ 2589283617 EDS_Charisma_FahrPr 0;
BA_ "GenSigSendType" SG_ 2589283617 EDS_Charisma_Status 3;
BA_ "GenSigSwitchedByIgnition" SG_ 2589283617 EDS_Charisma_Status 0;
BA_ "GenSigSendType" SG_ 2589283617 ESC_Anf_KL 0;
BA_ "GenSigSwitchedByIgnition" SG_ 2589283617 ESC_Anf_KL 0;
BA_ "GenSigSendType" SG_ 2589283617 ESC_Anf_KV 0;
BA_ "GenSigSwitchedByIgnition" SG_ 2589283617 ESC_Anf_KV 0;
BA_ "GenSigSendType" SG_ 2589283617 ESC_FBA_Meldungen 3;
BA_ "GenSigSwitchedByIgnition" SG_ 2589283617 ESC_FBA_Meldungen 0;
BA_ "GenSigSendType" SG_ 2589283617 ESC_Lernfreigabe_Abrollumfang 3;
BA_ "GenSigSwitchedByIgnition" SG_ 2589283617 ESC_Lernfreigabe_Abrollumfang 0;
BA_ "GenSigSendType" SG_ 2589283617 ESC_MBK_Meldungen 3;
BA_ "GenSigSwitchedByIgnition" SG_ 2589283617 ESC_MBK_Meldungen 0;
BA_ "GenSigSendType" SG_ 2589283617 ESC_Texte_eBKV_Betaetigung 3;
BA_ "GenSigSwitchedByIgnition" SG_ 2589283617 ESC_Texte_eBKV_Betaetigung 0;
BA_ "GenSigSendType" SG_ 2589283617 ESP_30_BZ 0;
BA_ "GenSigFuncType" SG_ 2589283617 ESP_30_BZ 1;
BA_ "GenSigSwitchedByIgnition" SG_ 2589283617 ESP_30_BZ 0;
BA_ "GenSigSendType" SG_ 2589283617 ESP_30_CRC 0;
BA_ "GenSigFuncType" SG_ 2589283617 ESP_30_CRC 2;
BA_ "GenSigSwitchedByIgnition" SG_ 2589283617 ESP_30_CRC 0;
BA_ "GenSigSendType" SG_ 2589283617 ESP_Off_Anf_KBI 3;
BA_ "GenSigSwitchedByIgnition" SG_ 2589283617 ESP_Off_Anf_KBI 0;
BA_ "GenSigSendType" SG_ 2589283617 ESP_Status_Bremsentemp_Anz 3;
BA_ "GenSigSwitchedByIgnition" SG_ 2589283617 ESP_Status_Bremsentemp_Anz 0;
BA_ "Fehlerwert" SG_ 2589283617 ESP_Status_Bremsentemp_Anz 7;
BA_ "GenSigSendType" SG_ 2589283617 FBC_Fahrerwarnung 0;
BA_ "GenSigSwitchedByIgnition" SG_ 2589283617 FBC_Fahrerwarnung 0;
BA_ "GenSigSendType" SG_ 2589283617 HHC_Charisma_FahrPr 3;
BA_ "GenSigSwitchedByIgnition" SG_ 2589283617 HHC_Charisma_FahrPr 0;
BA_ "GenSigSendType" SG_ 2589283617 HHC_Charisma_Status 3;
BA_ "GenSigSwitchedByIgnition" SG_ 2589283617 HHC_Charisma_Status 0;
BA_ "GenSigSendType" SG_ 2589283617 RLE_Anzeigen 0;
BA_ "GenSigSwitchedByIgnition" SG_ 2589283617 RLE_Anzeigen 0;
BA_ "GenSigSendType" SG_ 2589283684 FoD_Transmission_Info 3;
BA_ "GenSigSwitchedByIgnition" SG_ 2589283684 FoD_Transmission_Info 0;
BA_ "GenSigSendType" SG_ 2589283684 GRA_FoD_Status 4;
BA_ "GenSigSwitchedByIgnition" SG_ 2589283684 GRA_FoD_Status 0;
BA_ "GenSigSendType" SG_ 2549875571 FoD_ZR_Req_Data 3;
BA_ "GenSigFuncType" SG_ 2549875571 FoD_ZR_Req_Data 9;
BA_ "GenSigSwitchedByIgnition" SG_ 2549875571 FoD_ZR_Req_Data 0;
BA_ "GenSigSendType" SG_ 2550006643 FoD_ZR_Resp_Data 3;
BA_ "GenSigFuncType" SG_ 2550006643 FoD_ZR_Resp_Data 9;
BA_ "GenSigSwitchedByIgnition" SG_ 2550006643 FoD_ZR_Resp_Data 0;
BA_ "GenSigSendType" SG_ 986 ABS_Bremsung 0;
BA_ "GenSigSwitchedByIgnition" SG_ 986 ABS_Bremsung 0;
BA_ "GenSigSendType" SG_ 986 ECD_Bremslicht 3;
BA_ "GenSigSwitchedByIgnition" SG_ 986 ECD_Bremslicht 0;
BA_ "GenSigSendType" SG_ 986 EPB_01_alt 0;
BA_ "GenSigStartValue" SG_ 986 EPB_01_alt 1;
BA_ "GenSigFuncType" SG_ 986 EPB_01_alt 5;
BA_ "GenSigSwitchedByIgnition" SG_ 986 EPB_01_alt 0;
BA_ "GenSigSendType" SG_ 986 EPB_Pedalweg_Kuppl 0;
BA_ "GenSigSwitchedByIgnition" SG_ 986 EPB_Pedalweg_Kuppl 0;
BA_ "Fehlerwert" SG_ 986 EPB_Pedalweg_Kuppl 255;
BA_ "GenSigSendType" SG_ 986 EPB_QBit_Pedalweg_Kuppl 0;
BA_ "GenSigStartValue" SG_ 986 EPB_QBit_Pedalweg_Kuppl 1;
BA_ "GenSigSwitchedByIgnition" SG_ 986 EPB_QBit_Pedalweg_Kuppl 0;
BA_ "GenSigSendType" SG_ 986 EPB_Status 0;
BA_ "GenSigSwitchedByIgnition" SG_ 986 EPB_Status 0;
BA_ "GenSigSendType" SG_ 986 ESP_05_alt 0;
BA_ "GenSigStartValue" SG_ 986 ESP_05_alt 1;
BA_ "GenSigFuncType" SG_ 986 ESP_05_alt 5;
BA_ "GenSigSwitchedByIgnition" SG_ 986 ESP_05_alt 0;
BA_ "GenSigSendType" SG_ 986 ESP_21_alt 0;
BA_ "GenSigStartValue" SG_ 986 ESP_21_alt 1;
BA_ "GenSigFuncType" SG_ 986 ESP_21_alt 5;
BA_ "GenSigSwitchedByIgnition" SG_ 986 ESP_21_alt 0;
BA_ "GenSigSendType" SG_ 986 ESP_Eingriff 0;
BA_ "GenSigSwitchedByIgnition" SG_ 986 ESP_Eingriff 0;
BA_ "GenSigSendType" SG_ 986 ESP_HDC_Standby 0;
BA_ "GenSigSendType" SG_ 986 ESP_MKB_Abbruch_Geschw 3;
BA_ "GenSigSwitchedByIgnition" SG_ 986 ESP_MKB_Abbruch_Geschw 0;
BA_ "GenSigSendType" SG_ 986 ESP_QBit_v_Signal 0;
BA_ "GenSigStartValue" SG_ 986 ESP_QBit_v_Signal 1;
BA_ "GenSigSwitchedByIgnition" SG_ 986 ESP_QBit_v_Signal 0;
BA_ "GenSigSendType" SG_ 986 ESP_v_Signal 0;
BA_ "GenSigStartValue" SG_ 986 ESP_v_Signal 65534;
BA_ "GenSigSwitchedByIgnition" SG_ 986 ESP_v_Signal 0;
BA_ "Fehlerwert" SG_ 986 ESP_v_Signal 65535;
BA_ "GenSigMissingSourceValue" SG_ 986 ESP_v_Signal 65534;
BA_ "GenSigSendType" SG_ 986 Kamera_FSH_aktiv 0;
BA_ "GenSigSendType" SG_ 986 Kamera_Status_alt 0;
BA_ "GenSigStartValue" SG_ 986 Kamera_Status_alt 1;
BA_ "GenSigFuncType" SG_ 986 Kamera_Status_alt 5;
BA_ "GenSigSwitchedByIgnition" SG_ 986 Kamera_Status_alt 0;
BA_ "GenSigSendType" SG_ 986 LWI_01_alt 0;
BA_ "GenSigStartValue" SG_ 986 LWI_01_alt 1;
BA_ "GenSigFuncType" SG_ 986 LWI_01_alt 5;
BA_ "GenSigSwitchedByIgnition" SG_ 986 LWI_01_alt 0;
BA_ "GenSigSendType" SG_ 986 LWI_Lenkradwinkel 0;
BA_ "GenSigStartValue" SG_ 986 LWI_Lenkradwinkel 8190;
BA_ "Fehlerwert" SG_ 986 LWI_Lenkradwinkel 8191;
BA_ "GenSigSendType" SG_ 986 LWI_QBit_Lenkradwinkel 0;
BA_ "GenSigStartValue" SG_ 986 LWI_QBit_Lenkradwinkel 1;
BA_ "GenSigSendType" SG_ 986 LWI_Sensorstatus 0;
BA_ "GenSigSendType" SG_ 986 LWI_VZ_Lenkradwinkel 0;
BA_ "GenSigSendType" SG_ 986 Parkhilfe_01_alt 0;
BA_ "GenSigStartValue" SG_ 986 Parkhilfe_01_alt 1;
BA_ "GenSigFuncType" SG_ 986 Parkhilfe_01_alt 5;
BA_ "GenSigSwitchedByIgnition" SG_ 986 Parkhilfe_01_alt 0;
BA_ "GenSigSendType" SG_ 986 PH_Anf_Audioabsenkung 0;
BA_ "GenSigSendType" SG_ 986 PH_Systemzustand 0;
BA_ "GenSigSendType" SG_ 986 PH_Taster 3;
BA_ "Fehlerwert" SG_ 986 PH_Taster 3;
BA_ "GenSigSendType" SG_ 986 PLA_Anf_Aufschaltung_RVC 3;
BA_ "GenSigSendType" SG_ 988 ACC_18_alt 0;
BA_ "GenSigStartValue" SG_ 988 ACC_18_alt 1;
BA_ "GenSigFuncType" SG_ 988 ACC_18_alt 5;
BA_ "GenSigSwitchedByIgnition" SG_ 988 ACC_18_alt 0;
BA_ "GenSigSendType" SG_ 988 ACC_Status_ACC 0;
BA_ "GenSigSendType" SG_ 988 Bel_DiETa_Mode2 3;
BA_ "GenSigSwitchedByIgnition" SG_ 988 Bel_DiETa_Mode2 0;
BA_ "Fehlerwert" SG_ 988 Bel_DiETa_Mode2 3;
BA_ "GenSigSendType" SG_ 988 EPB_Schalterposition 0;
BA_ "GenSigSwitchedByIgnition" SG_ 988 EPB_Schalterposition 0;
BA_ "Fehlerwert" SG_ 988 EPB_Schalterposition 3;
BA_ "GenSigSendType" SG_ 988 EPB_Status_02 0;
BA_ "GenSigStartValue" SG_ 988 EPB_Status_02 6;
BA_ "GenSigSwitchedByIgnition" SG_ 988 EPB_Status_02 0;
BA_ "GenSigSendType" SG_ 988 ESP_07_alt 0;
BA_ "GenSigStartValue" SG_ 988 ESP_07_alt 1;
BA_ "GenSigFuncType" SG_ 988 ESP_07_alt 5;
BA_ "GenSigSwitchedByIgnition" SG_ 988 ESP_07_alt 0;
BA_ "GenSigSendType" SG_ 988 ESP_50_alt 0;
BA_ "GenSigStartValue" SG_ 988 ESP_50_alt 1;
BA_ "GenSigFuncType" SG_ 988 ESP_50_alt 5;
BA_ "GenSigSwitchedByIgnition" SG_ 988 ESP_50_alt 0;
BA_ "GenSigSendType" SG_ 988 ESP_Rollenmodus_Deaktivieren 0;
BA_ "GenSigSwitchedByIgnition" SG_ 988 ESP_Rollenmodus_Deaktivieren 0;
BA_ "GenSigSendType" SG_ 988 GE_Fahrstufe 3;
BA_ "GenSigStartValue" SG_ 988 GE_Fahrstufe 1;
BA_ "GenSigSwitchedByIgnition" SG_ 988 GE_Fahrstufe 0;
BA_ "Fehlerwert" SG_ 988 GE_Fahrstufe 15;
BA_ "GenSigSendType" SG_ 988 GE_Freilauf_Status 0;
BA_ "GenSigSwitchedByIgnition" SG_ 988 GE_Freilauf_Status 0;
BA_ "Fehlerwert" SG_ 988 GE_Freilauf_Status 7;
BA_ "GenSigSendType" SG_ 988 GE_LaunchControl 3;
BA_ "GenSigSwitchedByIgnition" SG_ 988 GE_LaunchControl 0;
BA_ "GenSigSendType" SG_ 988 GE_Notlauf 3;
BA_ "GenSigSwitchedByIgnition" SG_ 988 GE_Notlauf 0;
BA_ "GenSigSendType" SG_ 988 GE_Sperr_Info_WFS 3;
BA_ "GenSigSwitchedByIgnition" SG_ 988 GE_Sperr_Info_WFS 0;
BA_ "GenSigSendType" SG_ 988 GE_Ursache_Fahrstufe_N 0;
BA_ "GenSigSwitchedByIgnition" SG_ 988 GE_Ursache_Fahrstufe_N 0;
BA_ "GenSigSendType" SG_ 988 GE_Veto_Rollfaehigkeit 0;
BA_ "GenSigSwitchedByIgnition" SG_ 988 GE_Veto_Rollfaehigkeit 0;
BA_ "GenSigSendType" SG_ 988 Getriebe_11_alt 0;
BA_ "GenSigStartValue" SG_ 988 Getriebe_11_alt 1;
BA_ "GenSigFuncType" SG_ 988 Getriebe_11_alt 5;
BA_ "GenSigSwitchedByIgnition" SG_ 988 Getriebe_11_alt 0;
BA_ "GenSigSendType" SG_ 988 Getriebe_13_alt 0;
BA_ "GenSigStartValue" SG_ 988 Getriebe_13_alt 1;
BA_ "GenSigFuncType" SG_ 988 Getriebe_13_alt 5;
BA_ "GenSigSwitchedByIgnition" SG_ 988 Getriebe_13_alt 0;
BA_ "GenSigSendType" SG_ 988 Getriebe_14_alt 0;
BA_ "GenSigStartValue" SG_ 988 Getriebe_14_alt 1;
BA_ "GenSigFuncType" SG_ 988 Getriebe_14_alt 5;
BA_ "GenSigSwitchedByIgnition" SG_ 988 Getriebe_14_alt 0;
BA_ "GenSigSendType" SG_ 988 Getriebe_17_alt 0;
BA_ "GenSigStartValue" SG_ 988 Getriebe_17_alt 1;
BA_ "GenSigFuncType" SG_ 988 Getriebe_17_alt 5;
BA_ "GenSigSwitchedByIgnition" SG_ 988 Getriebe_17_alt 0;
BA_ "GenSigSendType" SG_ 988 MKE_Stufe 0;
BA_ "GenSigSwitchedByIgnition" SG_ 988 MKE_Stufe 0;
BA_ "GenSigSendType" SG_ 988 MKE_Texte 0;
BA_ "GenSigSwitchedByIgnition" SG_ 988 MKE_Texte 0;
BA_ "GenSigSendType" SG_ 988 MO_Drehzahl_01 0;
BA_ "GenSigSwitchedByIgnition" SG_ 988 MO_Drehzahl_01 0;
BA_ "GenSigSendType" SG_ 988 MO_QBit_Drehzahl_01 0;
BA_ "GenSigStartValue" SG_ 988 MO_QBit_Drehzahl_01 1;
BA_ "GenSigSwitchedByIgnition" SG_ 988 MO_QBit_Drehzahl_01 0;
BA_ "GenSigSendType" SG_ 988 Motor_12_alt 0;
BA_ "GenSigStartValue" SG_ 988 Motor_12_alt 1;
BA_ "GenSigFuncType" SG_ 988 Motor_12_alt 5;
BA_ "GenSigSwitchedByIgnition" SG_ 988 Motor_12_alt 0;
BA_ "GenSigSendType" SG_ 988 TSK_06_alt 0;
BA_ "GenSigStartValue" SG_ 988 TSK_06_alt 1;
BA_ "GenSigSwitchedByIgnition" SG_ 988 TSK_06_alt 0;
BA_ "GenSigSendType" SG_ 988 TSK_Hauptschalter_GRA_ACC 0;
BA_ "GenSigSwitchedByIgnition" SG_ 988 TSK_Hauptschalter_GRA_ACC 0;
BA_ "Fehlerwert" SG_ 988 TSK_Hauptschalter_GRA_ACC 3;
BA_ "GenSigSendType" SG_ 988 TSK_Limiter_ausgewaehlt 0;
BA_ "GenSigSwitchedByIgnition" SG_ 988 TSK_Limiter_ausgewaehlt 0;
BA_ "GenSigSendType" SG_ 988 TSK_Status 0;
BA_ "GenSigStartValue" SG_ 988 TSK_Status 1;
BA_ "GenSigSwitchedByIgnition" SG_ 988 TSK_Status 0;
BA_ "GenSigSendType" SG_ 1002 AWV_03_alt 0;
BA_ "GenSigStartValue" SG_ 1002 AWV_03_alt 1;
BA_ "GenSigFuncType" SG_ 1002 AWV_03_alt 5;
BA_ "GenSigSwitchedByIgnition" SG_ 1002 AWV_03_alt 0;
BA_ "GenSigSendType" SG_ 1002 AWV_Verz_Anf 3;
BA_ "GenSigStartValue" SG_ 1002 AWV_Verz_Anf 1023;
BA_ "GenSigSendType" SG_ 1002 AWV_Verz_Freigabe 3;
BA_ "GenSigSendType" SG_ 1002 AWV_Zielobjekttyp 3;
BA_ "GenSigStartValue" SG_ 1002 AWV_Zielobjekttyp 15;
BA_ "GenSigSendType" SG_ 1002 Bel_DiETa_Mode 3;
BA_ "GenSigSwitchedByIgnition" SG_ 1002 Bel_DiETa_Mode 0;
BA_ "Fehlerwert" SG_ 1002 Bel_DiETa_Mode 3;
BA_ "GenSigSendType" SG_ 1002 EBKV_03_alt 0;
BA_ "GenSigStartValue" SG_ 1002 EBKV_03_alt 1;
BA_ "GenSigFuncType" SG_ 1002 EBKV_03_alt 5;
BA_ "GenSigSwitchedByIgnition" SG_ 1002 EBKV_03_alt 0;
BA_ "GenSigSendType" SG_ 1002 EBKV_Fahrer_bremst 3;
BA_ "GenSigSwitchedByIgnition" SG_ 1002 EBKV_Fahrer_bremst 0;
BA_ "GenSigSendType" SG_ 1002 ESP_05_alt 0;
BA_ "GenSigStartValue" SG_ 1002 ESP_05_alt 1;
BA_ "GenSigFuncType" SG_ 1002 ESP_05_alt 5;
BA_ "GenSigSwitchedByIgnition" SG_ 1002 ESP_05_alt 0;
BA_ "GenSigSendType" SG_ 1002 ESP_Bremsdruck 0;
BA_ "GenSigStartValue" SG_ 1002 ESP_Bremsdruck 100;
BA_ "GenSigSwitchedByIgnition" SG_ 1002 ESP_Bremsdruck 0;
BA_ "Fehlerwert" SG_ 1002 ESP_Bremsdruck 1023;
BA_ "GenSigSendType" SG_ 1002 GE_Sumpftemperatur 0;
BA_ "GenSigSwitchedByIgnition" SG_ 1002 GE_Sumpftemperatur 0;
BA_ "Fehlerwert" SG_ 1002 GE_Sumpftemperatur 255;
BA_ "GenSigSendType" SG_ 1002 Getriebe_14_alt 0;
BA_ "GenSigStartValue" SG_ 1002 Getriebe_14_alt 1;
BA_ "GenSigFuncType" SG_ 1002 Getriebe_14_alt 5;
BA_ "GenSigSwitchedByIgnition" SG_ 1002 Getriebe_14_alt 0;
BA_ "GenSigSendType" SG_ 1002 MO_Fahrpedalrohwert_01 0;
BA_ "GenSigSwitchedByIgnition" SG_ 1002 MO_Fahrpedalrohwert_01 0;
BA_ "Fehlerwert" SG_ 1002 MO_Fahrpedalrohwert_01 255;
BA_ "GenSigSendType" SG_ 1002 MO_Mom_Ist_Summe 0;
BA_ "GenSigStartValue" SG_ 1002 MO_Mom_Ist_Summe 1022;
BA_ "GenSigSwitchedByIgnition" SG_ 1002 MO_Mom_Ist_Summe 0;
BA_ "GenSigSendType" SG_ 1002 Motor_11_alt 0;
BA_ "GenSigStartValue" SG_ 1002 Motor_11_alt 1;
BA_ "GenSigFuncType" SG_ 1002 Motor_11_alt 5;
BA_ "GenSigSwitchedByIgnition" SG_ 1002 Motor_11_alt 0;
BA_ "GenSigSendType" SG_ 1002 Motor_20_alt 0;
BA_ "GenSigStartValue" SG_ 1002 Motor_20_alt 1;
BA_ "GenSigFuncType" SG_ 1002 Motor_20_alt 5;
BA_ "GenSigSwitchedByIgnition" SG_ 1002 Motor_20_alt 0;
BA_ "GenSigSendType" SG_ 1002 PaCo_DiETa_LED 3;
BA_ "GenSigSwitchedByIgnition" SG_ 1002 PaCo_DiETa_LED 0;
BA_ "GenSigSendType" SG_ 1002 RTM_Warnstatus 3;
BA_ "GenSigSwitchedByIgnition" SG_ 1002 RTM_Warnstatus 0;
BA_ "GenSigSendType" SG_ 1004 ACC_02_alt 0;
BA_ "GenSigStartValue" SG_ 1004 ACC_02_alt 1;
BA_ "GenSigFuncType" SG_ 1004 ACC_02_alt 5;
BA_ "GenSigSwitchedByIgnition" SG_ 1004 ACC_02_alt 0;
BA_ "GenSigSendType" SG_ 1004 ACC_Status_Anzeige 3;
BA_ "GenSigSendType" SG_ 1004 BCM_01_alt 0;
BA_ "GenSigStartValue" SG_ 1004 BCM_01_alt 1;
BA_ "GenSigFuncType" SG_ 1004 BCM_01_alt 5;
BA_ "GenSigSwitchedByIgnition" SG_ 1004 BCM_01_alt 0;
BA_ "GenSigSendType" SG_ 1004 BCM_Offroad_Taste 3;
BA_ "GenSigSendType" SG_ 1004 BCM_Waschwasser_Sensor 3;
BA_ "GenSigSwitchedByIgnition" SG_ 1004 BCM_Waschwasser_Sensor 0;
BA_ "GenSigSendType" SG_ 1004 EM1_01_alt 0;
BA_ "GenSigStartValue" SG_ 1004 EM1_01_alt 1;
BA_ "GenSigFuncType" SG_ 1004 EM1_01_alt 5;
BA_ "GenSigSendType" SG_ 1004 EM1_Status_DrzEingriff 3;
BA_ "Fehlerwert" SG_ 1004 EM1_Status_DrzEingriff 3;
BA_ "GenSigSendType" SG_ 1004 EM2_01_alt 0;
BA_ "GenSigStartValue" SG_ 1004 EM2_01_alt 1;
BA_ "GenSigFuncType" SG_ 1004 EM2_01_alt 5;
BA_ "GenSigSendType" SG_ 1004 EM2_Status_DrzEingriff 3;
BA_ "Fehlerwert" SG_ 1004 EM2_Status_DrzEingriff 3;
BA_ "GenSigSendType" SG_ 1004 GE_Status_Kraftschluss 3;
BA_ "GenSigSwitchedByIgnition" SG_ 1004 GE_Status_Kraftschluss 0;
BA_ "GenSigSendType" SG_ 1004 Getriebe_50_alt 0;
BA_ "GenSigFuncType" SG_ 1004 Getriebe_50_alt 5;
BA_ "GenSigSwitchedByIgnition" SG_ 1004 Getriebe_50_alt 0;
BA_ "GenSigSendType" SG_ 1004 HC_Uss_Anforderung 3;
BA_ "GenSigSendType" SG_ 1004 HD_Endstellung_oben 3;
BA_ "GenSigSendType" SG_ 1004 HD_Endstellung_unten 3;
BA_ "GenSigSendType" SG_ 1004 HD_Position 3;
BA_ "GenSigSendType" SG_ 1004 HDSG_01_alt 0;
BA_ "GenSigStartValue" SG_ 1004 HDSG_01_alt 1;
BA_ "GenSigFuncType" SG_ 1004 HDSG_01_alt 5;
BA_ "GenSigSendType" SG_ 1004 KL_Vorwarn_Komp_ein 3;
BA_ "GenSigSendType" SG_ 1004 Klima_11_alt 0;
BA_ "GenSigStartValue" SG_ 1004 Klima_11_alt 1;
BA_ "GenSigFuncType" SG_ 1004 Klima_11_alt 5;
BA_ "GenSigSendType" SG_ 1004 LDW_02_alt 0;
BA_ "GenSigStartValue" SG_ 1004 LDW_02_alt 1;
BA_ "GenSigFuncType" SG_ 1004 LDW_02_alt 5;
BA_ "GenSigSwitchedByIgnition" SG_ 1004 LDW_02_alt 0;
BA_ "GenSigSendType" SG_ 1004 LIN_2_alt 0;
BA_ "GenSigStartValue" SG_ 1004 LIN_2_alt 1;
BA_ "GenSigFuncType" SG_ 1004 LIN_2_alt 5;
BA_ "GenSigSwitchedByIgnition" SG_ 1004 LIN_2_alt 0;
BA_ "GenSigSendType" SG_ 1004 MFL_Touch_Event 3;
BA_ "GenSigSwitchedByIgnition" SG_ 1004 MFL_Touch_Event 0;
BA_ "Fehlerwert" SG_ 1004 MFL_Touch_Event 15;
BA_ "GenSigSendType" SG_ 1004 MO_NGS_Position 3;
BA_ "GenSigSendType" SG_ 1004 MO_NGS_Status 3;
BA_ "Fehlerwert" SG_ 1004 MO_NGS_Status 3;
BA_ "GenSigSendType" SG_ 1004 Motor_17_alt 0;
BA_ "GenSigStartValue" SG_ 1004 Motor_17_alt 1;
BA_ "GenSigFuncType" SG_ 1004 Motor_17_alt 5;
BA_ "GenSigSendType" SG_ 879 GNSS_Breite_Ortung 0;
BA_ "GenSigStartValue" SG_ 879 GNSS_Breite_Ortung 134217726;
BA_ "GenSigSwitchedByIgnition" SG_ 879 GNSS_Breite_Ortung 0;
BA_ "Fehlerwert" SG_ 879 GNSS_Breite_Ortung 134217727;
BA_ "GenSigSendType" SG_ 879 GNSS_Fehlerzustand 0;
BA_ "GenSigSwitchedByIgnition" SG_ 879 GNSS_Fehlerzustand 0;
BA_ "GenSigSendType" SG_ 879 GNSS_Laenge_Ortung 0;
BA_ "GenSigStartValue" SG_ 879 GNSS_Laenge_Ortung 268435454;
BA_ "GenSigSwitchedByIgnition" SG_ 879 GNSS_Laenge_Ortung 0;
BA_ "Fehlerwert" SG_ 879 GNSS_Laenge_Ortung 268435455;
BA_ "GenSigSendType" SG_ 879 GNSS_Nachrichtenpaket_ID1 0;
BA_ "GenSigSwitchedByIgnition" SG_ 879 GNSS_Nachrichtenpaket_ID1 0;
BA_ "GenSigSendType" SG_ 879 GNSS_Ortung_FIX_Typ 0;
BA_ "GenSigSwitchedByIgnition" SG_ 879 GNSS_Ortung_FIX_Typ 0;
BA_ "GenSigSendType" SG_ 879 GNSS_Richtung_Breite_Ortung 0;
BA_ "GenSigStartValue" SG_ 879 GNSS_Richtung_Breite_Ortung 1;
BA_ "GenSigSwitchedByIgnition" SG_ 879 GNSS_Richtung_Breite_Ortung 0;
BA_ "GenSigSendType" SG_ 879 GNSS_Richtung_Laenge_Ortung 0;
BA_ "GenSigStartValue" SG_ 879 GNSS_Richtung_Laenge_Ortung 1;
BA_ "GenSigSwitchedByIgnition" SG_ 879 GNSS_Richtung_Laenge_Ortung 0;
BA_ "GenSigSendType" SG_ 884 GNSS_Nachrichtenpaket_ID2 0;
BA_ "GenSigSwitchedByIgnition" SG_ 884 GNSS_Nachrichtenpaket_ID2 0;
BA_ "GenSigSendType" SG_ 884 GNSS_Ortung_2D_Geschw_ue_Grund 0;
BA_ "GenSigStartValue" SG_ 884 GNSS_Ortung_2D_Geschw_ue_Grund 510;
BA_ "GenSigSwitchedByIgnition" SG_ 884 GNSS_Ortung_2D_Geschw_ue_Grund 0;
BA_ "Fehlerwert" SG_ 884 GNSS_Ortung_2D_Geschw_ue_Grund 511;
BA_ "GenSigSendType" SG_ 884 GNSS_Ortung_Ausrichtung 0;
BA_ "GenSigStartValue" SG_ 884 GNSS_Ortung_Ausrichtung 4094;
BA_ "GenSigSwitchedByIgnition" SG_ 884 GNSS_Ortung_Ausrichtung 0;
BA_ "Fehlerwert" SG_ 884 GNSS_Ortung_Ausrichtung 4095;
BA_ "GenSigSendType" SG_ 884 GNSS_Ortung_Latenz 0;
BA_ "GenSigStartValue" SG_ 884 GNSS_Ortung_Latenz 1022;
BA_ "GenSigSwitchedByIgnition" SG_ 884 GNSS_Ortung_Latenz 0;
BA_ "Fehlerwert" SG_ 884 GNSS_Ortung_Latenz 1023;
BA_ "GenSigSendType" SG_ 884 GNSS_Ortung_Noerdliche_Geschw 0;
BA_ "GenSigStartValue" SG_ 884 GNSS_Ortung_Noerdliche_Geschw 1022;
BA_ "GenSigSwitchedByIgnition" SG_ 884 GNSS_Ortung_Noerdliche_Geschw 0;
BA_ "Fehlerwert" SG_ 884 GNSS_Ortung_Noerdliche_Geschw 1023;
BA_ "GenSigSendType" SG_ 884 GNSS_Ortung_Oestliche_Geschw 0;
BA_ "GenSigStartValue" SG_ 884 GNSS_Ortung_Oestliche_Geschw 1022;
BA_ "GenSigSwitchedByIgnition" SG_ 884 GNSS_Ortung_Oestliche_Geschw 0;
BA_ "Fehlerwert" SG_ 884 GNSS_Ortung_Oestliche_Geschw 1023;
BA_ "GenSigSendType" SG_ 884 GNSS_Ortung_Vertikale_Geschw 0;
BA_ "GenSigStartValue" SG_ 884 GNSS_Ortung_Vertikale_Geschw 1022;
BA_ "GenSigSwitchedByIgnition" SG_ 884 GNSS_Ortung_Vertikale_Geschw 0;
BA_ "Fehlerwert" SG_ 884 GNSS_Ortung_Vertikale_Geschw 1023;
BA_REL_ "GenSigTimeoutTime" BU_SG_REL_ BedienDisp_mi SG_ 1520 DI_KL_58xd 2000;
BA_REL_ "GenSigTimeoutTime" BU_SG_REL_ BedienDisp_mi SG_ 1520 DI_KL_58xt 2000;
BA_REL_ "GenSigTimeoutTime" BU_SG_REL_ BedienDisp_mi SG_ 1603 KBI_Einheit_Sprache 5000;
BA_REL_ "GenSigTimeoutTime" BU_SG_REL_ BedienDisp_mi SG_ 253 ESP_v_Signal 500;
BA_REL_ "GenSigTimeoutTime" BU_SG_REL_ BedienDisp_vo_mi SG_ 1520 DI_KL_58xd 2000;
BA_REL_ "GenSigTimeoutTime" BU_SG_REL_ BedienDisp_vo_mi SG_ 1520 DI_KL_58xs 2000;
BA_REL_ "GenSigTimeoutTime" BU_SG_REL_ BedienDisp_vo_mi SG_ 1520 DI_Display_Nachtdesign 2000;
BA_REL_ "GenSigTimeoutTime" BU_SG_REL_ BedienDisp_vo_mi SG_ 1520 DI_KL_58xt 2000;
BA_REL_ "GenSigTimeoutTime" BU_SG_REL_ BedienDisp_vo_mi SG_ 1603 KBI_Einheit_Sprache 5000;
BA_REL_ "GenSigTimeoutTime" BU_SG_REL_ BedienDisp_vo_mi SG_ 253 ESP_v_Signal 500;
BA_REL_ "GenSigTimeoutTime" BU_SG_REL_ CDI SG_ 1520 DI_KL_58xd 2000;
BA_REL_ "GenSigTimeoutTime" BU_SG_REL_ CDI SG_ 1520 DI_KL_58xs 2000;
BA_REL_ "GenSigTimeoutTime" BU_SG_REL_ CDI SG_ 1520 DI_Display_Nachtdesign 2000;
BA_REL_ "GenSigTimeoutTime" BU_SG_REL_ CDI SG_ 1520 DI_KL_58xt 2000;
BA_REL_ "GenSigTimeoutTime" BU_SG_REL_ CDI SG_ 988 GE_Fahrstufe 500;
BA_REL_ "GenSigTimeoutTime" BU_SG_REL_ ConMod_CD SG_ 496 EA_eCall_Anf 5000;
BA_REL_ "GenSigTimeoutTime" BU_SG_REL_ ConMod_CD SG_ 1603 KBI_Einheit_Sprache 5000;
BA_REL_ "GenSigTimeoutTime" BU_SG_REL_ ConMod_CD SG_ 1002 AWV_03_alt 2000;
BA_REL_ "GenSigTimeoutTime" BU_SG_REL_ ConMod_CD SG_ 1002 AWV_Zielobjekttyp 2000;
BA_REL_ "GenSigTimeoutTime" BU_SG_REL_ DashCAM SG_ 257 ESP_QBit_Laengsbeschl 500;
BA_REL_ "GenSigTimeoutTime" BU_SG_REL_ DashCAM SG_ 257 ESP_QBit_Querb 500;
BA_REL_ "GenSigTimeoutTime" BU_SG_REL_ DashCAM SG_ 257 ESP_Laengsbeschl 500;
BA_REL_ "GenSigTimeoutTime" BU_SG_REL_ DashCAM SG_ 262 ESP_QBit_Bremsdruck 500;
BA_REL_ "GenSigTimeoutTime" BU_SG_REL_ DashCAM SG_ 262 ESP_QBit_Fahrer_bremst 500;
BA_REL_ "GenSigTimeoutTime" BU_SG_REL_ DashCAM SG_ 262 ESP_Bremsdruck 500;
BA_REL_ "GenSigTimeoutTime" BU_SG_REL_ DashCAM SG_ 262 ESP_Fahrer_bremst 500;
BA_REL_ "GenSigTimeoutTime" BU_SG_REL_ DashCAM SG_ 253 ESP_Eingriff 500;
BA_REL_ "GenSigTimeoutTime" BU_SG_REL_ Gateway_Max SG_ 1142 DU_State 5000;
BA_REL_ "GenSigTimeoutTime" BU_SG_REL_ Gateway_Max SG_ 1142 DU_Temp_Fehler 5000;
BA_REL_ "GenSigTimeoutTime" BU_SG_REL_ Gateway_Max SG_ 1142 DU_KL30_Uebersp_Fehler 5000;
BA_REL_ "GenSigTimeoutTime" BU_SG_REL_ Gateway_Max SG_ 1142 DU_KL30_Untersp_Fehler 5000;
BA_REL_ "GenSigTimeoutTime" BU_SG_REL_ Gateway_Max SG_ 1142 DU_DispDerating 5000;
BA_REL_ "GenSigTimeoutTime" BU_SG_REL_ Gateway_Max SG_ 1142 DU_TempSens 5000;
BA_REL_ "GenSigTimeoutTime" BU_SG_REL_ Gateway_Max SG_ 1143 DU_HintGrdBelKurzschl 5000;
BA_REL_ "GenSigTimeoutTime" BU_SG_REL_ Gateway_Max SG_ 1143 DU_HintGrdBelUnterbr 5000;
BA_REL_ "GenSigTimeoutTime" BU_SG_REL_ Gateway_Max SG_ 1143 DU1_SW_inkonsistent 5000;
BA_REL_ "GenSigTimeoutTime" BU_SG_REL_ Gateway_Max SG_ 1143 LVDS_Status 5000;
BA_REL_ "GenSigTimeoutTime" BU_SG_REL_ Gateway_Max SG_ 1143 DU1_Touch_Fehlerstatus 5000;
BA_REL_ "GenSigTimeoutTime" BU_SG_REL_ Gateway_Max SG_ 1143 DU1_Haptik_Fehlerstatus 5000;
BA_REL_ "GenSigTimeoutTime" BU_SG_REL_ Gateway_Max SG_ 561 DU1_Fehlerstatus 2000;
BA_REL_ "GenSigTimeoutTime" BU_SG_REL_ Gateway_Max SG_ 2527679886 Drehschalter_Aktive_Ebene 5000;
BA_REL_ "GenSigTimeoutTime" BU_SG_REL_ Gateway_Max SG_ 2527679886 Drehschalter_defekt 5000;
BA_REL_ "GenSigTimeoutTime" BU_SG_REL_ Gateway_Max SG_ 2527679886 Drehschalter_Taster 5000;
BA_REL_ "GenSigTimeoutTime" BU_SG_REL_ Gateway_Max SG_ 2527679886 Drehschalter_Touch 5000;
BA_REL_ "GenSigTimeoutTime" BU_SG_REL_ Gateway_Max SG_ 2527679886 Drehschalter_Ist_Profil 5000;
BA_REL_ "GenSigTimeoutTime" BU_SG_REL_ Gateway_Max SG_ 879 GNSS_Breite_Ortung 5000;
BA_REL_ "GenSigTimeoutTime" BU_SG_REL_ Gateway_Max SG_ 879 GNSS_Richtung_Breite_Ortung 5000;
BA_REL_ "GenSigTimeoutTime" BU_SG_REL_ Gateway_Max SG_ 879 GNSS_Laenge_Ortung 5000;
BA_REL_ "GenSigTimeoutTime" BU_SG_REL_ Gateway_Max SG_ 879 GNSS_Richtung_Laenge_Ortung 5000;
BA_REL_ "GenSigTimeoutTime" BU_SG_REL_ Gateway_Max SG_ 879 GNSS_Ortung_FIX_Typ 5000;
BA_REL_ "GenSigTimeoutTime" BU_SG_REL_ ICC_IO_Node SG_ 253 ESP_v_Signal 500;
BA_REL_ "GenSigTimeoutTime" BU_SG_REL_ ICC_IO_Node SG_ 253 ESP_QBit_v_Signal 500;
BA_REL_ "GenSigTimeoutTime" BU_SG_REL_ ICC_IO_Node SG_ 988 Motor_12_alt 500;
BA_REL_ "GenSigTimeoutTime" BU_SG_REL_ ICC_IO_Node SG_ 988 MO_Drehzahl_01 500;
BA_REL_ "GenSigTimeoutTime" BU_SG_REL_ ICC_IO_Node SG_ 1004 LIN_2_alt 2000;
BA_REL_ "GenSigTimeoutTime" BU_SG_REL_ ICC_IO_Node SG_ 1004 MFL_Touch_Event 2000;
BA_REL_ "GenSigTimeoutTime" BU_SG_REL_ LSH SG_ 253 ESP_21_CRC 500;
BA_REL_ "GenSigTimeoutTime" BU_SG_REL_ LSH SG_ 253 ESP_21_BZ 500;
BA_REL_ "GenSigTimeoutTime" BU_SG_REL_ LSH SG_ 253 ESP_v_Signal 500;
BA_REL_ "GenSigTimeoutTime" BU_SG_REL_ LSH SG_ 253 ESP_QBit_v_Signal 500;
BA_REL_ "GenSigTimeoutTime" BU_SG_REL_ LSH SG_ 988 Motor_12_alt 500;
BA_REL_ "GenSigTimeoutTime" BU_SG_REL_ LSH SG_ 988 MO_Drehzahl_01 500;
BA_REL_ "GenSigTimeoutTime" BU_SG_REL_ OCU SG_ 1520 DI_KL_58xd 2000;
BA_REL_ "GenSigTimeoutTime" BU_SG_REL_ OCU SG_ 1520 DI_KL_58xs 2000;
BA_REL_ "GenSigTimeoutTime" BU_SG_REL_ OCU SG_ 1520 DI_KL_58xt 2000;
BA_REL_ "GenSigTimeoutTime" BU_SG_REL_ OCU SG_ 1520 DI_Fotosensor 2000;
BA_REL_ "GenSigTimeoutTime" BU_SG_REL_ OCU SG_ 1603 KBI_Einheit_Verbrauch 5000;
BA_REL_ "GenSigTimeoutTime" BU_SG_REL_ OCU SG_ 1603 KBI_Einheit_Sprache 5000;
BA_REL_ "GenSigTimeoutTime" BU_SG_REL_ OCU SG_ 257 ESP_QBit_Gierrate 500;
BA_REL_ "GenSigTimeoutTime" BU_SG_REL_ OCU SG_ 257 ESP_QBit_Laengsbeschl 500;
BA_REL_ "GenSigTimeoutTime" BU_SG_REL_ OCU SG_ 257 ESP_QBit_Querb 500;
BA_REL_ "GenSigTimeoutTime" BU_SG_REL_ OCU SG_ 257 ESP_Querbeschleunigung 500;
BA_REL_ "GenSigTimeoutTime" BU_SG_REL_ OCU SG_ 257 ESP_Laengsbeschl 500;
BA_REL_ "GenSigTimeoutTime" BU_SG_REL_ OCU SG_ 257 ESP_Gierrate 500;
BA_REL_ "GenSigTimeoutTime" BU_SG_REL_ OCU SG_ 257 ESP_VZ_Gierrate 500;
BA_REL_ "GenSigTimeoutTime" BU_SG_REL_ OCU SG_ 257 ESP_Notbremsanzeige 500;
BA_REL_ "GenSigTimeoutTime" BU_SG_REL_ OCU SG_ 262 ESP_QBit_Bremsdruck 500;
BA_REL_ "GenSigTimeoutTime" BU_SG_REL_ OCU SG_ 262 ESP_QBit_Fahrer_bremst 500;
BA_REL_ "GenSigTimeoutTime" BU_SG_REL_ OCU SG_ 262 ESP_Bremsdruck 500;
BA_REL_ "GenSigTimeoutTime" BU_SG_REL_ OCU SG_ 262 ESP_Fahrer_bremst 500;
BA_REL_ "GenSigTimeoutTime" BU_SG_REL_ OCU SG_ 262 ESP_Status_Bremsentemp 500;
BA_REL_ "GenSigTimeoutTime" BU_SG_REL_ OCU SG_ 262 ESP_HDC_Standby 500;
BA_REL_ "GenSigTimeoutTime" BU_SG_REL_ OCU SG_ 262 ECD_Bremslicht 500;
BA_REL_ "GenSigTimeoutTime" BU_SG_REL_ OCU SG_ 262 ESP_Status_Bremsdruck 500;
BA_REL_ "GenSigTimeoutTime" BU_SG_REL_ OCU SG_ 278 ESP_QBit_Wegimpuls_VL 2000;
BA_REL_ "GenSigTimeoutTime" BU_SG_REL_ OCU SG_ 278 ESP_QBit_Wegimpuls_VR 2000;
BA_REL_ "GenSigTimeoutTime" BU_SG_REL_ OCU SG_ 278 ESP_QBit_Wegimpuls_HL 2000;
BA_REL_ "GenSigTimeoutTime" BU_SG_REL_ OCU SG_ 278 ESP_QBit_Wegimpuls_HR 2000;
BA_REL_ "GenSigTimeoutTime" BU_SG_REL_ OCU SG_ 278 ESP_Wegimpuls_VL 2000;
BA_REL_ "GenSigTimeoutTime" BU_SG_REL_ OCU SG_ 278 ESP_Wegimpuls_VR 2000;
BA_REL_ "GenSigTimeoutTime" BU_SG_REL_ OCU SG_ 278 ESP_Wegimpuls_HL 2000;
BA_REL_ "GenSigTimeoutTime" BU_SG_REL_ OCU SG_ 278 ESP_Wegimpuls_HR 2000;
BA_REL_ "GenSigTimeoutTime" BU_SG_REL_ OCU SG_ 278 ESP_VL_Fahrtrichtung 2000;
BA_REL_ "GenSigTimeoutTime" BU_SG_REL_ OCU SG_ 278 ESP_VR_Fahrtrichtung 2000;
BA_REL_ "GenSigTimeoutTime" BU_SG_REL_ OCU SG_ 278 ESP_HL_Fahrtrichtung 2000;
BA_REL_ "GenSigTimeoutTime" BU_SG_REL_ OCU SG_ 278 ESP_HR_Fahrtrichtung 2000;
BA_REL_ "GenSigTimeoutTime" BU_SG_REL_ OCU SG_ 1629 ESP_Zaehnezahl 5000;
BA_REL_ "GenSigTimeoutTime" BU_SG_REL_ OCU SG_ 1629 ESP_Charisma_FahrPr 5000;
BA_REL_ "GenSigTimeoutTime" BU_SG_REL_ OCU SG_ 1629 BR_QBit_Reifenumfang 5000;
BA_REL_ "GenSigTimeoutTime" BU_SG_REL_ OCU SG_ 1629 BR_Reifenumfang 5000;
BA_REL_ "GenSigTimeoutTime" BU_SG_REL_ OCU SG_ 253 BR_Eingriffsmoment 500;
BA_REL_ "GenSigTimeoutTime" BU_SG_REL_ OCU SG_ 253 ESC_Reku_Freigabe 500;
BA_REL_ "GenSigTimeoutTime" BU_SG_REL_ OCU SG_ 253 ESC_v_Signal_Qualifier_High_Low 500;
BA_REL_ "GenSigTimeoutTime" BU_SG_REL_ OCU SG_ 253 ESP_v_Signal 500;
BA_REL_ "GenSigTimeoutTime" BU_SG_REL_ OCU SG_ 253 ASR_Tastung_passiv 500;
BA_REL_ "GenSigTimeoutTime" BU_SG_REL_ OCU SG_ 253 ESP_Tastung_passiv 500;
BA_REL_ "GenSigTimeoutTime" BU_SG_REL_ OCU SG_ 253 ESP_Systemstatus 500;
BA_REL_ "GenSigTimeoutTime" BU_SG_REL_ OCU SG_ 253 ESP_MKB_Abbruch_Geschw 500;
BA_REL_ "GenSigTimeoutTime" BU_SG_REL_ OCU SG_ 253 ESP_QBit_v_Signal 500;
BA_REL_ "GenSigTimeoutTime" BU_SG_REL_ OCU SG_ 253 ABS_Bremsung 500;
BA_REL_ "GenSigTimeoutTime" BU_SG_REL_ OCU SG_ 253 ASR_Anf 500;
BA_REL_ "GenSigTimeoutTime" BU_SG_REL_ OCU SG_ 253 EBV_Eingriff 500;
BA_REL_ "GenSigTimeoutTime" BU_SG_REL_ OCU SG_ 253 EDS_Eingriff 500;
BA_REL_ "GenSigTimeoutTime" BU_SG_REL_ OCU SG_ 253 ESP_Eingriff 500;
BA_REL_ "GenSigTimeoutTime" BU_SG_REL_ OCU SG_ 795 ESP_24_CRC 500;
BA_REL_ "GenSigTimeoutTime" BU_SG_REL_ OCU SG_ 795 ESP_24_BZ 500;
BA_REL_ "GenSigTimeoutTime" BU_SG_REL_ OCU SG_ 795 ABS_Lampe 500;
BA_REL_ "GenSigTimeoutTime" BU_SG_REL_ OCU SG_ 795 ESP_m_Raddrehz 500;
BA_REL_ "GenSigTimeoutTime" BU_SG_REL_ OCU SG_ 795 ESP_Textanzeigen_03 500;
BA_REL_ "GenSigTimeoutTime" BU_SG_REL_ OCU SG_ 795 ESP_Wegimp_VA 500;
BA_REL_ "GenSigTimeoutTime" BU_SG_REL_ OCU SG_ 795 ESP_Fehlerstatus_Wegimp 500;
BA_REL_ "GenSigTimeoutTime" BU_SG_REL_ OCU SG_ 795 ESP_Wegimp_Ueberlauf 500;
BA_REL_ "GenSigTimeoutTime" BU_SG_REL_ OCU SG_ 795 ESP_QBit_Wegimp_VA 500;
BA_REL_ "GenSigTimeoutTime" BU_SG_REL_ OCU SG_ 986 EPB_01_alt 1000;
BA_REL_ "GenSigTimeoutTime" BU_SG_REL_ OCU SG_ 986 Kamera_Status_alt 1000;
BA_REL_ "GenSigTimeoutTime" BU_SG_REL_ OCU SG_ 986 EPB_Status 1000;
BA_REL_ "GenSigTimeoutTime" BU_SG_REL_ OCU SG_ 986 EPB_QBit_Pedalweg_Kuppl 1000;
BA_REL_ "GenSigTimeoutTime" BU_SG_REL_ OCU SG_ 986 Kamera_FSH_aktiv 1000;
BA_REL_ "GenSigTimeoutTime" BU_SG_REL_ OCU SG_ 986 EPB_Pedalweg_Kuppl 1000;
BA_REL_ "GenSigTimeoutTime" BU_SG_REL_ OCU SG_ 988 Motor_12_alt 500;
BA_REL_ "GenSigTimeoutTime" BU_SG_REL_ OCU SG_ 988 ESP_07_alt 500;
BA_REL_ "GenSigTimeoutTime" BU_SG_REL_ OCU SG_ 988 Getriebe_13_alt 500;
BA_REL_ "GenSigTimeoutTime" BU_SG_REL_ OCU SG_ 988 Getriebe_17_alt 500;
BA_REL_ "GenSigTimeoutTime" BU_SG_REL_ OCU SG_ 988 TSK_06_alt 500;
BA_REL_ "GenSigTimeoutTime" BU_SG_REL_ OCU SG_ 988 Getriebe_14_alt 500;
BA_REL_ "GenSigTimeoutTime" BU_SG_REL_ OCU SG_ 988 ESP_50_alt 500;
BA_REL_ "GenSigTimeoutTime" BU_SG_REL_ OCU SG_ 988 MO_QBit_Drehzahl_01 500;
BA_REL_ "GenSigTimeoutTime" BU_SG_REL_ OCU SG_ 988 TSK_Hauptschalter_GRA_ACC 500;
BA_REL_ "GenSigTimeoutTime" BU_SG_REL_ OCU SG_ 988 MO_Drehzahl_01 500;
BA_REL_ "GenSigTimeoutTime" BU_SG_REL_ OCU SG_ 988 TSK_Status 500;
BA_REL_ "GenSigTimeoutTime" BU_SG_REL_ OCU SG_ 988 EPB_Schalterposition 500;
BA_REL_ "GenSigTimeoutTime" BU_SG_REL_ OCU SG_ 988 GE_LaunchControl 500;
BA_REL_ "GenSigTimeoutTime" BU_SG_REL_ OCU SG_ 988 GE_Notlauf 500;
BA_REL_ "GenSigTimeoutTime" BU_SG_REL_ OCU SG_ 988 ESP_Rollenmodus_Deaktivieren 500;
BA_REL_ "GenSigTimeoutTime" BU_SG_REL_ OCU SG_ 988 GE_Freilauf_Status 500;
BA_REL_ "GenSigTimeoutTime" BU_SG_REL_ OCU SG_ 988 GE_Sperr_Info_WFS 500;
BA_REL_ "GenSigTimeoutTime" BU_SG_REL_ OCU SG_ 988 TSK_Limiter_ausgewaehlt 500;
BA_REL_ "GenSigTimeoutTime" BU_SG_REL_ OCU SG_ 988 GE_Veto_Rollfaehigkeit 500;
BA_REL_ "GenSigTimeoutTime" BU_SG_REL_ OCU SG_ 988 EPB_Status_02 500;
BA_REL_ "GenSigTimeoutTime" BU_SG_REL_ OCU SG_ 988 ACC_Status_ACC 500;
BA_REL_ "GenSigTimeoutTime" BU_SG_REL_ OCU SG_ 988 ACC_18_alt 500;
BA_REL_ "GenSigTimeoutTime" BU_SG_REL_ OCU SG_ 1002 Getriebe_14_alt 2000;
BA_REL_ "GenSigTimeoutTime" BU_SG_REL_ OCU SG_ 1002 Motor_20_alt 2000;
BA_REL_ "GenSigTimeoutTime" BU_SG_REL_ OCU SG_ 1002 EBKV_03_alt 2000;
BA_REL_ "GenSigTimeoutTime" BU_SG_REL_ OCU SG_ 1002 AWV_03_alt 2000;
BA_REL_ "GenSigTimeoutTime" BU_SG_REL_ OCU SG_ 1002 AWV_Verz_Freigabe 2000;
BA_REL_ "GenSigTimeoutTime" BU_SG_REL_ OCU SG_ 1002 AWV_Verz_Anf 2000;
BA_REL_ "GenSigTimeoutTime" BU_SG_REL_ OCU SG_ 1002 PaCo_DiETa_LED 2000;
BA_REL_ "GenSigTimeoutTime" BU_SG_REL_ OCU SG_ 1002 EBKV_Fahrer_bremst 2000;
BA_REL_ "GenSigTimeoutTime" BU_SG_REL_ OCU SG_ 1002 AWV_Zielobjekttyp 2000;
BA_REL_ "GenSigTimeoutTime" BU_SG_REL_ OCU SG_ 1002 GE_Sumpftemperatur 2000;
BA_REL_ "GenSigTimeoutTime" BU_SG_REL_ RDK_RS3 SG_ 1603 KBI_Einheit_Druck 5000;
BA_REL_ "GenSigTimeoutTime" BU_SG_REL_ RDK_RS3 SG_ 1603 KBI_Einheit_Temp 5000;
BA_REL_ "GenSigTimeoutTime" BU_SG_REL_ RDK_RS3 SG_ 278 ESP_HR_Fahrtrichtung 2000;
BA_REL_ "GenSigTimeoutTime" BU_SG_REL_ RDK_RS3 SG_ 253 ESP_v_Signal 500;
BA_REL_ "GenSigTimeoutTime" BU_SG_REL_ RDK_RS3 SG_ 253 ESP_QBit_v_Signal 500;
BA_REL_ "GenSigTimeoutTime" BU_SG_REL_ STH SG_ 253 ESP_21_CRC 500;
BA_REL_ "GenSigTimeoutTime" BU_SG_REL_ STH SG_ 253 ESP_21_BZ 500;
BA_REL_ "GenSigTimeoutTime" BU_SG_REL_ STH SG_ 253 ESP_v_Signal 500;
BA_REL_ "GenSigTimeoutTime" BU_SG_REL_ STH SG_ 253 ESP_QBit_v_Signal 500;
BA_REL_ "GenSigTimeoutTime" BU_SG_REL_ STH SG_ 988 Motor_12_alt 500;
BA_REL_ "GenSigTimeoutTime" BU_SG_REL_ STH SG_ 988 MO_Drehzahl_01 500;
BA_REL_ "GenSigTimeoutTime" BU_SG_REL_ ZR_MIB_EINSTIEG_ab_Gen3 SG_ 1520 DI_KL_58xd 2000;
BA_REL_ "GenSigTimeoutTime" BU_SG_REL_ ZR_MIB_EINSTIEG_ab_Gen3 SG_ 1520 DI_KL_58xs 2000;
BA_REL_ "GenSigTimeoutTime" BU_SG_REL_ ZR_MIB_EINSTIEG_ab_Gen3 SG_ 1520 DI_Display_Nachtdesign 2000;
BA_REL_ "GenSigTimeoutTime" BU_SG_REL_ ZR_MIB_EINSTIEG_ab_Gen3 SG_ 1603 KBI_Einheit_Sprache 5000;
BA_REL_ "GenSigTimeoutTime" BU_SG_REL_ ZR_MIB_EINSTIEG_ab_Gen3 SG_ 257 ESP_QBit_Gierrate 500;
BA_REL_ "GenSigTimeoutTime" BU_SG_REL_ ZR_MIB_EINSTIEG_ab_Gen3 SG_ 257 ESP_QBit_Laengsbeschl 500;
BA_REL_ "GenSigTimeoutTime" BU_SG_REL_ ZR_MIB_EINSTIEG_ab_Gen3 SG_ 257 ESP_QBit_Querb 500;
BA_REL_ "GenSigTimeoutTime" BU_SG_REL_ ZR_MIB_EINSTIEG_ab_Gen3 SG_ 257 ESP_Querbeschleunigung 500;
BA_REL_ "GenSigTimeoutTime" BU_SG_REL_ ZR_MIB_EINSTIEG_ab_Gen3 SG_ 257 ESP_Laengsbeschl 500;
BA_REL_ "GenSigTimeoutTime" BU_SG_REL_ ZR_MIB_EINSTIEG_ab_Gen3 SG_ 257 ESC_Motorstartverzoegerung 500;
BA_REL_ "GenSigTimeoutTime" BU_SG_REL_ ZR_MIB_EINSTIEG_ab_Gen3 SG_ 257 ESP_Anschleppstart_Freigabe 500;
BA_REL_ "GenSigTimeoutTime" BU_SG_REL_ ZR_MIB_EINSTIEG_ab_Gen3 SG_ 257 ESP_Gierrate 500;
BA_REL_ "GenSigTimeoutTime" BU_SG_REL_ ZR_MIB_EINSTIEG_ab_Gen3 SG_ 257 ESP_VZ_Gierrate 500;
BA_REL_ "GenSigTimeoutTime" BU_SG_REL_ ZR_MIB_EINSTIEG_ab_Gen3 SG_ 257 ESP_Notbremsanzeige 500;
BA_REL_ "GenSigTimeoutTime" BU_SG_REL_ ZR_MIB_EINSTIEG_ab_Gen3 SG_ 262 ESP_Bremsdruck 500;
BA_REL_ "GenSigTimeoutTime" BU_SG_REL_ ZR_MIB_EINSTIEG_ab_Gen3 SG_ 278 ESP_10_BZ 2000;
BA_REL_ "GenSigTimeoutTime" BU_SG_REL_ ZR_MIB_EINSTIEG_ab_Gen3 SG_ 278 ESP_QBit_Wegimpuls_VL 2000;
BA_REL_ "GenSigTimeoutTime" BU_SG_REL_ ZR_MIB_EINSTIEG_ab_Gen3 SG_ 278 ESP_QBit_Wegimpuls_VR 2000;
BA_REL_ "GenSigTimeoutTime" BU_SG_REL_ ZR_MIB_EINSTIEG_ab_Gen3 SG_ 278 ESP_QBit_Wegimpuls_HL 2000;
BA_REL_ "GenSigTimeoutTime" BU_SG_REL_ ZR_MIB_EINSTIEG_ab_Gen3 SG_ 278 ESP_QBit_Wegimpuls_HR 2000;
BA_REL_ "GenSigTimeoutTime" BU_SG_REL_ ZR_MIB_EINSTIEG_ab_Gen3 SG_ 278 ESP_Wegimpuls_VL 2000;
BA_REL_ "GenSigTimeoutTime" BU_SG_REL_ ZR_MIB_EINSTIEG_ab_Gen3 SG_ 278 ESP_Wegimpuls_VR 2000;
BA_REL_ "GenSigTimeoutTime" BU_SG_REL_ ZR_MIB_EINSTIEG_ab_Gen3 SG_ 278 ESP_Wegimpuls_HL 2000;
BA_REL_ "GenSigTimeoutTime" BU_SG_REL_ ZR_MIB_EINSTIEG_ab_Gen3 SG_ 278 ESP_Wegimpuls_HR 2000;
BA_REL_ "GenSigTimeoutTime" BU_SG_REL_ ZR_MIB_EINSTIEG_ab_Gen3 SG_ 278 ESP_VL_Fahrtrichtung 2000;
BA_REL_ "GenSigTimeoutTime" BU_SG_REL_ ZR_MIB_EINSTIEG_ab_Gen3 SG_ 278 ESP_VR_Fahrtrichtung 2000;
BA_REL_ "GenSigTimeoutTime" BU_SG_REL_ ZR_MIB_EINSTIEG_ab_Gen3 SG_ 278 ESP_HL_Fahrtrichtung 2000;
BA_REL_ "GenSigTimeoutTime" BU_SG_REL_ ZR_MIB_EINSTIEG_ab_Gen3 SG_ 278 ESP_HR_Fahrtrichtung 2000;
BA_REL_ "GenSigTimeoutTime" BU_SG_REL_ ZR_MIB_EINSTIEG_ab_Gen3 SG_ 1629 BR_Systemart 5000;
BA_REL_ "GenSigTimeoutTime" BU_SG_REL_ ZR_MIB_EINSTIEG_ab_Gen3 SG_ 1629 ESP_Zaehnezahl 5000;
BA_REL_ "GenSigTimeoutTime" BU_SG_REL_ ZR_MIB_EINSTIEG_ab_Gen3 SG_ 1629 BR_QBit_Reifenumfang 5000;
BA_REL_ "GenSigTimeoutTime" BU_SG_REL_ ZR_MIB_EINSTIEG_ab_Gen3 SG_ 1629 BR_Reifenumfang 5000;
BA_REL_ "GenSigTimeoutTime" BU_SG_REL_ ZR_MIB_EINSTIEG_ab_Gen3 SG_ 253 ESP_v_Signal 500;
BA_REL_ "GenSigTimeoutTime" BU_SG_REL_ ZR_MIB_EINSTIEG_ab_Gen3 SG_ 253 ESP_QBit_v_Signal 500;
BA_REL_ "GenSigTimeoutTime" BU_SG_REL_ ZR_MIB_EINSTIEG_ab_Gen3 SG_ 253 ESP_Eingriff 500;
BA_REL_ "GenSigTimeoutTime" BU_SG_REL_ ZR_MIB_EINSTIEG_ab_Gen3 SG_ 795 ESP_Lampe 500;
BA_REL_ "GenSigTimeoutTime" BU_SG_REL_ ZR_MIB_EINSTIEG_ab_Gen3 SG_ 795 ESP_m_Raddrehz 500;
BA_REL_ "GenSigTimeoutTime" BU_SG_REL_ ZR_MIB_EINSTIEG_ab_Gen3 SG_ 795 ESP_Textanzeigen_03 500;
BA_REL_ "GenSigTimeoutTime" BU_SG_REL_ ZR_MIB_EINSTIEG_ab_Gen3 SG_ 795 ESP_Wegimp_VA 500;
BA_REL_ "GenSigTimeoutTime" BU_SG_REL_ ZR_MIB_EINSTIEG_ab_Gen3 SG_ 795 ESP_Fehlerstatus_Wegimp 500;
BA_REL_ "GenSigTimeoutTime" BU_SG_REL_ ZR_MIB_EINSTIEG_ab_Gen3 SG_ 795 ESP_Wegimp_Ueberlauf 500;
BA_REL_ "GenSigTimeoutTime" BU_SG_REL_ ZR_MIB_EINSTIEG_ab_Gen3 SG_ 795 ESP_QBit_Wegimp_VA 500;
BA_REL_ "GenSigTimeoutTime" BU_SG_REL_ ZR_MIB_EINSTIEG_ab_Gen3 SG_ 986 EPB_01_alt 1000;
BA_REL_ "GenSigTimeoutTime" BU_SG_REL_ ZR_MIB_EINSTIEG_ab_Gen3 SG_ 986 LWI_01_alt 1000;
BA_REL_ "GenSigTimeoutTime" BU_SG_REL_ ZR_MIB_EINSTIEG_ab_Gen3 SG_ 986 EPB_Status 1000;
BA_REL_ "GenSigTimeoutTime" BU_SG_REL_ ZR_MIB_EINSTIEG_ab_Gen3 SG_ 986 LWI_QBit_Lenkradwinkel 1000;
BA_REL_ "GenSigTimeoutTime" BU_SG_REL_ ZR_MIB_EINSTIEG_ab_Gen3 SG_ 986 LWI_Sensorstatus 1000;
BA_REL_ "GenSigTimeoutTime" BU_SG_REL_ ZR_MIB_EINSTIEG_ab_Gen3 SG_ 986 LWI_VZ_Lenkradwinkel 1000;
BA_REL_ "GenSigTimeoutTime" BU_SG_REL_ ZR_MIB_EINSTIEG_ab_Gen3 SG_ 986 LWI_Lenkradwinkel 1000;
BA_REL_ "GenSigTimeoutTime" BU_SG_REL_ ZR_MIB_EINSTIEG_ab_Gen3 SG_ 988 Motor_12_alt 500;
BA_REL_ "GenSigTimeoutTime" BU_SG_REL_ ZR_MIB_EINSTIEG_ab_Gen3 SG_ 988 ESP_07_alt 500;
BA_REL_ "GenSigTimeoutTime" BU_SG_REL_ ZR_MIB_EINSTIEG_ab_Gen3 SG_ 988 MO_Drehzahl_01 500;
BA_REL_ "GenSigTimeoutTime" BU_SG_REL_ ZR_MIB_EINSTIEG_ab_Gen3 SG_ 988 ESP_Rollenmodus_Deaktivieren 500;
BA_REL_ "GenSigTimeoutTime" BU_SG_REL_ ZR_MIB_EINSTIEG_ab_Gen3 SG_ 1002 Getriebe_14_alt 2000;
BA_REL_ "GenSigTimeoutTime" BU_SG_REL_ ZR_MIB_EINSTIEG_ab_Gen3 SG_ 1002 Motor_11_alt 2000;
BA_REL_ "GenSigTimeoutTime" BU_SG_REL_ ZR_MIB_EINSTIEG_ab_Gen3 SG_ 1002 Motor_20_alt 2000;
BA_REL_ "GenSigTimeoutTime" BU_SG_REL_ ZR_MIB_EINSTIEG_ab_Gen3 SG_ 1002 GE_Sumpftemperatur 2000;
BA_REL_ "GenSigTimeoutTime" BU_SG_REL_ ZR_MIB_EINSTIEG_ab_Gen3 SG_ 1004 LIN_2_alt 2000;
BA_REL_ "GenSigTimeoutTime" BU_SG_REL_ ZR_MIB_EINSTIEG_ab_Gen3 SG_ 1004 MFL_Touch_Event 2000;
BA_REL_ "GenSigTimeoutTime" BU_SG_REL_ ZR_MIB_EINSTIEG_ab_Gen3 SG_ 879 GNSS_Nachrichtenpaket_ID1 5000;
BA_REL_ "GenSigTimeoutTime" BU_SG_REL_ ZR_MIB_EINSTIEG_ab_Gen3 SG_ 879 GNSS_Breite_Ortung 5000;
BA_REL_ "GenSigTimeoutTime" BU_SG_REL_ ZR_MIB_EINSTIEG_ab_Gen3 SG_ 879 GNSS_Richtung_Breite_Ortung 5000;
BA_REL_ "GenSigTimeoutTime" BU_SG_REL_ ZR_MIB_EINSTIEG_ab_Gen3 SG_ 879 GNSS_Laenge_Ortung 5000;
BA_REL_ "GenSigTimeoutTime" BU_SG_REL_ ZR_MIB_EINSTIEG_ab_Gen3 SG_ 879 GNSS_Richtung_Laenge_Ortung 5000;
BA_REL_ "GenSigTimeoutTime" BU_SG_REL_ ZR_MIB_EINSTIEG_ab_Gen3 SG_ 879 GNSS_Ortung_FIX_Typ 5000;
BA_REL_ "GenSigTimeoutTime" BU_SG_REL_ ZR_MIB_EINSTIEG_ab_Gen3 SG_ 879 GNSS_Fehlerzustand 5000;
BA_REL_ "GenSigTimeoutTime" BU_SG_REL_ ZR_MIB_EINSTIEG_ab_Gen3 SG_ 884 GNSS_Nachrichtenpaket_ID2 5000;
BA_REL_ "GenSigTimeoutTime" BU_SG_REL_ ZR_MIB_EINSTIEG_ab_Gen3 SG_ 884 GNSS_Ortung_Latenz 5000;
BA_REL_ "GenSigTimeoutTime" BU_SG_REL_ ZR_MIB_EINSTIEG_ab_Gen3 SG_ 884 GNSS_Ortung_Ausrichtung 5000;
BA_REL_ "GenSigTimeoutTime" BU_SG_REL_ ZR_MIB_EINSTIEG_ab_Gen3 SG_ 884 GNSS_Ortung_2D_Geschw_ue_Grund 5000;
BA_REL_ "GenSigTimeoutTime" BU_SG_REL_ ZR_MIB_EINSTIEG_ab_Gen3 SG_ 884 GNSS_Ortung_Noerdliche_Geschw 5000;
BA_REL_ "GenSigTimeoutTime" BU_SG_REL_ ZR_MIB_EINSTIEG_ab_Gen3 SG_ 884 GNSS_Ortung_Oestliche_Geschw 5000;
BA_REL_ "GenSigTimeoutTime" BU_SG_REL_ ZR_MIB_EINSTIEG_ab_Gen3 SG_ 884 GNSS_Ortung_Vertikale_Geschw 5000;
BA_REL_ "GenSigTimeoutTime" BU_SG_REL_ ZR_MIB_OPTION_ab_Gen3 SG_ 1520 DI_KL_58xd 2000;
BA_REL_ "GenSigTimeoutTime" BU_SG_REL_ ZR_MIB_OPTION_ab_Gen3 SG_ 1520 DI_KL_58xs 2000;
BA_REL_ "GenSigTimeoutTime" BU_SG_REL_ ZR_MIB_OPTION_ab_Gen3 SG_ 1520 DI_Display_Nachtdesign 2000;
BA_REL_ "GenSigTimeoutTime" BU_SG_REL_ ZR_MIB_OPTION_ab_Gen3 SG_ 1520 DI_KL_58xt 2000;
BA_REL_ "GenSigTimeoutTime" BU_SG_REL_ ZR_MIB_OPTION_ab_Gen3 SG_ 2527679886 Drehschalter_Aktive_Ebene 5000;
BA_REL_ "GenSigTimeoutTime" BU_SG_REL_ ZR_MIB_OPTION_ab_Gen3 SG_ 2527679886 Drehschalter_defekt 5000;
BA_REL_ "GenSigTimeoutTime" BU_SG_REL_ ZR_MIB_OPTION_ab_Gen3 SG_ 2527679886 Drehschalter_Taster 5000;
BA_REL_ "GenSigTimeoutTime" BU_SG_REL_ ZR_MIB_OPTION_ab_Gen3 SG_ 2527679886 Drehschalter_Touch 5000;
BA_REL_ "GenSigTimeoutTime" BU_SG_REL_ ZR_MIB_OPTION_ab_Gen3 SG_ 2527679886 Drehschalter_Ist_Atmosphere 5000;
BA_REL_ "GenSigTimeoutTime" BU_SG_REL_ ZR_MIB_OPTION_ab_Gen3 SG_ 2527679886 Drehschalter_Display_Action 5000;
BA_REL_ "GenSigTimeoutTime" BU_SG_REL_ ZR_MIB_OPTION_ab_Gen3 SG_ 2527679886 BedienDisp_m_Control 5000;
BA_REL_ "GenSigTimeoutTime" BU_SG_REL_ ZR_MIB_OPTION_ab_Gen3 SG_ 257 ESP_QBit_Gierrate 500;
BA_REL_ "GenSigTimeoutTime" BU_SG_REL_ ZR_MIB_OPTION_ab_Gen3 SG_ 257 ESP_QBit_Laengsbeschl 500;
BA_REL_ "GenSigTimeoutTime" BU_SG_REL_ ZR_MIB_OPTION_ab_Gen3 SG_ 257 ESP_QBit_Querb 500;
BA_REL_ "GenSigTimeoutTime" BU_SG_REL_ ZR_MIB_OPTION_ab_Gen3 SG_ 257 ESP_Querbeschleunigung 500;
BA_REL_ "GenSigTimeoutTime" BU_SG_REL_ ZR_MIB_OPTION_ab_Gen3 SG_ 257 ESP_Laengsbeschl 500;
BA_REL_ "GenSigTimeoutTime" BU_SG_REL_ ZR_MIB_OPTION_ab_Gen3 SG_ 257 ESP_Gierrate 500;
BA_REL_ "GenSigTimeoutTime" BU_SG_REL_ ZR_MIB_OPTION_ab_Gen3 SG_ 257 ESP_VZ_Gierrate 500;
BA_REL_ "GenSigTimeoutTime" BU_SG_REL_ ZR_MIB_OPTION_ab_Gen3 SG_ 262 ESP_Bremsdruck 500;
BA_REL_ "GenSigTimeoutTime" BU_SG_REL_ ZR_MIB_OPTION_ab_Gen3 SG_ 262 ESP_HDC_Standby 500;
BA_REL_ "GenSigTimeoutTime" BU_SG_REL_ ZR_MIB_OPTION_ab_Gen3 SG_ 262 ESP_HDC_aktiv 500;
BA_REL_ "GenSigTimeoutTime" BU_SG_REL_ ZR_MIB_OPTION_ab_Gen3 SG_ 278 ESP_10_BZ 2000;
BA_REL_ "GenSigTimeoutTime" BU_SG_REL_ ZR_MIB_OPTION_ab_Gen3 SG_ 278 ESP_QBit_Wegimpuls_VL 2000;
BA_REL_ "GenSigTimeoutTime" BU_SG_REL_ ZR_MIB_OPTION_ab_Gen3 SG_ 278 ESP_QBit_Wegimpuls_VR 2000;
BA_REL_ "GenSigTimeoutTime" BU_SG_REL_ ZR_MIB_OPTION_ab_Gen3 SG_ 278 ESP_QBit_Wegimpuls_HL 2000;
BA_REL_ "GenSigTimeoutTime" BU_SG_REL_ ZR_MIB_OPTION_ab_Gen3 SG_ 278 ESP_QBit_Wegimpuls_HR 2000;
BA_REL_ "GenSigTimeoutTime" BU_SG_REL_ ZR_MIB_OPTION_ab_Gen3 SG_ 278 ESP_Wegimpuls_VL 2000;
BA_REL_ "GenSigTimeoutTime" BU_SG_REL_ ZR_MIB_OPTION_ab_Gen3 SG_ 278 ESP_Wegimpuls_VR 2000;
BA_REL_ "GenSigTimeoutTime" BU_SG_REL_ ZR_MIB_OPTION_ab_Gen3 SG_ 278 ESP_Wegimpuls_HL 2000;
BA_REL_ "GenSigTimeoutTime" BU_SG_REL_ ZR_MIB_OPTION_ab_Gen3 SG_ 278 ESP_Wegimpuls_HR 2000;
BA_REL_ "GenSigTimeoutTime" BU_SG_REL_ ZR_MIB_OPTION_ab_Gen3 SG_ 278 ESP_VL_Fahrtrichtung 2000;
BA_REL_ "GenSigTimeoutTime" BU_SG_REL_ ZR_MIB_OPTION_ab_Gen3 SG_ 278 ESP_VR_Fahrtrichtung 2000;
BA_REL_ "GenSigTimeoutTime" BU_SG_REL_ ZR_MIB_OPTION_ab_Gen3 SG_ 278 ESP_HL_Fahrtrichtung 2000;
BA_REL_ "GenSigTimeoutTime" BU_SG_REL_ ZR_MIB_OPTION_ab_Gen3 SG_ 278 ESP_HR_Fahrtrichtung 2000;
BA_REL_ "GenSigTimeoutTime" BU_SG_REL_ ZR_MIB_OPTION_ab_Gen3 SG_ 1629 ESP_Zaehnezahl 5000;
BA_REL_ "GenSigTimeoutTime" BU_SG_REL_ ZR_MIB_OPTION_ab_Gen3 SG_ 253 ESP_v_Signal 500;
BA_REL_ "GenSigTimeoutTime" BU_SG_REL_ ZR_MIB_OPTION_ab_Gen3 SG_ 253 ESP_QBit_v_Signal 500;
BA_REL_ "GenSigTimeoutTime" BU_SG_REL_ ZR_MIB_OPTION_ab_Gen3 SG_ 253 ESP_Eingriff 500;
BA_REL_ "GenSigTimeoutTime" BU_SG_REL_ ZR_MIB_OPTION_ab_Gen3 SG_ 795 ESP_Wegimp_VA 500;
BA_REL_ "GenSigTimeoutTime" BU_SG_REL_ ZR_MIB_OPTION_ab_Gen3 SG_ 795 ESP_Fehlerstatus_Wegimp 500;
BA_REL_ "GenSigTimeoutTime" BU_SG_REL_ ZR_MIB_OPTION_ab_Gen3 SG_ 795 ESP_Wegimp_Ueberlauf 500;
BA_REL_ "GenSigTimeoutTime" BU_SG_REL_ ZR_MIB_OPTION_ab_Gen3 SG_ 795 ESP_QBit_Wegimp_VA 500;
BA_REL_ "GenSigTimeoutTime" BU_SG_REL_ ZR_MIB_OPTION_ab_Gen3 SG_ 986 EPB_01_alt 1000;
BA_REL_ "GenSigTimeoutTime" BU_SG_REL_ ZR_MIB_OPTION_ab_Gen3 SG_ 986 LWI_01_alt 1000;
BA_REL_ "GenSigTimeoutTime" BU_SG_REL_ ZR_MIB_OPTION_ab_Gen3 SG_ 986 EPB_Status 1000;
BA_REL_ "GenSigTimeoutTime" BU_SG_REL_ ZR_MIB_OPTION_ab_Gen3 SG_ 986 LWI_QBit_Lenkradwinkel 1000;
BA_REL_ "GenSigTimeoutTime" BU_SG_REL_ ZR_MIB_OPTION_ab_Gen3 SG_ 986 LWI_Sensorstatus 1000;
BA_REL_ "GenSigTimeoutTime" BU_SG_REL_ ZR_MIB_OPTION_ab_Gen3 SG_ 986 LWI_VZ_Lenkradwinkel 1000;
BA_REL_ "GenSigTimeoutTime" BU_SG_REL_ ZR_MIB_OPTION_ab_Gen3 SG_ 986 LWI_Lenkradwinkel 1000;
BA_REL_ "GenSigTimeoutTime" BU_SG_REL_ ZR_MIB_OPTION_ab_Gen3 SG_ 988 Motor_12_alt 500;
BA_REL_ "GenSigTimeoutTime" BU_SG_REL_ ZR_MIB_OPTION_ab_Gen3 SG_ 988 ESP_07_alt 500;
BA_REL_ "GenSigTimeoutTime" BU_SG_REL_ ZR_MIB_OPTION_ab_Gen3 SG_ 988 MO_Drehzahl_01 500;
BA_REL_ "GenSigTimeoutTime" BU_SG_REL_ ZR_MIB_OPTION_ab_Gen3 SG_ 988 ESP_Rollenmodus_Deaktivieren 500;
BA_REL_ "GenSigTimeoutTime" BU_SG_REL_ ZR_MIB_OPTION_ab_Gen3 SG_ 1002 Getriebe_14_alt 2000;
BA_REL_ "GenSigTimeoutTime" BU_SG_REL_ ZR_MIB_OPTION_ab_Gen3 SG_ 1002 Motor_11_alt 2000;
BA_REL_ "GenSigTimeoutTime" BU_SG_REL_ ZR_MIB_OPTION_ab_Gen3 SG_ 1002 Motor_20_alt 2000;
BA_REL_ "GenSigTimeoutTime" BU_SG_REL_ ZR_MIB_OPTION_ab_Gen3 SG_ 1002 GE_Sumpftemperatur 2000;
BA_REL_ "GenSigTimeoutTime" BU_SG_REL_ ZR_MIB_OPTION_ab_Gen3 SG_ 1004 LIN_2_alt 2000;
BA_REL_ "GenSigTimeoutTime" BU_SG_REL_ ZR_MIB_OPTION_ab_Gen3 SG_ 1004 MFL_Touch_Event 2000;
BA_REL_ "GenSigTimeoutTime" BU_SG_REL_ ZR_MIB_TOP_ab_Gen3 SG_ 1603 KBI_Einheit_Datum 5000;
BA_REL_ "GenSigTimeoutTime" BU_SG_REL_ ZR_MIB_TOP_ab_Gen3 SG_ 1603 KBI_Einheit_Druck 5000;
BA_REL_ "GenSigTimeoutTime" BU_SG_REL_ ZR_MIB_TOP_ab_Gen3 SG_ 1603 KBI_Einheit_Streckenanz 5000;
BA_REL_ "GenSigTimeoutTime" BU_SG_REL_ ZR_MIB_TOP_ab_Gen3 SG_ 1603 KBI_MFA_v_Einheit_02 5000;
BA_REL_ "GenSigTimeoutTime" BU_SG_REL_ ZR_MIB_TOP_ab_Gen3 SG_ 1603 KBI_Einheit_Temp 5000;
BA_REL_ "GenSigTimeoutTime" BU_SG_REL_ ZR_MIB_TOP_ab_Gen3 SG_ 1603 KBI_Einheit_Uhrzeit 5000;
BA_REL_ "GenSigTimeoutTime" BU_SG_REL_ ZR_MIB_TOP_ab_Gen3 SG_ 1603 KBI_Einheit_Verbrauch 5000;
BA_REL_ "GenSigTimeoutTime" BU_SG_REL_ ZR_MIB_TOP_ab_Gen3 SG_ 1603 KBI_Einheit_Volumen 5000;
BA_REL_ "GenSigTimeoutTime" BU_SG_REL_ ZR_MIB_TOP_ab_Gen3 SG_ 1603 KBI_Einheit_Sprache 5000;
BA_REL_ "GenSigTimeoutTime" BU_SG_REL_ ZR_MIB_TOP_ab_Gen3 SG_ 1603 KBI_Einheit_Masse 5000;
BA_REL_ "GenSigTimeoutTime" BU_SG_REL_ ZR_MIB_TOP_ab_Gen3 SG_ 257 ESP_QBit_Gierrate 500;
BA_REL_ "GenSigTimeoutTime" BU_SG_REL_ ZR_MIB_TOP_ab_Gen3 SG_ 257 ESP_QBit_Laengsbeschl 500;
BA_REL_ "GenSigTimeoutTime" BU_SG_REL_ ZR_MIB_TOP_ab_Gen3 SG_ 257 ESP_QBit_Querb 500;
BA_REL_ "GenSigTimeoutTime" BU_SG_REL_ ZR_MIB_TOP_ab_Gen3 SG_ 257 ESP_Querbeschleunigung 500;
BA_REL_ "GenSigTimeoutTime" BU_SG_REL_ ZR_MIB_TOP_ab_Gen3 SG_ 257 ESP_Laengsbeschl 500;
BA_REL_ "GenSigTimeoutTime" BU_SG_REL_ ZR_MIB_TOP_ab_Gen3 SG_ 257 ESP_Gierrate 500;
BA_REL_ "GenSigTimeoutTime" BU_SG_REL_ ZR_MIB_TOP_ab_Gen3 SG_ 257 ESP_VZ_Gierrate 500;
BA_REL_ "GenSigTimeoutTime" BU_SG_REL_ ZR_MIB_TOP_ab_Gen3 SG_ 262 ESP_Bremsdruck 500;
BA_REL_ "GenSigTimeoutTime" BU_SG_REL_ ZR_MIB_TOP_ab_Gen3 SG_ 278 ESP_QBit_Wegimpuls_VL 2000;
BA_REL_ "GenSigTimeoutTime" BU_SG_REL_ ZR_MIB_TOP_ab_Gen3 SG_ 278 ESP_QBit_Wegimpuls_VR 2000;
BA_REL_ "GenSigTimeoutTime" BU_SG_REL_ ZR_MIB_TOP_ab_Gen3 SG_ 278 ESP_QBit_Wegimpuls_HL 2000;
BA_REL_ "GenSigTimeoutTime" BU_SG_REL_ ZR_MIB_TOP_ab_Gen3 SG_ 278 ESP_QBit_Wegimpuls_HR 2000;
BA_REL_ "GenSigTimeoutTime" BU_SG_REL_ ZR_MIB_TOP_ab_Gen3 SG_ 278 ESP_Wegimpuls_VL 2000;
BA_REL_ "GenSigTimeoutTime" BU_SG_REL_ ZR_MIB_TOP_ab_Gen3 SG_ 278 ESP_Wegimpuls_VR 2000;
BA_REL_ "GenSigTimeoutTime" BU_SG_REL_ ZR_MIB_TOP_ab_Gen3 SG_ 278 ESP_Wegimpuls_HL 2000;
BA_REL_ "GenSigTimeoutTime" BU_SG_REL_ ZR_MIB_TOP_ab_Gen3 SG_ 278 ESP_Wegimpuls_HR 2000;
BA_REL_ "GenSigTimeoutTime" BU_SG_REL_ ZR_MIB_TOP_ab_Gen3 SG_ 278 ESP_VL_Fahrtrichtung 2000;
BA_REL_ "GenSigTimeoutTime" BU_SG_REL_ ZR_MIB_TOP_ab_Gen3 SG_ 278 ESP_VR_Fahrtrichtung 2000;
BA_REL_ "GenSigTimeoutTime" BU_SG_REL_ ZR_MIB_TOP_ab_Gen3 SG_ 278 ESP_HL_Fahrtrichtung 2000;
BA_REL_ "GenSigTimeoutTime" BU_SG_REL_ ZR_MIB_TOP_ab_Gen3 SG_ 1629 ESP_Zaehnezahl 5000;
BA_REL_ "GenSigTimeoutTime" BU_SG_REL_ ZR_MIB_TOP_ab_Gen3 SG_ 1629 BR_QBit_Reifenumfang 5000;
BA_REL_ "GenSigTimeoutTime" BU_SG_REL_ ZR_MIB_TOP_ab_Gen3 SG_ 1629 BR_Reifenumfang 5000;
BA_REL_ "GenSigTimeoutTime" BU_SG_REL_ ZR_MIB_TOP_ab_Gen3 SG_ 795 ESP_Lampe 500;
BA_REL_ "GenSigTimeoutTime" BU_SG_REL_ ZR_MIB_TOP_ab_Gen3 SG_ 795 ESP_Wegimp_VA 500;
BA_REL_ "GenSigTimeoutTime" BU_SG_REL_ ZR_MIB_TOP_ab_Gen3 SG_ 795 ESP_Fehlerstatus_Wegimp 500;
BA_REL_ "GenSigTimeoutTime" BU_SG_REL_ ZR_MIB_TOP_ab_Gen3 SG_ 795 ESP_Wegimp_Ueberlauf 500;
BA_REL_ "GenSigTimeoutTime" BU_SG_REL_ ZR_MIB_TOP_ab_Gen3 SG_ 795 ESP_QBit_Wegimp_VA 500;
BA_REL_ "GenSigTimeoutTime" BU_SG_REL_ ZR_MIB_TOP_ab_Gen3 SG_ 795 ESP_HDC_Regelgeschw 500;
BA_REL_ "GenSigTimeoutTime" BU_SG_REL_ ZR_MIB_TOP_ab_Gen3 SG_ 2589283617 ESP_Status_Bremsentemp_Anz 5000;
BA_REL_ "GenSigTimeoutTime" BU_SG_REL_ ZR_MIB_TOP_ab_Gen3 SG_ 986 EPB_01_alt 1000;
BA_REL_ "GenSigTimeoutTime" BU_SG_REL_ ZR_MIB_TOP_ab_Gen3 SG_ 986 LWI_01_alt 1000;
BA_REL_ "GenSigTimeoutTime" BU_SG_REL_ ZR_MIB_TOP_ab_Gen3 SG_ 986 EPB_Status 1000;
BA_REL_ "GenSigTimeoutTime" BU_SG_REL_ ZR_MIB_TOP_ab_Gen3 SG_ 986 LWI_QBit_Lenkradwinkel 1000;
BA_REL_ "GenSigTimeoutTime" BU_SG_REL_ ZR_MIB_TOP_ab_Gen3 SG_ 986 LWI_Sensorstatus 1000;
BA_REL_ "GenSigTimeoutTime" BU_SG_REL_ ZR_MIB_TOP_ab_Gen3 SG_ 986 LWI_VZ_Lenkradwinkel 1000;
BA_REL_ "GenSigTimeoutTime" BU_SG_REL_ ZR_MIB_TOP_ab_Gen3 SG_ 986 LWI_Lenkradwinkel 1000;
BA_REL_ "GenSigTimeoutTime" BU_SG_REL_ ZR_MIB_TOP_ab_Gen3 SG_ 988 Motor_12_alt 500;
BA_REL_ "GenSigTimeoutTime" BU_SG_REL_ ZR_MIB_TOP_ab_Gen3 SG_ 988 Getriebe_11_alt 500;
BA_REL_ "GenSigTimeoutTime" BU_SG_REL_ ZR_MIB_TOP_ab_Gen3 SG_ 988 MO_QBit_Drehzahl_01 500;
BA_REL_ "GenSigTimeoutTime" BU_SG_REL_ ZR_MIB_TOP_ab_Gen3 SG_ 988 MO_Drehzahl_01 500;
BA_REL_ "GenSigTimeoutTime" BU_SG_REL_ ZR_MIB_TOP_ab_Gen3 SG_ 988 GE_Fahrstufe 500;
BA_REL_ "GenSigTimeoutTime" BU_SG_REL_ ZR_MIB_TOP_ab_Gen3 SG_ 988 ESP_Rollenmodus_Deaktivieren 500;
BA_REL_ "GenSigTimeoutTime" BU_SG_REL_ ZR_MIB_TOP_ab_Gen3 SG_ 1002 Getriebe_14_alt 2000;
BA_REL_ "GenSigTimeoutTime" BU_SG_REL_ ZR_MIB_TOP_ab_Gen3 SG_ 1002 GE_Sumpftemperatur 2000;
BA_REL_ "GenSigTimeoutTime" BU_SG_REL_ ZR_MIB_TOP_ab_Gen3 SG_ 1004 LIN_2_alt 2000;
BA_REL_ "GenSigTimeoutTime" BU_SG_REL_ ZR_MIB_TOP_ab_Gen3 SG_ 1004 MFL_Touch_Event 2000;
BA_REL_ "GenSigTimeoutTime" BU_SG_REL_ ZR_MIB_TOP_ab_Gen3 SG_ 879 GNSS_Nachrichtenpaket_ID1 5000;
BA_REL_ "GenSigTimeoutTime" BU_SG_REL_ ZR_MIB_TOP_ab_Gen3 SG_ 879 GNSS_Breite_Ortung 5000;
BA_REL_ "GenSigTimeoutTime" BU_SG_REL_ ZR_MIB_TOP_ab_Gen3 SG_ 879 GNSS_Richtung_Breite_Ortung 5000;
BA_REL_ "GenSigTimeoutTime" BU_SG_REL_ ZR_MIB_TOP_ab_Gen3 SG_ 879 GNSS_Laenge_Ortung 5000;
BA_REL_ "GenSigTimeoutTime" BU_SG_REL_ ZR_MIB_TOP_ab_Gen3 SG_ 879 GNSS_Richtung_Laenge_Ortung 5000;
BA_REL_ "GenSigTimeoutTime" BU_SG_REL_ ZR_MIB_TOP_ab_Gen3 SG_ 879 GNSS_Ortung_FIX_Typ 5000;
BA_REL_ "GenSigTimeoutTime" BU_SG_REL_ ZR_MIB_TOP_ab_Gen3 SG_ 879 GNSS_Fehlerzustand 5000;
BA_REL_ "GenSigTimeoutTime" BU_SG_REL_ ZR_MIB_TOP_ab_Gen3 SG_ 884 GNSS_Nachrichtenpaket_ID2 5000;
BA_REL_ "GenSigTimeoutTime" BU_SG_REL_ ZR_MIB_TOP_ab_Gen3 SG_ 884 GNSS_Ortung_Latenz 5000;
BA_REL_ "GenSigTimeoutTime" BU_SG_REL_ ZR_MIB_TOP_ab_Gen3 SG_ 884 GNSS_Ortung_Ausrichtung 5000;
BA_REL_ "GenSigTimeoutTime" BU_SG_REL_ ZR_MIB_TOP_ab_Gen3 SG_ 884 GNSS_Ortung_2D_Geschw_ue_Grund 5000;
BA_REL_ "GenSigTimeoutTime" BU_SG_REL_ ZR_MIB_TOP_ab_Gen3 SG_ 884 GNSS_Ortung_Noerdliche_Geschw 5000;
BA_REL_ "GenSigTimeoutTime" BU_SG_REL_ ZR_MIB_TOP_ab_Gen3 SG_ 884 GNSS_Ortung_Oestliche_Geschw 5000;
BA_REL_ "GenSigTimeoutTime" BU_SG_REL_ ZR_MIB_TOP_ab_Gen3 SG_ 884 GNSS_Ortung_Vertikale_Geschw 5000;
VAL_ 1520 DI_KL_58xd 254 "Init" 255 "Fehler" ;
VAL_ 1520 DI_KL_58xs 126 "Init" 127 "Fehler" ;
VAL_ 1520 DI_KL_58xt 126 "Init" 127 "Fehler" ;
VAL_ 1520 BCM1_Stellgroesse_Kl_58s 125 "Nicht_verbaut" 126 "Init" 127 "Fehler" ;
VAL_ 1142 DU_State 0 "Disp_Off" 1 "Disp_On" 2 "LowPow" ;
VAL_ 1142 SystemMode 0 "Bootloader" 1 "Applikation" ;
VAL_ 1142 DU_Temp_Fehler 0 "normal" 1 "Fehler" ;
VAL_ 1142 DU_KL30_Uebersp_Fehler 0 "normal" 1 "Fehler" ;
VAL_ 1142 DU_KL30_Untersp_Fehler 0 "normal" 1 "Fehler" ;
VAL_ 1142 FB_Mode 0 "inaktiv" 1 "aktiv" ;
VAL_ 1142 DU_DispDerating 254 "Init" 255 "Fehler" ;
VAL_ 1142 DU_KL_30F 254 "Init" 255 "Fehler" ;
VAL_ 1142 DU_TempSens 254 "Init" 255 "Fehler" ;
VAL_ 1142 DU_TempSensMax 254 "Init" 255 "Fehler" ;
VAL_ 1142 DU_Variant 254 "Init" ;
VAL_ 1142 HU_Fotosensor 0 "Sensor unbeleuchtet" 510 "Initialwert" 511 "Fehler" ;
VAL_ 1143 DU_Betriebsdauer_min 255 "Fehler" ;
VAL_ 1143 DU_Betriebsdauer_std 65535 "Fehler" ;
VAL_ 1143 DU_HintGrdBelKurzschl 0 "normal" 1 "Fehler" ;
VAL_ 1143 DU_HintGrdBelUnterbr 0 "normal" 1 "Fehler" ;
VAL_ 1143 EEPROM_Fehler 0 "normal" 1 "Fehler" ;
VAL_ 1143 DU1_SW_inkonsistent 0 "kein_Fehler" 1 "Fehler" ;
VAL_ 1143 DU1_HDCP_Status 0 "kein_Fehler" 1 "Fehler" ;
VAL_ 1143 LVDS_Status 0 "LVDS_Unlocked" 1 "LVDS_Lock" ;
VAL_ 1143 ZR_Lenkerpos_Status 0 "links" 1 "rechts" ;
VAL_ 1143 DU1_Touch_Fehlerstatus 0 "kein_Fehler" 1 "SW_Fehler" 2 "HW_Fehler" ;
VAL_ 1143 DU1_Haptik_Fehlerstatus 0 "kein_Fehler" 1 "SW_Fehler" 2 "HW_Fehler" ;
VAL_ 1143 DU1_LVDS_Splitter_Fehlerstatus 0 "kein_Fehler" 1 "SW_Fehler" 2 "HW_Fehler" ;
VAL_ 561 DU1_KS_aktiv_anderer_Grund 0 "kein_Fehler" 1 "Fehler" ;
VAL_ 561 DU1_KS_aktiv_falsche_Auth 0 "kein_Fehler" 1 "Fehler" ;
VAL_ 561 DU1_KS_aktiv_Manipulationsschutz 0 "kein_Fehler" 1 "Fehler" ;
VAL_ 561 DU1_KS_FIS_unplausibel 0 "kein_Fehler" 1 "Fehler" ;
VAL_ 561 DU1_KS_keine_Grundeinstellung 0 "kein_Fehler" 1 "Fehler" ;
VAL_ 561 DU1_KS_SHE_keine_Grundeinst 0 "kein_Fehler" 1 "Fehler" ;
VAL_ 561 DU1_Touchstatus 0 "NoTouch" 1 "Touch" 2 "Release" ;
VAL_ 561 DU1_Fehlerstatus 0 "NoError" 1 "Backlight_defect" 2 "Backlight_off" ;
VAL_ 561 DU1_Slider_Locked 0 "unlocked" 1 "locked" ;
VAL_ 561 DU1_HWR_Fehlerstatus 0 "kein_Fehler" 1 "SW_Fehler" 2 "HW_Fehler" ;
VAL_ 2527679886 Drehschalter_Aktive_Ebene 0 "ohne_Verwendung" 1 "Ebene_1_aktiv" 2 "Ebene_2_aktiv" 3 "Ebene_3_aktiv" 4 "Ebene_4_aktiv" 5 "Ebene_5_aktiv" 6 "Ebene_6_aktiv" 7 "Ebene_7_aktiv" 8 "Ebene_8_aktiv" 9 "Ebene_9_aktiv" 10 "Ebene_10_aktiv" 11 "Ebene_11_aktiv" 12 "Ebene_12_aktiv" 13 "Ebene_13_aktiv" 14 "Ebene_14_aktiv" 15 "Ebene_15_aktiv" ;
VAL_ 2527679886 Drehschalter_defekt 0 "nicht_defekt" 1 "Funktion_defekt" 2 "AMB_Fluegel_defekt" 3 "nicht_belegt" 4 "nicht_belegt" 5 "nicht_belegt" 6 "nicht_belegt" 7 "nicht_belegt" 8 "nicht_belegt" 9 "nicht_belegt" 10 "nicht_belegt" 11 "nicht_belegt" 12 "nicht_belegt" 13 "nicht_belegt" 14 "nicht_belegt" 15 "nicht_belegt" ;
VAL_ 2527679886 Drehschalter_Taster 0 "nicht_betaetigt" 1 "betaetigt" 2 "reserviert" 3 "reserviert_Tastenklemmer" ;
VAL_ 2527679886 Drehschalter_Touch 0 "nicht_betaetigt" 1 "Tippen" 2 "Wischen_Slide" 3 "Geste" 4 "Doppeltippen_Doppelklick" 5 "Longpress_1_Halten_1" 6 "Longpress_2_Halten_2" 7 "Longpress_3_Halten_3" 8 "Press" 9 "Strong_Press" 10 "reserviert" 11 "reserviert" 12 "reserviert" 13 "reserviert" 14 "Taktgeber_Inkrement" 15 "Fehler" ;
VAL_ 2527679886 Drehschalter_Ist_Atmosphere 0 "Init" 1 "Atmosphere_1" 2 "Atmosphere_2" 3 "Atmosphere_3" 4 "Atmosphere_4" 5 "Atmosphere_5" 6 "Atmosphere_6" 7 "Atmosphere_7" 8 "Atmosphere_8" 9 "Atmosphere_9" 10 "Atmosphere_10" 11 "Atmosphere_11" 12 "Atmosphere_12" 13 "Atmosphere_13" 14 "Atmosphere_14" 15 "Atmosphere_15" 16 "Atmosphere_16" 17 "Atmosphere_17" 18 "Atmosphere_18" 19 "Atmosphere_19" 20 "Atmosphere_20" 21 "Atmosphere_21" 22 "Atmosphere_22" 23 "Atmosphere_23" 24 "Atmosphere_24" 25 "Atmosphere_25" 26 "Atmosphere_26" 27 "Atmosphere_27" 28 "Atmosphere_28" 29 "Atmosphere_29" 30 "Atmosphere_30" 31 "Atmosphere_31" 32 "Atmosphere_32" ;
VAL_ 2527679886 Drehschalter_Ist_Profil 0 "nicht_belegt" 1 "Profil_Comfort" 2 "Profil_Normal" 3 "Profil_Sport" 4 "Profil_Offroad" 5 "Profil_Eco" 6 "Profil_Race" 7 "Profil_Individual" 8 "Profil_Range" 9 "Profil_Lift" 10 "Profil_Snow" 11 "Profil_Offroad_Expert" 12 "nicht_belegt" 13 "nicht_belegt" 14 "nicht_belegt" 15 "nicht_belegt" 16 "Profil_Drift" 17 "Profil_Special" 18 "nicht_belegt" 19 "Profil_Traction" ;
VAL_ 2527679886 Drehschalter_Display_Action 0 "none" 1 "Tap" 2 "Swipe_left" 3 "Swipe_right" 4 "Swipe_up" 5 "Swipe_down" 6 "Swipe_Rotation_left" 7 "Swipe_Rotation_right" 8 "reserved" 9 "reserved" 10 "reserved" 11 "reserved" 12 "reserved" 13 "reserved" 14 "reserved" 15 "reserved" ;
VAL_ 2527679886 BedienDisp_m_Control 0 "Init" 1 "Mute" 2 "Rotary_up" 3 "Rotary_down" 15 "Fehler" ;
VAL_ 496 EA_Texte 0 "keine_Anzeige" 1 "Nothalteassistent_fehlende_Fahreraktivitaet" 2 "Nothalteassistent_aktiv_Fahrzeugfuehrung_uebernehmen" 3 "Nothalteassistent_automatischer_Nothalt_wird_durchgefuehrt" 4 "Nothalteassistent_automatischer_Nothalt_durchgefuehrt" 5 "Nothalteassistent_Verbindung_zum_Notruf_wird_aufgebaut" 6 "Nothalteassistent_deaktiviert" 7 "Nothalteassistent_Eingriff_abgebrochen" 8 "Nothalteassistent_fehlende_Fahreraktivitaet_2" 9 "Sekundenschlaf_erkannt" 10 "LaneAssist_Lenkung_uebernehmen" 11 "ACA_Fahrzeugfuehrung_uebernehmen" 12 "EA_Fahr_Standstreifenwechsel" 14 "Nothalteassistent_nicht_verfuegbar_reversibel" 15 "Nothalteassistent_Stoerung_irreversibel" ;
VAL_ 496 ACF_Lampe_Hands_Off 0 "keine_Anzeige" 1 "Hands_Off_erkannt" ;
VAL_ 496 EA_Fahrzeughupe_Anf 0 "keine_Anforderung" 1 "Anforderung_Fahrzeughupe" ;
VAL_ 496 EA_eCall_Anf 0 "Keine_Anforderung" 1 "Ausloesen_eCall" ;
VAL_ 496 EA_Infotainment_Anf 0 "Init" 1 "Keine_Absenkung" 2 "Absenkung" 3 "Mute" ;
VAL_ 496 EA_Tueren_Anf 0 "Keine_Anforderung" 1 "Tueren_entriegeln" ;
VAL_ 496 EA_Innenraumlicht_Anf 0 "Innenraumbeleuchtung_ausschalten" 1 "Innenraumbeleuchtung_einschalten" ;
VAL_ 496 zFAS_Warnblinken 0 "Aus" 1 "Statisch" 2 "Taster" 3 "Statisch_ohne_WBT" ;
VAL_ 496 STP_Primaeranz 0 "keine_Anzeige" 1 "Verfuegbar" 2 "Aktiv" 3 "Uebernahme" 4 "Aktiv_Warnung" 5 "Nicht_Verfuegbar" ;
VAL_ 496 EA_Bremslichtblinken 0 "kein_Blinken" 1 "Anforderung_Bremslichtblinken" ;
VAL_ 496 EA_Blinken 0 "Kein_Blinken" 1 "Wechselblinken_links" 2 "Wechselblinken_rechts" 3 "Warnblinken" 4 "Warnblinken_Taster" 5 "Richtungsblinken_links" 6 "Richtungsblinken_rechts" ;
VAL_ 496 EA_Status_HMI 0 "Keine_Anzeige" 1 "Aktiv_quer_laengs" 2 "Aktiv_laengs" ;
VAL_ 496 EA_Warnlevel 0 "keine_Gefaehrdung" 63 "max_Gefaehrdung" ;
VAL_ 1603 KBI_Einheit_Datum 0 "Tag/Monat/Jahr" 1 "Monat/Tag/Jahr" 2 "Jahr/Monat/Tag" 3 "reserviert" ;
VAL_ 1603 KBI_Einheit_Druck 0 "Druckangabe in bar" 1 "Druckangabe in psi" 2 "Druckangabe in kPa" 3 "tbd." ;
VAL_ 1603 KBI_Einheit_Streckenanz 0 "Kilometer" 1 "Meilen" ;
VAL_ 1603 KBI_MFA_v_Einheit_02 0 "kmh" 1 "mph" ;
VAL_ 1603 KBI_Einheit_Temp 0 "Grad Celsius °C" 1 "Grad Fahrenheit °F" ;
VAL_ 1603 KBI_Einheit_Uhrzeit 0 "24h" 1 " 12h AM/PM" ;
VAL_ 1603 KBI_Einheit_Verbrauch 0 "mpg UK" 1 "mpg USA" 2 "Liter/100km" 3 "km/Liter" ;
VAL_ 1603 KBI_Einheit_Volumen 0 "Liter" 1 "Gallonen UK" 2 "Gallonen USA" 3 "reserviert" ;
VAL_ 1603 KBI_Einheit_Verbrauch_elektr 0 "kWh_pro_100km" 1 "km_pro_kWh" 2 "kWh_pro_100mls" 3 "mls_pro_kWh" 4 "MPGe" ;
VAL_ 1603 KBI_Einheit_Tacho 0 "km/h" 1 "mph" ;
VAL_ 1603 KBI_Einheit_Verbrauch_Gas 0 "kg_per_100km" 1 "km_per_kg" 2 "m3_per_100km" 3 "km_per_m3" 4 "miles_per_lbs" 5 "miles_per_yard3" 6 "miles_per_kg" 7 "miles_per_m3" 8 "miles_per_gallon_equivalent_US" ;
VAL_ 1603 KBI_Einheit_Masse 0 "kg" 1 "lbs" 2 "reserviert" ;
VAL_ 257 ESP_QBit_Gierrate 0 "gueltiger_Wert" 1 "Ersatz_Init_oder_Fehlerwert" ;
VAL_ 257 ESP_QBit_Laengsbeschl 0 "gueltiger_Wert" 1 "Ersatz_Init_oder_Fehlerwert" ;
VAL_ 257 ESP_QBit_Querb 0 "gueltiger_Wert" 1 "Ersatz_Init_oder_Fehlerwert" ;
VAL_ 257 ESP_Querbeschleunigung 255 "Fehler" ;
VAL_ 257 ESP_Laengsbeschl 1022 "Signal_nicht_vorhanden" 1023 "Fehler" ;
VAL_ 257 ESC_Motorstartverzoegerung 0 "Startfreigabe" 1 "Anforderung_Startverzoegerung" ;
VAL_ 257 ESC_SeitenwindAssistent_Eingriff 0 "Kein_SWA_Eingriff_und_Init" 1 "SWA_Eingriff_aktiv" ;
VAL_ 257 ESP_Anschleppstart_Freigabe 0 "kein_Schleppstart_oder_NotSchleppstart_erlaubt" 1 "NotSchleppstart_erlaubt" 2 "Schleppstart_und_NotSchleppStart_erlaubt" ;
VAL_ 257 ESC_Unterdruckmangel_erkannt 0 "kein_Unterdruckmangel_erkannt" 1 "Unterdruckmangel_erkannt" ;
VAL_ 257 ESP_Gierrate 16383 "Fehler" ;
VAL_ 257 ESP_VZ_Gierrate 0 "positiv" 1 "negativ" ;
VAL_ 257 ESP_Notbremsanzeige 0 "keine_Notbremsung_erkannt" 1 "Notbremsung_erkannt" ;
VAL_ 257 ESP_SpannungsAnf 0 "keine_Anforderung" 1 "Anforderung_Spannungswert_1" ;
VAL_ 257 ESP_PLA_Abbruch 0 "Init" 1 "Geschwindigkeitsueberschreitung" 2 "Falscher_PLA_Status" 3 "Deaktivierung_durch_Abbruch_Lenkung" 4 "PLA_Bremsanforderung_nach_Stillstand" 5 "Abbruch_durch_Kl15_aus" 6 "Abbruch_durch_FT_offen" ;
VAL_ 257 ESP_Status_ESP_PLA 0 "ESP_PLA_deaktiv" 1 "ESP_PLA_Init" 2 "ESP_PLA_Fehler" 4 "ESP_PLA_aktivierbar" 6 "ESP_PLA_Bremse_aktiv" 8 "ESP_PLA_funktionsbereit" 9 "ESP_PLA_Neustart" 10 "ESP_PLA_Abbruch" ;
VAL_ 262 ESP_QBit_Bremsdruck 0 "gueltiger_Wert" 1 "Ersatz_Init_oder_Fehlerwert" ;
VAL_ 262 ESP_QBit_Fahrer_bremst 0 "gueltiger_Wert" 1 "Ersatz_Init_oder_Fehlerwert" ;
VAL_ 262 ESP_Schwelle_Unterdruck 0 "kein_Signal" 1 "Unterdruck_kleiner_gleich_450_mbar" 2 "Unterdruck_groesser_450_mbar" 3 "Fehler_Unterdrucksensor" ;
VAL_ 262 ESP_Bremsdruck 1023 "Fehler" ;
VAL_ 262 ESP_Fahrer_bremst 0 "Bremsdruckschwelle_nicht_ueberschritten" 1 "Bremsdruckschwelle_ueberschritten" ;
VAL_ 262 ESP_Verz_TSK_aktiv 0 "TSK_Verzoegerung_inaktiv" 1 "TSK_Verzoegerung_aktiv" ;
VAL_ 262 ESP_Lenkeingriff_ADS 0 "kein_Lenkeingriff" 1 "stabilisierender_Lenkeingriff" ;
VAL_ 262 ESP_Konsistenz_TSK 0 "Botschaft_fuer_Verzoegerungsanforderung_konsistent" 1 "Botschaft_fuer_Verzoegerungsanforderung_nicht_konsistent" ;
VAL_ 262 ESP_Bremsruck_AWV2 0 "kein_Bremsruck_ausgefuehrt" 1 "Bremsruck_ausgefuehrt" ;
VAL_ 262 ESP_Konsistenz_AWV2 0 "Botschaft_fuer_AWV2_konsistent" 1 "Botschaft_fuer_AWV2_nicht_konsistent" ;
VAL_ 262 ECD_Fehler 0 "ECD_iO" 1 "ECD_Fehler" ;
VAL_ 262 ECD_nicht_verfuegbar 0 "ECD_Funktion_verfuegbar" 1 "ECD_Funktion_nicht_verfuegbar" ;
VAL_ 262 ESP_Status_Bremsentemp 0 "Bremse_nicht_ueberhitzt" 1 "Bremse_ueberhitzt" ;
VAL_ 262 ESP_Autohold_Standby 0 "Autohold_nicht_im_Standby" 1 "Autohold_im_Standby" ;
VAL_ 262 ESP_HDC_Standby 0 "HDC_Funktion_nicht_im_Standby" 1 "HDC_Funktion_im_Standby" ;
VAL_ 262 ESP_HBA_aktiv 0 "HBA_nicht_aktiv" 1 "HBA_aktiv" ;
VAL_ 262 ESP_Prefill_ausgeloest 0 "nicht_ausgeloest" 1 "Prefill_ausgeloest" ;
VAL_ 262 ESP_Rueckwaertsfahrt_erkannt 0 "keine_Rueckwaetsfahrt" 1 "Rueckwaertsfahrt_sicher_erkannt" ;
VAL_ 262 ESP_Status_Anfahrhilfe 0 "Aus" 1 "Ein" ;
VAL_ 262 ESP_HDC_aktiv 0 "inaktiv" 1 "aktiv" ;
VAL_ 262 ESP_StartStopp_Info 0 "Motorlauf_nicht_notwendig_(Stoppfreigabe)" 1 "Motoranlauf_nicht_zwingend_notwendig_(Stoppverbot,keine_Startanforderung)" 2 "Motoranlauf_zwingend_notwendig_(Startanforderung)" 3 "Systemfehler" ;
VAL_ 262 ESP_Eingr_HL 0 "kein_Eingriff" 1 "ESP_Eingriff_HL" ;
VAL_ 262 ESP_Eingr_HR 0 "kein_Eingriff" 1 "ESP_Eingriff_HR" ;
VAL_ 262 ESP_Eingr_VL 0 "kein_Eingriff" 1 "ESP_Eingriff_VL" ;
VAL_ 262 ESP_Eingr_VR 0 "kein_Eingriff" 1 "ESP_Eingriff_VR" ;
VAL_ 262 ESP_BKV_Unterdruck 0 "nicht_verbaut_oder_nicht_kodiert" 254 "Init" 255 "Fehler" ;
VAL_ 262 ESP_Autohold_aktiv 0 "Autohold_inaktiv" 1 "Autohold_aktiv" ;
VAL_ 262 ESP_FStatus_Anfahrhilfe 0 "kein_Fehler" 1 "Fehler" ;
VAL_ 262 ESP_Verz_EPB_aktiv 0 "nicht_aktiviert" 1 "aktiviert" ;
VAL_ 262 ECD_Bremslicht 0 "Aus" 1 "Ein" ;
VAL_ 262 ESP_Verzoeg_EPB_verf 0 "nicht_verfuegbar" 1 "System_verfuegbar" ;
VAL_ 262 ESP_Status_Bremsdruck 0 "Bremse_drucklos" 1 "mit_Bremsdruck" ;
VAL_ 262 ESP_Anforderung_EPB 0 "keine_Anforderung" 1 "Anforderung_Oeffnen" 2 "Anforderung_Schliessen" 3 "reserviert" ;
VAL_ 278 ESP_QBit_Wegimpuls_VL 0 "gueltiger_Wert" 1 "Ersatz_Init_oder_Fehlerwert" ;
VAL_ 278 ESP_QBit_Wegimpuls_VR 0 "gueltiger_Wert" 1 "Ersatz_Init_oder_Fehlerwert" ;
VAL_ 278 ESP_QBit_Wegimpuls_HL 0 "gueltiger_Wert" 1 "Ersatz_Init_oder_Fehlerwert" ;
VAL_ 278 ESP_QBit_Wegimpuls_HR 0 "gueltiger_Wert" 1 "Ersatz_Init_oder_Fehlerwert" ;
VAL_ 278 ESP_Wegimpuls_VL 1021 "Init" 1022 "Unterspannung" 1023 "Fehler" ;
VAL_ 278 ESP_Wegimpuls_VR 1021 "Init" 1022 "Unterspannung" 1023 "Fehler" ;
VAL_ 278 ESP_Wegimpuls_HL 1021 "Init" 1022 "Unterspannung" 1023 "Fehler" ;
VAL_ 278 ESP_Wegimpuls_HR 1021 "Init" 1022 "Unterspannung" 1023 "Fehler" ;
VAL_ 278 ESP_VL_Fahrtrichtung 0 "Vorwaerts" 1 "Rueckwaerts" 2 "Init" 3 "ungueltig_oder_nicht_verbaut" ;
VAL_ 278 ESP_VR_Fahrtrichtung 0 "Vorwaerts" 1 "Rueckwaerts" 2 "Init" 3 "ungueltig_oder_nicht_verbaut" ;
VAL_ 278 ESP_HL_Fahrtrichtung 0 "Vorwaerts" 1 "Rueckwaerts" 2 "Init" 3 "ungueltig_oder_nicht_verbaut" ;
VAL_ 278 ESP_HR_Fahrtrichtung 0 "Vorwaerts" 1 "Rueckwaerts" 2 "Init" 3 "ungueltig_oder_nicht_verbaut" ;
VAL_ 1629 BR_Systemart 0 "ABS" 1 "ABS_ASR" 2 "ESP" 3 "ESP_mit_integrierter_EPB" ;
VAL_ 1629 ESP_SpannungsAnf_02 0 "keine_Anforderung" 1 "Anforderung_Stufe1" 2 "Anforderung_Stufe2" 3 "Anforderung_Stufe3" ;
VAL_ 1629 ESP_Charisma_FahrPr 0 "keine_Funktion" 1 "Programm_1" 2 "Programm_2" 3 "Programm_3" 4 "Programm_4" 5 "Programm_5" 6 "Programm_6" 7 "Programm_7" 8 "Programm_8" 9 "Programm_9" 10 "Programm_10" 11 "Programm_11" 12 "Programm_12" 13 "Programm_13" 14 "Programm_14" 15 "Programm_15" ;
VAL_ 1629 ESP_Charisma_Status 0 "Init" 1 "verfuegbar" 2 "nicht_verfuegbar" 3 "asynchron_durch_Fahrerwunsch" ;
VAL_ 1629 ESP_Wiederstart_Anz_01 0 "keine_Anzeige" 1 "Rueckwaertsrollen" ;
VAL_ 1629 ESP_Wiederstart_Anz_02 0 "keine_Anzeige" 1 "Autohold_Rutschen" ;
VAL_ 1629 ESP_Wiederstart_Anz_03 0 "keine_Anzeige" 1 "Offroad_HDC" ;
VAL_ 1629 ESP_Wiederstart_Anz_04 0 "keine_Anzeige" 1 "ESC_Off" ;
VAL_ 1629 ESP_Stoppverbot_Anz_01 0 "keine_Anzeige" 1 "Notbremsung_aktiv" ;
VAL_ 1629 ESP_Stoppverbot_Anz_02 0 "keine_Anzeige" 1 "Autohold_AVH_Rutschen" ;
VAL_ 1629 ESP_Stoppverbot_Anz_03 0 "keine_Anzeige" 1 "Rueckwaertsrollen" ;
VAL_ 1629 ESP_Stoppverbot_Anz_04 0 "keine_Anzeige" 1 "ESP_Pumpenlauf" ;
VAL_ 1629 ESP_Stoppverbot_Anz_05 0 "keine_Anzeige" 1 "ESP_OFF" ;
VAL_ 1629 ESP_Stoppverbot_Anz_06 0 "keine_Anzeige" 1 "Offroad_HDC" ;
VAL_ 1629 ESP_Stoppverbot_Anz_07 0 "keine_Anzeige" 1 "ESP_Haltefunktion_nicht_verfuegbar" ;
VAL_ 1629 ESP_Stoppverbot_Anz_Std 0 "keine_Anzeige" 1 "Standard_Stoppvetogrund" ;
VAL_ 1629 ESP_Dachrelingsensor 0 "Sensor_nicht_verbaut" 1 "Quertraeger_montiert" 2 "Quertraeger_nicht_montiert" 3 "Fehler" ;
VAL_ 1629 ESP_Stoppverbot_Anz_08 0 "keine_Anzeige" 1 "Neigungsbegrenzung" ;
VAL_ 1629 HDC_Charisma_FahrPr 0 "keine_Funktion" 1 "Programm_1" 2 "Programm_2" 3 "Programm_3" 4 "Programm_4" 5 "Programm_5" 6 "Programm_6" 7 "Programm_7" 8 "Programm_8" 9 "Programm_9" 10 "Programm_10" 11 "Programm_11" 12 "Programm_12" 13 "Programm_13" 14 "Programm_14" 15 "Programm_15" ;
VAL_ 1629 HDC_Charisma_Status 0 "Init" 1 "verfuegbar" 2 "nicht_verfuegbar" 3 "asynchron_durch_Fahrerwunsch" ;
VAL_ 1629 BR_QBit_Reifenumfang 0 "gueltiger_Wert" 1 "Ersatz_Init_oder_Fehlerwert" ;
VAL_ 253 BR_Eingriffsmoment 1022 "Init" 1023 "Fehler" ;
VAL_ 253 ESP_PLA_Bremseingriff 0 "inaktiv" 1 "aktiv" ;
VAL_ 253 ESP_Diagnose 0 "ESP_nicht_in_Diagnose" 1 "ESP_in_Diagnose" ;
VAL_ 253 ESC_Reku_Freigabe 0 "keine_Freigabe_der_Rekuperation" 1 "Freigabe_der_Rekuperation" ;
VAL_ 253 ESC_v_Signal_Qualifier_High_Low 0 "Gueteschwelle_kleiner_1kmh" 1 "Gueteschwelle_kleiner_3kmh" 2 "Gueteschwelle_kleiner_5kmh" 3 "Gueteschwelle_kleiner_10kmh" 4 "Gueteschwelle_kleiner_20kmh" 5 "Gueteschwelle_groessergleich_20kmh" 6 "Init" 7 "Fehler" ;
VAL_ 253 ESP_Vorsteuerung 0 "keine_Vorsteuerung_aktiv" 1 "Vorsteuerung_aktiv" ;
VAL_ 253 ESP_AWV3_Brems_aktiv 0 "inaktiv" 1 "aktiv" ;
VAL_ 253 OBD_Schlechtweg 0 "kein_Schlechtweg_erkannt" 1 "Schlechtweg_erkannt" ;
VAL_ 253 OBD_QBit_Schlechtweg 0 "gueltiger_Wert" 1 "Ersatz_Init_oder_Fehlerwert" ;
VAL_ 253 ESP_v_Signal 65533 "Unterspannung" 65534 "Init" 65535 "Fehler" ;
VAL_ 253 ASR_Tastung_passiv 0 "ASR_aktiviert" 1 "ASR_passiv_getastet_oder_Schwellen_geaendert" ;
VAL_ 253 ESP_Tastung_passiv 0 "ESP_aktiviert" 1 "ESP_passiv_getastet_oder_Schwellen_geaendert" ;
VAL_ 253 ESP_Systemstatus 0 "iO" 1 "Fehler" ;
VAL_ 253 ASR_Schalteingriff 0 "keine_Anforderung" 1 "ASR_Schaltkennfeld" 2 "Rueckschaltung" 3 "Schaltverbot" ;
VAL_ 253 ESP_Haltebestaetigung 0 "kein_sicheres_Halten" 1 "sicheres_Halten" ;
VAL_ 253 ESP_MKB_Abbruch_Geschw 0 "MKB_nicht_beendet_wg_v_Schwelle" 1 "MKB_beendet_wg_v_Schwelle" ;
VAL_ 253 ESP_QBit_v_Signal 0 "gueltiger_Wert" 1 "Ersatz_Init_oder_Fehlerwert" ;
VAL_ 253 ABS_Bremsung 0 "keine_ABS_Regelung" 1 "ABS_Regelung_aktiv" ;
VAL_ 253 ASR_Anf 0 "keine_Anforderung" 1 "ASR_Anforderung" ;
VAL_ 253 MSR_Anf 0 "keine Anfoderung" 1 "MSR-Anforderung" ;
VAL_ 253 EBV_Eingriff 0 "kein_EBV_Eingriff" 1 "EBV_Eingriff" ;
VAL_ 253 EDS_Eingriff 0 "kein_EDS_Eingriff" 1 "EDS_Eingriff" ;
VAL_ 253 ESP_Eingriff 0 "kein_ESP_Eingriff" 1 "ESP_Eingriff_aktiv" ;
VAL_ 253 ESP_ASP 0 "inaktiv" 1 "aktiv" ;
VAL_ 253 ESP_Anhaltevorgang_ACC_aktiv 0 "inaktiv" 1 "aktiv" ;
VAL_ 795 ESP_Lampe 0 "Aus" 1 "Ein" ;
VAL_ 795 ABS_Lampe 0 "Aus" 1 "Ein" ;
VAL_ 795 BK_Lampe_02 0 "aus" 1 "Typ1_ein_statisch" 2 "Typ2_ein_statisch" 3 "Warnung" ;
VAL_ 795 TC_Lampe 0 "Aus" 1 "Ein" ;
VAL_ 795 ESP_m_Raddrehz 32765 "Unterspannung" 32766 "Init" 32767 "Fehler" ;
VAL_ 795 ESP_Textanzeigen_03 0 "kein_Text" 1 "ESP_Stoerung" 2 "ABS_Stoerung" 3 "ESP_ABS_Stoerung" 4 "Werkstatt_Bremse" 5 "ASR_Stoerung" 6 "ESP_switched_off" 7 "ASR_off" 8 "ESP_ASR_on" 10 "keine_Bremskraftverstaerkung" 11 "ASR_aktiviert" 12 "ABS_ASR_Stoerung" 15 "ESP_offroad" 17 "ESP_sport" 18 "ESP_Zwangsaktivierung" 19 "ESP_Taster_Info" 20 "TC_aktiv" 21 "reserviert_fuer_Verlwarn" 22 "TC_switched_off" 23 "Verlwarn_akt_Rollsicher_inakt" 24 "ESP_SuperSport" 25 "ESP_Offroad_nicht_verfuegbar" ;
VAL_ 795 ESP_Meldungen 0 "keine_Anzeige" 1 "Autohold_Hinweis_1" 2 "Stoerung_Autohold" 3 "Stoerung_Hillholder" 4 "Uebernehmen" 5 "Autohold_aus" 6 "Autohold_Hinweis_2" ;
VAL_ 795 ESP_Fehlerstatus_Wegimp 0 "Wegimpulse_iO" 1 "Fehler" ;
VAL_ 795 ESP_Wegimp_Ueberlauf 0 "Reset_und_kein_Ueberlauf" 1 "mindestens_1x_Ueberlauf" ;
VAL_ 795 ESP_QBit_Wegimp_VA 0 "gueltiger_Wert" 1 "Ersatz_Init_oder_Fehlerwert" ;
VAL_ 795 ESP_HDC_FktLampe 0 "Aus" 1 "Ein" ;
VAL_ 795 ESP_Off_Lampe 0 "Lampe_aus" 1 "Lampe_ein" ;
VAL_ 795 ESP_HDC_Regelgeschw 0 "nicht_verbaut" 125 "HDC_Standby" 126 "Init" 127 "Fehler" ;
VAL_ 795 ESP_BKV_Warnung 0 "keine_Anzeige" 1 "keine_Bremskraftverstaerkung" ;
VAL_ 2589283617 EDS_Charisma_FahrPr 0 "keine_Funktion" 1 "Programm_1" 2 "Programm_2" 3 "Programm_3" 4 "Programm_4" 5 "Programm_5" 6 "Programm_6" 7 "Programm_7" 8 "Programm_8" 9 "Programm_9" 10 "Programm_10" 11 "Programm_11" 12 "Programm_12" 13 "Programm_13" 14 "Programm_14" 15 "Programm_15" ;
VAL_ 2589283617 EDS_Charisma_Status 0 "Init" 1 "verfuegbar" 2 "nicht_verfuegbar" 3 "asynchron_durch_Fahrerwunsch" ;
VAL_ 2589283617 HHC_Charisma_Status 0 "Init" 1 "verfuegbar" 2 "nicht_verfuegbar" 3 "asynchron_durch_Fahrerwunsch" ;
VAL_ 2589283617 HHC_Charisma_FahrPr 0 "keine_Funktion" 1 "Programm_1" 2 "Programm_2" 3 "Programm_3" 4 "Programm_4" 5 "Programm_5" 6 "Programm_6" 7 "Programm_7" 8 "Programm_8" 9 "Programm_9" 10 "Programm_10" 11 "Programm_11" 12 "Programm_12" 13 "Programm_13" 14 "Programm_14" 15 "Programm_15" ;
VAL_ 2589283617 RLE_Anzeigen 0 "keine_Anzeige" 1 "Rad_lose_allgemein" 2 "Rad_VL_lose" 3 "Rad_VR_lose" 4 "Rad_HL_lose" 5 "Rad_HR_lose" 6 "RLE_Pruefphase" 7 "RLE_Systemstoerung" ;
VAL_ 2589283617 ESC_Lernfreigabe_Abrollumfang 0 "keine_Lernfreigabe" 1 "Lernfreigabe" ;
VAL_ 2589283617 ESC_Texte_eBKV_Betaetigung 0 "keine_Anzeige" 1 "Halten_ueber_Schaltwippen_aktiv" 2 "Beide_Schaltwippen_betaetigen" 3 "Abbr_Halten_ueber_Schaltwippen" 4 "Bremspedal_betaetigen" 5 "Fahrpedal_loesen_Bremse_treten" ;
VAL_ 2589283617 ESC_MBK_Meldungen 0 "kein_Text" 1 "MBK_Hinweis_aktiv" 2 "MBK_Eskalation1_aktiv" ;
VAL_ 2589283617 ESC_Anf_KV 0 "kein_Oeffnen" 1 "Oeffnen" ;
VAL_ 2589283617 ESC_FBA_Meldungen 0 "kein_Text" 1 "FBA_Warnung_aktiv_MT" 2 "FBA_Warnung_aktiv_AT" ;
VAL_ 2589283617 DBK_Fahrerwarnung 0 "kein_Anfordern" 1 "Warnung_Aufforderung_Anhalten" 2 "Warnung_Aufforderung_Werkstatt" 3 "nicht_belegt" ;
VAL_ 2589283617 ESP_Status_Bremsentemp_Anz 0 "Init" 1 "kalt" 2 "warm" 3 "heiss" 4 "ueberhitzt" 5 "nass" 7 "Fehler" ;
VAL_ 2589283617 ESP_Off_Anf_KBI 0 "keine_Anzeige" 1 "Anzeige_ESP_off_Popup" ;
VAL_ 2589283617 FBC_Fahrerwarnung 0 "kein_Anfordern" 1 "Warnung_Bremse_heiss" 2 "Warnung_Bremse_ueberhitzt" ;
VAL_ 2589283684 GRA_FoD_Status 0 "Init" 1 "Funktion_inaktiv" 2 "Funktion_aktiv" ;
VAL_ 2589283684 FoD_Transmission_Info 0 "Initwert" 1 "start_transmission" 2 "finish_transmission" ;
VAL_ 986 ESP_05_alt 0 "aktuell" 1 "veraltet" ;
VAL_ 986 EPB_01_alt 0 "aktuell" 1 "veraltet" ;
VAL_ 986 ESP_21_alt 0 "aktuell" 1 "veraltet" ;
VAL_ 986 LWI_01_alt 0 "aktuell" 1 "veraltet" ;
VAL_ 986 Parkhilfe_01_alt 0 "aktuell" 1 "veraltet" ;
VAL_ 986 Kamera_Status_alt 0 "aktuell" 1 "veraltet" ;
VAL_ 986 ESP_HDC_Standby 0 "HDC_Funktion_nicht_im_Standby" 1 "HDC_Funktion_im_Standby" ;
VAL_ 986 ECD_Bremslicht 0 "Aus" 1 "Ein" ;
VAL_ 986 EPB_Status 0 "offen" 1 "Bremse_geschl_(Spannkraft_voll/reduziert)" 2 "Aktuator_im_Lauf" 3 "Fehler_oder_unbekannt" ;
VAL_ 986 EPB_QBit_Pedalweg_Kuppl 0 "gültiger Wert" 1 "Ersatz-, Init- oder Fehlerwert" ;
VAL_ 986 ESP_QBit_v_Signal 0 "gueltiger_Wert" 1 "Ersatz_Init_oder_Fehlerwert" ;
VAL_ 986 ABS_Bremsung 0 "keine_ABS_Regelung" 1 "ABS_Regelung_aktiv" ;
VAL_ 986 ESP_Eingriff 0 "kein_ESP_Eingriff" 1 "ESP_Eingriff_aktiv" ;
VAL_ 986 Kamera_FSH_aktiv 0 "Kamera_Frontscheibenheizung_nicht_aktiviert" 1 "Kamera_Frontscheibenheizung_aktiviert" ;
VAL_ 986 EPB_Pedalweg_Kuppl 0 "Init" 255 "Fehler" ;
VAL_ 986 ESP_v_Signal 65533 "Unterspannung" 65534 "Init" 65535 "Fehler" ;
VAL_ 986 LWI_QBit_Lenkradwinkel 0 "gültiger Wert" 1 "ausserhalb der Spezifikation" ;
VAL_ 986 LWI_Sensorstatus 0 "iO" 1 "nicht kalibriert" ;
VAL_ 986 LWI_VZ_Lenkradwinkel 0 "positiv_links_von_der_Nullstellung" 1 "negativ" ;
VAL_ 986 LWI_Lenkradwinkel 8190 "Init" 8191 "Fehler" ;
VAL_ 986 PH_Anf_Audioabsenkung 0 "Keine_Audioabsenkung" 1 "Anforderung_Audioabsenkung" ;
VAL_ 986 PH_Systemzustand 0 "Anlage aus" 1 "Anlage durch einlegen R-Gang aktiviert" 2 "Anlage manuell durch Taster aktiviert" 3 "Anlage automatisch aktiviert" 4 "Anlage durch ARA aktiviert" 6 "Init - Initialisierungsphase nach Kl. 15 ein / Reset" 7 "Fehler-/gestört Zustand, System noch aktiv" ;
VAL_ 986 PH_Taster 0 "Taster_nicht_gedrueckt" 1 "Taster_gedrueckt" 2 "reserviert" 3 "Fehler" ;
VAL_ 986 ESP_MKB_Abbruch_Geschw 0 "MKB_nicht_beendet_wg_v_Schwelle" 1 "MKB_beendet_wg_v_Schwelle" ;
VAL_ 986 PLA_Anf_Aufschaltung_RVC 0 "Keine_RVC_Aufschalteanf" 1 "RVC_Aufschalteanforderung" ;
VAL_ 988 Motor_12_alt 0 "aktuell" 1 "veraltet" ;
VAL_ 988 ESP_07_alt 0 "aktuell" 1 "veraltet" ;
VAL_ 988 Getriebe_11_alt 0 "aktuell" 1 "veraltet" ;
VAL_ 988 Getriebe_13_alt 0 "aktuell" 1 "veraltet" ;
VAL_ 988 Getriebe_17_alt 0 "aktuell" 1 "veraltet" ;
VAL_ 988 TSK_06_alt 0 "aktuell" 1 "veraltet" ;
VAL_ 988 Getriebe_14_alt 0 "aktuell" 1 "veraltet" ;
VAL_ 988 ESP_50_alt 0 "aktuell" 1 "veraltet" ;
VAL_ 988 MO_QBit_Drehzahl_01 0 "gueltiger_Wert" 1 "Ersatz_Init_oder_Fehlerwert" ;
VAL_ 988 MKE_Texte 0 "keine_Anzeige" 1 "Warnstufe_1" 2 "Warnstufe_2" ;
VAL_ 988 MKE_Stufe 0 "deaktiviert" 1 "nicht_verfügbar" 2 "Stufe_1" 3 "Stufe_2" 4 "Stufe_3" 5 "Stufe_4" 6 "reserviert" 7 "reserviert" ;
VAL_ 988 TSK_Hauptschalter_GRA_ACC 0 "Init" 1 "Aus" 2 "Ein" 3 "Fehler" ;
VAL_ 988 TSK_Status 0 "Hauptschalter_aus" 1 "Init" 2 "passiv" 3 "aktiv" 4 "Uebertreten" 5 "brake_only_Mode" 6 "reversibel_aus" 7 "irreversibel_aus" ;
VAL_ 988 EPB_Schalterposition 0 "keine Fahreranforderung" 1 "Fahreranforderung Öffnen" 2 "Fahreranforderung Schließen" 3 "Fehler" ;
VAL_ 988 GE_LaunchControl 0 "inaktiv" 1 "aktiv" ;
VAL_ 988 GE_Fahrstufe 0 "Zwischenstellung" 1 "Init" 5 "Position_P" 6 "Position_R" 7 "Position_N" 8 "Position_D" 9 "Position_S" 10 "Effizienz" 13 "Tipp_in_S" 14 "Tipp_in_D" 15 "Fehler" ;
VAL_ 988 GE_Ursache_Fahrstufe_N 0 "Fahrstufe_N_mit_Fahrerwunsch" 1 "Fahrstufe_N_ohne_Fahrerwunsch" ;
VAL_ 988 GE_Notlauf 0 "kein Notlauf / Init" 1 "Getriebe im Notlauf" ;
VAL_ 988 ESP_Rollenmodus_Deaktivieren 0 "keine_Aenderung" 1 "Abbruch" ;
VAL_ 988 GE_Freilauf_Status 0 "Freilauf_inaktiv_aber_moeglich" 1 "Freilauf_aktiv" 2 "Freilauf_nicht_moegl_1Verhinderer" 3 "Freilauf_nicht_moegl_gr_1Verhinderer" 7 "Fehler" ;
VAL_ 988 GE_Sperr_Info_WFS 0 "nicht_gesperrt" 1 "gesperrt" ;
VAL_ 988 TSK_Limiter_ausgewaehlt 0 "kein_Limiter_ausgewaehlt" 1 "Limiter_ausgewaehlt" ;
VAL_ 988 GE_Veto_Rollfaehigkeit 0 "kein_Veto__Rollfaehigkeit_moegl" 1 "Veto__Rollfaehigkeit_nicht_moegl" ;
VAL_ 988 EPB_Status_02 0 "offen" 1 "geschlossen_Parken" 2 "teilgespannt_Halten" 3 "im_Lauf_oeffnen" 4 "im_Lauf_schliessen" 5 "tbd" 6 "Init" 7 "unbekannt" ;
VAL_ 988 ACC_Status_ACC 0 "ACC_OFF_Hauptschalter_aus" 1 "ACC_INIT" 2 "ACC_STANDBY" 3 "ACC_AKTIV_regelt" 4 "ACC_OVERRIDE" 5 "ACC_Abschaltreaktion" 6 "reversibler_Fehler_im_ACC_System" 7 "irreversibler_Fehler_im_ACC_System" ;
VAL_ 988 ACC_18_alt 0 "aktuell" 1 "veraltet" ;
VAL_ 988 Bel_DiETa_Mode2 0 "LED_Aus" 1 "LED_Ein" 2 "LED_blinken" 3 "Fehler" ;
VAL_ 1002 ESP_05_alt 0 "aktuell" 1 "veraltet" ;
VAL_ 1002 Getriebe_14_alt 0 "aktuell" 1 "veraltet" ;
VAL_ 1002 Motor_11_alt 0 "aktuell" 1 "veraltet" ;
VAL_ 1002 Motor_20_alt 0 "aktuell" 1 "veraltet" ;
VAL_ 1002 EBKV_03_alt 0 "aktuell" 1 "veraltet" ;
VAL_ 1002 AWV_03_alt 0 "aktuell" 1 "veraltet" ;
VAL_ 1002 AWV_Verz_Freigabe 0 "Verzoegerung_nicht_freigeben" 1 "Verzoegerung_freigeben" ;
VAL_ 1002 AWV_Verz_Anf 1023 "keine_Anforderung" ;
VAL_ 1002 Bel_DiETa_Mode 0 "LED_Aus" 1 "LED_Ein" 2 "LED_blinken" 3 "Fehler" ;
VAL_ 1002 PaCo_DiETa_LED 0 "LED_Inactive" 1 "LED_Active" 2 "LED_Flashing" 3 "Error" ;
VAL_ 1002 RTM_Warnstatus 0 "keine_Warnung" 1 "Warnstufe_ChNational" 2 "reserviert" 3 "reserviert" ;
VAL_ 1002 EBKV_Fahrer_bremst 0 "Fahrer_bremst_nicht_selbst" 1 "Fahrer_will_selbst_bremsen" ;
VAL_ 1002 AWV_Zielobjekttyp 0 "Unbekannt" 1 "Fussgaenger" 2 "Zweirad" 3 "PKW" 4 "LKW" 5 "reserviert" 6 "reserviert" 7 "reserviert" 8 "reserviert" 9 "reserviert" 10 "reserviert" 11 "reserviert" 12 "reserviert" 13 "reserviert" 14 "kein_relevantes_Obj" 15 "init" ;
VAL_ 1002 ESP_Bremsdruck 1023 "Fehler" ;
VAL_ 1002 MO_Mom_Ist_Summe 1022 "Init" ;
VAL_ 1002 MO_Fahrpedalrohwert_01 255 "Fehler" ;
VAL_ 1002 GE_Sumpftemperatur 255 "Fehler" ;
VAL_ 1004 HDSG_01_alt 0 "aktuell" 1 "veraltet" ;
VAL_ 1004 ACC_02_alt 0 "aktuell" 1 "veraltet" ;
VAL_ 1004 BCM_01_alt 0 "aktuell" 1 "veraltet" ;
VAL_ 1004 Klima_11_alt 0 "aktuell" 1 "veraltet" ;
VAL_ 1004 Motor_17_alt 0 "aktuell" 1 "veraltet" ;
VAL_ 1004 LDW_02_alt 0 "aktuell" 1 "veraltet" ;
VAL_ 1004 EM1_01_alt 0 "aktuell" 1 "veraltet" ;
VAL_ 1004 EM2_01_alt 0 "aktuell" 1 "veraltet" ;
VAL_ 1004 LIN_2_alt 0 "aktuell" 1 "veraltet" ;
VAL_ 1004 Getriebe_50_alt 0 "aktuell" 1 "veraltet" ;
VAL_ 1004 GE_Status_Kraftschluss 0 "offen_kein_Kraftschluss" 1 "offen_mit_Kraftschluss" 2 "schlupfend_geregelt" 3 "abgesichert_offen_kein_Kraftschl" 4 "geschlossen_mit_Mikroschlupf" 5 "geschlossen_mit_Ueberanpressung" 6 "sonstige_Fehler" 7 "fehlerhaft_geschlossen" ;
VAL_ 1004 MFL_Touch_Event 0 "nicht_betaetigt" 1 "Tippen" 2 "Wischen_Slide" 3 "Geste" 4 "Doppeltippen" 5 "Longpress_1" 6 "Longpress_2" 7 "Longpress_3" 8 "Press" 9 "Strongpress" 10 "reserviert" 11 "reserviert" 12 "reserviert" 13 "reserviert" 14 "Taktgeber_Inkrement" 15 "Fehler" ;
VAL_ 1004 MO_NGS_Position 0 "Neutralposition_nicht_erkannt" 1 "Neutralposition_erkannt" ;
VAL_ 1004 MO_NGS_Status 0 "nicht_verbaut" 1 "nicht_plausibilisiert" 2 "plausibilisiert" 3 "Fehler" ;
VAL_ 1004 HC_Uss_Anforderung 0 "Ultraschallsensoren Aus" 1 "Ultraschallsensoren An" ;
VAL_ 1004 BCM_Waschwasser_Sensor 0 "OK" 1 "Waschwasser_unter_min" ;
VAL_ 1004 BCM_Offroad_Taste 0 "Taster_nicht_betaetigt" 1 "Taster_betaetigt" ;
VAL_ 1004 EM1_Status_DrzEingriff 0 "kein_Eingriff" 1 "Eingriff_Max_Drehzahlregler" 2 "Eingriff_Min_Drehzahlregler" 3 "Fehler" ;
VAL_ 1004 KL_Vorwarn_Komp_ein 0 "Init" 1 "Vorwarnung_Kompressor_ein" ;
VAL_ 1004 HD_Endstellung_oben 1 "HD in Endstellung oben (offen)" ;
VAL_ 1004 HD_Endstellung_unten 0 "Init" 1 "HD in Endstellung unten (geschlossen)" ;
VAL_ 1004 EM2_Status_DrzEingriff 0 "kein_Eingriff" 1 "Eingriff_Max_Drehzahlregler" 2 "Eingriff_Min_Drehzahlregler" 3 "Fehler" ;
VAL_ 1004 ACC_Status_Anzeige 0 "ACC_GRA_Hauptschalter_aus" 1 "ACC_in_Init_nicht_bei_GRA" 2 "ACC_GRA_passiv" 3 "ACC_GRA_aktiv" 4 "ACC_GRA_im_Hintergrund_uebertreten" 5 "ACC_GRA_Abschaltreaktion" 6 "ACC_reversibel_aus_nicht_bei_GRA" 7 "ACC_GRA_irreversibel_aus" ;
VAL_ 879 GNSS_Breite_Ortung 134217726 "Init" 134217727 "Fehler" ;
VAL_ 879 GNSS_Richtung_Breite_Ortung 0 "Nord" 1 "Sued" ;
VAL_ 879 GNSS_Laenge_Ortung 268435454 "Init" 268435455 "Fehler" ;
VAL_ 879 GNSS_Richtung_Laenge_Ortung 0 "Ost" 1 "West" ;
VAL_ 879 GNSS_Ortung_FIX_Typ 0 "Init" 1 "No_Fix" 2 "2D_Fix" 3 "3D_Fix" ;
VAL_ 879 GNSS_Fehlerzustand 0 "Kein_Fehler" 1 "P_Mode" 2 "T_Mode" 3 "GNSS_Receiver_Problem" 4 "Kommunikationsproblem_im_SG" 5 "Start_GNSS_Receiver" 6 "GNSS_Receiver_aus" 7 "SG_spezifischer_Fehler" ;
VAL_ 884 GNSS_Ortung_Latenz 1022 "Init" 1023 "Fehler" ;
VAL_ 884 GNSS_Ortung_Ausrichtung 4094 "Init" 4095 "Fehler" ;
VAL_ 884 GNSS_Ortung_2D_Geschw_ue_Grund 510 "Init" 511 "Fehler" ;
VAL_ 884 GNSS_Ortung_Noerdliche_Geschw 1022 "Init" 1023 "Fehler" ;
VAL_ 884 GNSS_Ortung_Oestliche_Geschw 1022 "Init" 1023 "Fehler" ;
VAL_ 884 GNSS_Ortung_Vertikale_Geschw 1022 "Init" 1023 "Fehler" ;
